VERSION ""

NS_ :

BS_:

BU_: CLU AMP H_U CGW TMU

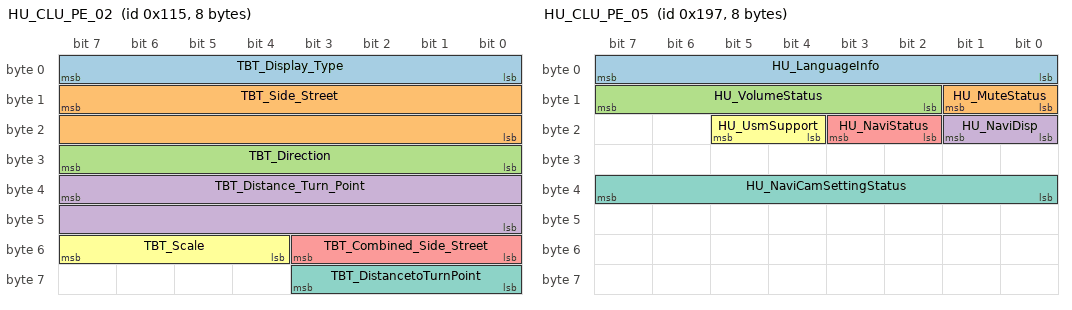
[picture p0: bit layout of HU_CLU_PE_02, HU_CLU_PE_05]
BO_ 277 HU_CLU_PE_02: 8 H_U
 SG_ TBT_Display_Type : 7|8@0+ (1,0) [0|0] ""  CLU
 SG_ TBT_Side_Street : 15|16@0+ (1,0) [0|0] ""  CLU
 SG_ TBT_Direction : 31|8@0+ (7.5,0) [0|352.5] "Degree"  CLU
 SG_ TBT_Distance_Turn_Point : 39|16@0+ (1,0) [0|0] "m"  CLU
 SG_ TBT_Combined_Side_Street : 51|4@0+ (1,0) [0|0] ""  CLU
 SG_ TBT_Scale : 55|4@0+ (1,0) [0|0] ""  CLU
 SG_ TBT_DistancetoTurnPoint : 59|4@0+ (1,0) [0|0] "times"  CLU

BO_ 406 HU_CLU_PE_04: 8 H_U
 SG_ HD_SPS_ChannelNo : 15|4@0+ (1,0) [0|0] ""  CLU
 SG_ SXM_ChannelNo : 25|10@0+ (1,0) [0|999] ""  AMP,CLU

BO_ 407 HU_CLU_PE_05: 8 H_U
 SG_ HU_LanguageInfo : 7|8@0+ (1,0) [0|0] ""  CGW,CLU
 SG_ HU_MuteStatus : 9|2@0+ (1,0) [0|0] ""  CLU
 SG_ HU_VolumeStatus : 15|6@0+ (1,0) [0|0] ""  CLU
 SG_ HU_NaviDisp : 17|2@0+ (1,0) [0|0] ""  CLU
 SG_ HU_NaviStatus : 19|2@0+ (1,0) [0|0] ""  CGW,CLU
 SG_ HU_UsmSupport : 21|2@0+ (1,0) [0|0] ""  CLU
 SG_ HU_NaviCamSettingStatus : 39|8@0+ (1,0) [0|0] ""  CGW,CLU

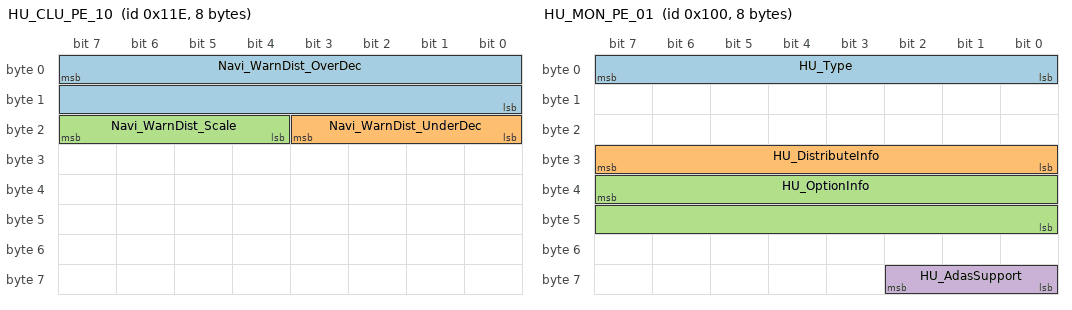
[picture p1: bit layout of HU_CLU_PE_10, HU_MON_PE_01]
BO_ 286 HU_CLU_PE_10: 8 H_U
 SG_ Navi_WarnDist_OverDec : 7|16@0+ (1,0) [0|0] ""  CLU
 SG_ Navi_WarnDist_UnderDec : 19|4@0+ (1,0) [0|0] ""  CLU
 SG_ Navi_WarnDist_Scale : 23|4@0+ (1,0) [0|0] ""  CLU

BO_ 256 HU_MON_PE_01: 8 H_U
 SG_ HU_Type : 7|8@0+ (1,0) [0|0] ""  AMP,CGW,CLU
 SG_ HU_DistributeInfo : 31|8@0+ (1,0) [0|0] ""  AMP,CGW,CLU
 SG_ HU_OptionInfo : 39|16@0+ (1,0) [0|0] ""  AMP,CGW,CLU
 SG_ HU_AdasSupport : 58|3@0+ (1,0) [0|0] ""  CGW,CLU

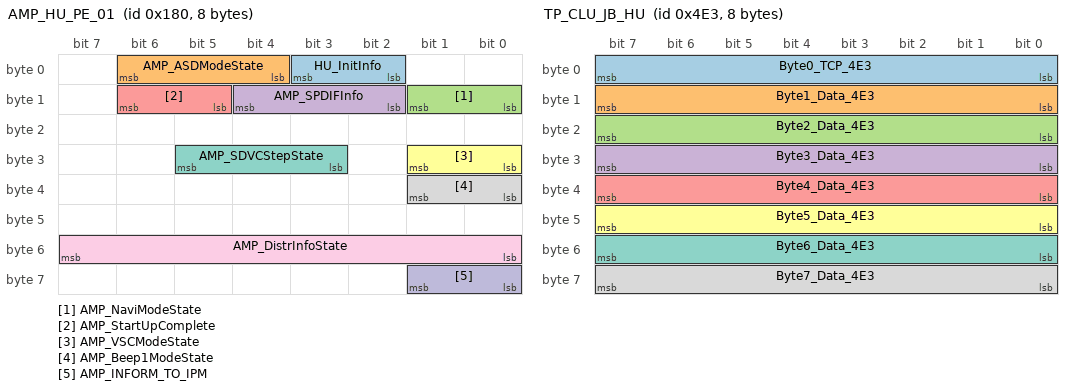
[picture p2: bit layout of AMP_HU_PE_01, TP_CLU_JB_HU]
BO_ 384 AMP_HU_PE_01: 8 AMP
 SG_ HU_InitInfo : 3|2@0+ (1,0) [0|0] ""  CLU,H_U
 SG_ AMP_ASDModeState : 6|3@0+ (1,0) [0|0] ""  CLU,H_U
 SG_ AMP_NaviModeState : 9|2@0+ (1,0) [0|0] ""  CLU,H_U
 SG_ AMP_SPDIFInfo : 12|3@0+ (1,0) [0|0] ""  CLU,H_U
 SG_ AMP_StartUpComplete : 14|2@0+ (1,0) [0|0] ""  CLU,H_U
 SG_ AMP_VSCModeState : 25|2@0+ (1,0) [0|0] ""  CLU,H_U
 SG_ AMP_SDVCStepState : 29|3@0+ (1,0) [0|0] ""  CLU,H_U
 SG_ AMP_Beep1ModeState : 33|2@0+ (1,0) [0|0] ""  CLU,H_U
 SG_ AMP_DistrInfoState : 55|8@0+ (1,0) [0|0] ""  CLU,H_U
 SG_ AMP_INFORM_TO_IPM : 57|2@0+ (1,0) [0|0] ""  CGW,CLU,H_U

BO_ 1251 TP_CLU_JB_HU: 8 CLU
 SG_ Byte0_TCP_4E3 : 7|8@0+ (1,0) [0|0] ""  H_U
 SG_ Byte1_Data_4E3 : 15|8@0+ (1,0) [0|0] ""  H_U
 SG_ Byte2_Data_4E3 : 23|8@0+ (1,0) [0|0] ""  H_U
 SG_ Byte3_Data_4E3 : 31|8@0+ (1,0) [0|0] ""  H_U
 SG_ Byte4_Data_4E3 : 39|8@0+ (1,0) [0|0] ""  H_U
 SG_ Byte5_Data_4E3 : 47|8@0+ (1,0) [0|0] ""  H_U
 SG_ Byte6_Data_4E3 : 55|8@0+ (1,0) [0|0] ""  H_U
 SG_ Byte7_Data_4E3 : 63|8@0+ (1,0) [0|0] ""  H_U

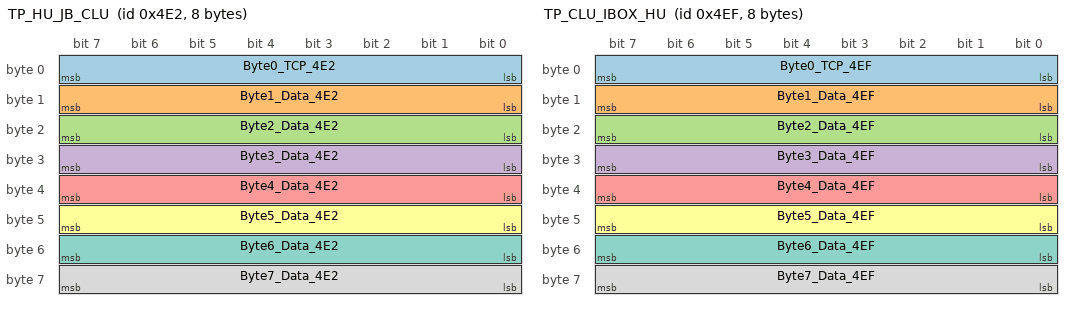
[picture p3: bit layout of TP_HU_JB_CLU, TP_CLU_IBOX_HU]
BO_ 1250 TP_HU_JB_CLU: 8 H_U
 SG_ Byte0_TCP_4E2 : 7|8@0+ (1,0) [0|0] ""  CLU
 SG_ Byte1_Data_4E2 : 15|8@0+ (1,0) [0|0] ""  CLU
 SG_ Byte2_Data_4E2 : 23|8@0+ (1,0) [0|0] ""  CLU
 SG_ Byte3_Data_4E2 : 31|8@0+ (1,0) [0|0] ""  CLU
 SG_ Byte4_Data_4E2 : 39|8@0+ (1,0) [0|0] ""  CLU
 SG_ Byte5_Data_4E2 : 47|8@0+ (1,0) [0|0] ""  CLU
 SG_ Byte6_Data_4E2 : 55|8@0+ (1,0) [0|0] ""  CLU
 SG_ Byte7_Data_4E2 : 63|8@0+ (1,0) [0|0] ""  CLU

BO_ 1263 TP_CLU_IBOX_HU: 8 CLU
 SG_ Byte0_TCP_4EF : 7|8@0+ (1,0) [0|0] ""  H_U
 SG_ Byte1_Data_4EF : 15|8@0+ (1,0) [0|0] ""  H_U
 SG_ Byte2_Data_4EF : 23|8@0+ (1,0) [0|0] ""  H_U
 SG_ Byte3_Data_4EF : 31|8@0+ (1,0) [0|0] ""  H_U
 SG_ Byte4_Data_4EF : 39|8@0+ (1,0) [0|0] ""  H_U
 SG_ Byte5_Data_4EF : 47|8@0+ (1,0) [0|0] ""  H_U
 SG_ Byte6_Data_4EF : 55|8@0+ (1,0) [0|0] ""  H_U
 SG_ Byte7_Data_4EF : 63|8@0+ (1,0) [0|0] ""  H_U

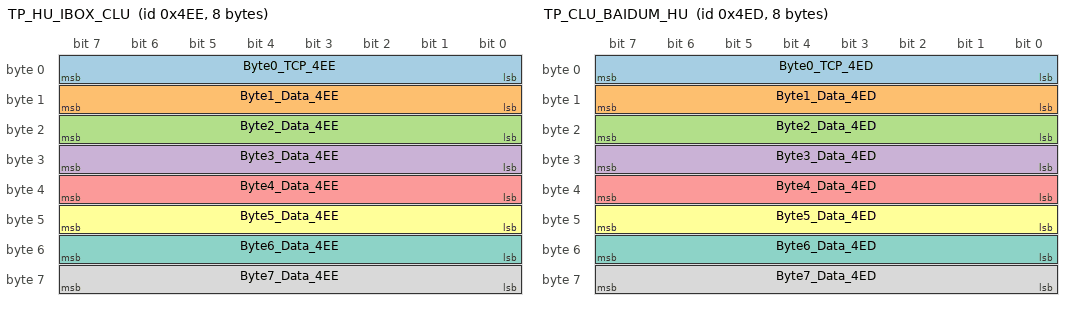
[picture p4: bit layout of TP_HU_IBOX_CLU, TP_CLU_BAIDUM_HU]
BO_ 1262 TP_HU_IBOX_CLU: 8 H_U
 SG_ Byte0_TCP_4EE : 7|8@0+ (1,0) [0|0] ""  CLU
 SG_ Byte1_Data_4EE : 15|8@0+ (1,0) [0|0] ""  CLU
 SG_ Byte2_Data_4EE : 23|8@0+ (1,0) [0|0] ""  CLU
 SG_ Byte3_Data_4EE : 31|8@0+ (1,0) [0|0] ""  CLU
 SG_ Byte4_Data_4EE : 39|8@0+ (1,0) [0|0] ""  CLU
 SG_ Byte5_Data_4EE : 47|8@0+ (1,0) [0|0] ""  CLU
 SG_ Byte6_Data_4EE : 55|8@0+ (1,0) [0|0] ""  CLU
 SG_ Byte7_Data_4EE : 63|8@0+ (1,0) [0|0] ""  CLU

BO_ 1261 TP_CLU_BAIDUM_HU: 8 CLU
 SG_ Byte0_TCP_4ED : 7|8@0+ (1,0) [0|0] ""  H_U
 SG_ Byte1_Data_4ED : 15|8@0+ (1,0) [0|0] ""  H_U
 SG_ Byte2_Data_4ED : 23|8@0+ (1,0) [0|0] ""  H_U
 SG_ Byte3_Data_4ED : 31|8@0+ (1,0) [0|0] ""  H_U
 SG_ Byte4_Data_4ED : 39|8@0+ (1,0) [0|0] ""  H_U
 SG_ Byte5_Data_4ED : 47|8@0+ (1,0) [0|0] ""  H_U
 SG_ Byte6_Data_4ED : 55|8@0+ (1,0) [0|0] ""  H_U
 SG_ Byte7_Data_4ED : 63|8@0+ (1,0) [0|0] ""  H_U

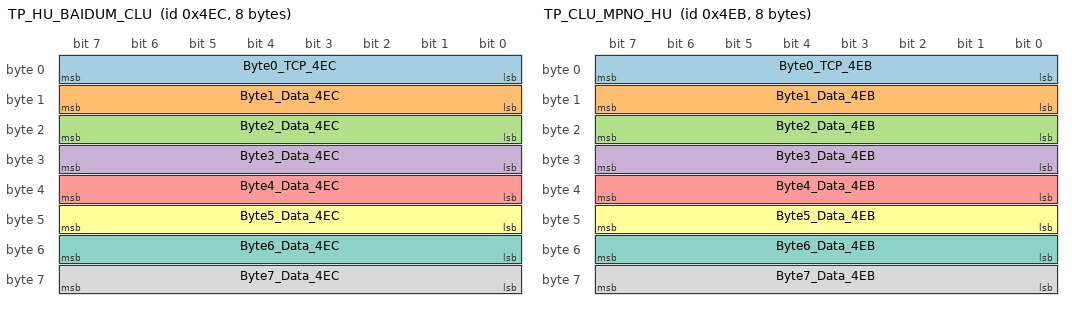
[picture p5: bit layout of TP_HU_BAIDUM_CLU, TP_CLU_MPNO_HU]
BO_ 1260 TP_HU_BAIDUM_CLU: 8 H_U
 SG_ Byte0_TCP_4EC : 7|8@0+ (1,0) [0|0] ""  CLU
 SG_ Byte1_Data_4EC : 15|8@0+ (1,0) [0|0] ""  CLU
 SG_ Byte2_Data_4EC : 23|8@0+ (1,0) [0|0] ""  CLU
 SG_ Byte3_Data_4EC : 31|8@0+ (1,0) [0|0] ""  CLU
 SG_ Byte4_Data_4EC : 39|8@0+ (1,0) [0|0] ""  CLU
 SG_ Byte5_Data_4EC : 47|8@0+ (1,0) [0|0] ""  CLU
 SG_ Byte6_Data_4EC : 55|8@0+ (1,0) [0|0] ""  CLU
 SG_ Byte7_Data_4EC : 63|8@0+ (1,0) [0|0] ""  CLU

BO_ 1259 TP_CLU_MPNO_HU: 8 CLU
 SG_ Byte0_TCP_4EB : 7|8@0+ (1,0) [0|0] ""  H_U
 SG_ Byte1_Data_4EB : 15|8@0+ (1,0) [0|0] ""  H_U
 SG_ Byte2_Data_4EB : 23|8@0+ (1,0) [0|0] ""  H_U
 SG_ Byte3_Data_4EB : 31|8@0+ (1,0) [0|0] ""  H_U
 SG_ Byte4_Data_4EB : 39|8@0+ (1,0) [0|0] ""  H_U
 SG_ Byte5_Data_4EB : 47|8@0+ (1,0) [0|0] ""  H_U
 SG_ Byte6_Data_4EB : 55|8@0+ (1,0) [0|0] ""  H_U
 SG_ Byte7_Data_4EB : 63|8@0+ (1,0) [0|0] ""  H_U

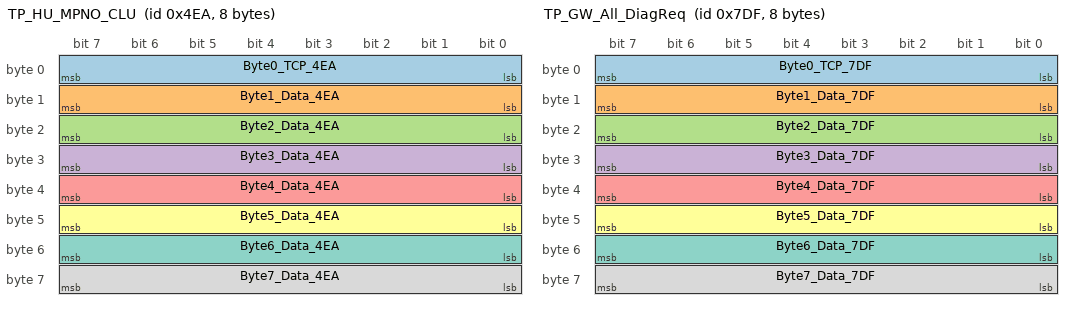
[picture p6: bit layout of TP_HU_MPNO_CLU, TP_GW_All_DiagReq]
BO_ 1258 TP_HU_MPNO_CLU: 8 H_U
 SG_ Byte0_TCP_4EA : 7|8@0+ (1,0) [0|0] ""  CLU
 SG_ Byte1_Data_4EA : 15|8@0+ (1,0) [0|0] ""  CLU
 SG_ Byte2_Data_4EA : 23|8@0+ (1,0) [0|0] ""  CLU
 SG_ Byte3_Data_4EA : 31|8@0+ (1,0) [0|0] ""  CLU
 SG_ Byte4_Data_4EA : 39|8@0+ (1,0) [0|0] ""  CLU
 SG_ Byte5_Data_4EA : 47|8@0+ (1,0) [0|0] ""  CLU
 SG_ Byte6_Data_4EA : 55|8@0+ (1,0) [0|0] ""  CLU
 SG_ Byte7_Data_4EA : 63|8@0+ (1,0) [0|0] ""  CLU

BO_ 2015 TP_GW_All_DiagReq: 8 CGW
 SG_ Byte0_TCP_7DF : 7|8@0+ (1,0) [0|0] ""  AMP,CLU,H_U,TMU
 SG_ Byte1_Data_7DF : 15|8@0+ (1,0) [0|0] ""  AMP,CLU,H_U,TMU
 SG_ Byte2_Data_7DF : 23|8@0+ (1,0) [0|0] ""  AMP,CLU,H_U,TMU
 SG_ Byte3_Data_7DF : 31|8@0+ (1,0) [0|0] ""  AMP,CLU,H_U,TMU
 SG_ Byte4_Data_7DF : 39|8@0+ (1,0) [0|0] ""  AMP,CLU,H_U,TMU
 SG_ Byte5_Data_7DF : 47|8@0+ (1,0) [0|0] ""  AMP,CLU,H_U,TMU
 SG_ Byte6_Data_7DF : 55|8@0+ (1,0) [0|0] ""  AMP,CLU,H_U,TMU
 SG_ Byte7_Data_7DF : 63|8@0+ (1,0) [0|0] ""  AMP,CLU,H_U,TMU

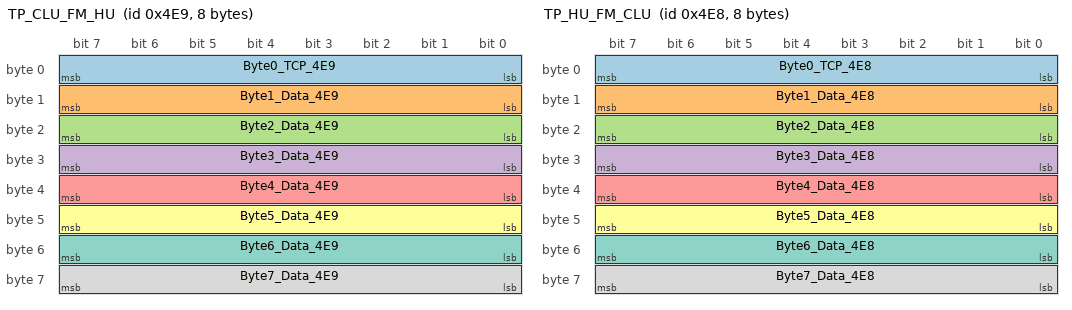
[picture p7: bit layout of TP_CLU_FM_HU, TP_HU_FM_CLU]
BO_ 1257 TP_CLU_FM_HU: 8 CLU
 SG_ Byte0_TCP_4E9 : 7|8@0+ (1,0) [0|0] ""  H_U
 SG_ Byte1_Data_4E9 : 15|8@0+ (1,0) [0|0] ""  H_U
 SG_ Byte2_Data_4E9 : 23|8@0+ (1,0) [0|0] ""  H_U
 SG_ Byte3_Data_4E9 : 31|8@0+ (1,0) [0|0] ""  H_U
 SG_ Byte4_Data_4E9 : 39|8@0+ (1,0) [0|0] ""  H_U
 SG_ Byte5_Data_4E9 : 47|8@0+ (1,0) [0|0] ""  H_U
 SG_ Byte6_Data_4E9 : 55|8@0+ (1,0) [0|0] ""  H_U
 SG_ Byte7_Data_4E9 : 63|8@0+ (1,0) [0|0] ""  H_U

BO_ 1256 TP_HU_FM_CLU: 8 H_U
 SG_ Byte0_TCP_4E8 : 7|8@0+ (1,0) [0|0] ""  CLU
 SG_ Byte1_Data_4E8 : 15|8@0+ (1,0) [0|0] ""  CLU
 SG_ Byte2_Data_4E8 : 23|8@0+ (1,0) [0|0] ""  CLU
 SG_ Byte3_Data_4E8 : 31|8@0+ (1,0) [0|0] ""  CLU
 SG_ Byte4_Data_4E8 : 39|8@0+ (1,0) [0|0] ""  CLU
 SG_ Byte5_Data_4E8 : 47|8@0+ (1,0) [0|0] ""  CLU
 SG_ Byte6_Data_4E8 : 55|8@0+ (1,0) [0|0] ""  CLU
 SG_ Byte7_Data_4E8 : 63|8@0+ (1,0) [0|0] ""  CLU

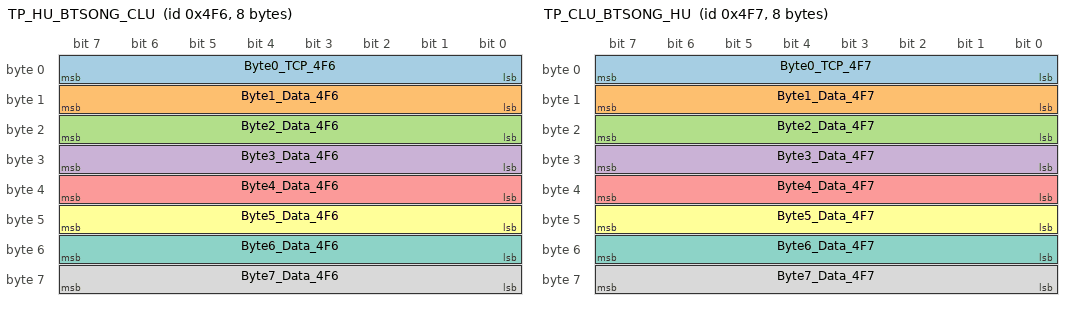
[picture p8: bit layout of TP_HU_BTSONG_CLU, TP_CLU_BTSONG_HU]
BO_ 1270 TP_HU_BTSONG_CLU: 8 H_U
 SG_ Byte0_TCP_4F6 : 7|8@0+ (1,0) [0|0] ""  CLU
 SG_ Byte1_Data_4F6 : 15|8@0+ (1,0) [0|0] ""  CLU
 SG_ Byte2_Data_4F6 : 23|8@0+ (1,0) [0|0] ""  CLU
 SG_ Byte3_Data_4F6 : 31|8@0+ (1,0) [0|0] ""  CLU
 SG_ Byte4_Data_4F6 : 39|8@0+ (1,0) [0|0] ""  CLU
 SG_ Byte5_Data_4F6 : 47|8@0+ (1,0) [0|0] ""  CLU
 SG_ Byte6_Data_4F6 : 55|8@0+ (1,0) [0|0] ""  CLU
 SG_ Byte7_Data_4F6 : 63|8@0+ (1,0) [0|0] ""  CLU

BO_ 1271 TP_CLU_BTSONG_HU: 8 CLU
 SG_ Byte0_TCP_4F7 : 7|8@0+ (1,0) [0|0] ""  H_U
 SG_ Byte1_Data_4F7 : 15|8@0+ (1,0) [0|0] ""  H_U
 SG_ Byte2_Data_4F7 : 23|8@0+ (1,0) [0|0] ""  H_U
 SG_ Byte3_Data_4F7 : 31|8@0+ (1,0) [0|0] ""  H_U
 SG_ Byte4_Data_4F7 : 39|8@0+ (1,0) [0|0] ""  H_U
 SG_ Byte5_Data_4F7 : 47|8@0+ (1,0) [0|0] ""  H_U
 SG_ Byte6_Data_4F7 : 55|8@0+ (1,0) [0|0] ""  H_U
 SG_ Byte7_Data_4F7 : 63|8@0+ (1,0) [0|0] ""  H_U

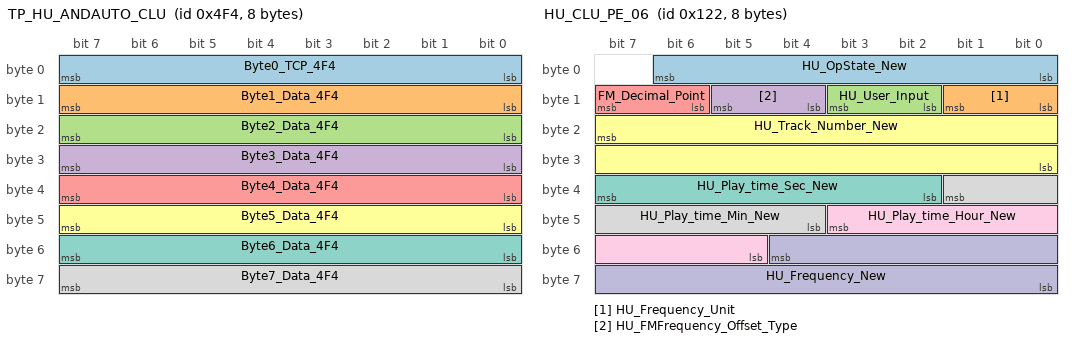
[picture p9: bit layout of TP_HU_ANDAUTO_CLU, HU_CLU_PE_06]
BO_ 1268 TP_HU_ANDAUTO_CLU: 8 H_U
 SG_ Byte0_TCP_4F4 : 7|8@0+ (1,0) [0|0] ""  CLU
 SG_ Byte1_Data_4F4 : 15|8@0+ (1,0) [0|0] ""  CLU
 SG_ Byte2_Data_4F4 : 23|8@0+ (1,0) [0|0] ""  CLU
 SG_ Byte3_Data_4F4 : 31|8@0+ (1,0) [0|0] ""  CLU
 SG_ Byte4_Data_4F4 : 39|8@0+ (1,0) [0|0] ""  CLU
 SG_ Byte5_Data_4F4 : 47|8@0+ (1,0) [0|0] ""  CLU
 SG_ Byte6_Data_4F4 : 55|8@0+ (1,0) [0|0] ""  CLU
 SG_ Byte7_Data_4F4 : 63|8@0+ (1,0) [0|0] ""  CLU

BO_ 290 HU_CLU_PE_06: 8 H_U
 SG_ HU_OpState_New : 6|7@0+ (1,0) [0|0] ""  AMP,CLU
 SG_ HU_Frequency_Unit : 9|2@0+ (1,0) [0|0] ""  CLU
 SG_ HU_User_Input : 11|2@0+ (1,0) [0|0] ""  CLU
 SG_ HU_FMFrequency_Offset_Type : 13|2@0+ (1,0) [0|0] ""  AMP,CLU
 SG_ FM_Decimal_Point : 15|2@0+ (1,0) [0|0] ""  CLU
 SG_ HU_Track_Number_New : 23|16@0+ (1,0) [0|0] ""  CLU
 SG_ HU_Play_time_Sec_New : 39|6@0+ (1,0) [0|0] ""  CLU
 SG_ HU_Play_time_Min_New : 33|6@0+ (1,0) [0|0] ""  CLU
 SG_ HU_Play_time_Hour_New : 43|7@0+ (1,0) [0|0] ""  CLU
 SG_ HU_Frequency_New : 52|13@0+ (1,0) [0|0] ""  AMP,CLU

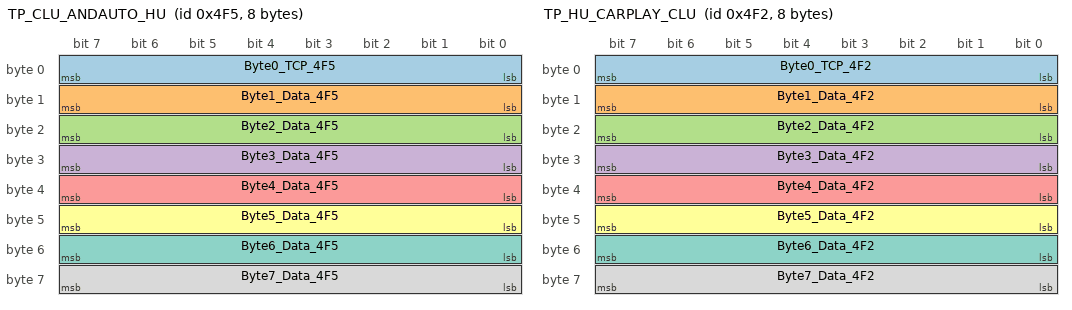
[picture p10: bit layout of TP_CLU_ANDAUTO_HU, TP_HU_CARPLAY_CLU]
BO_ 1269 TP_CLU_ANDAUTO_HU: 8 CLU
 SG_ Byte0_TCP_4F5 : 7|8@0+ (1,0) [0|0] ""  H_U
 SG_ Byte1_Data_4F5 : 15|8@0+ (1,0) [0|0] ""  H_U
 SG_ Byte2_Data_4F5 : 23|8@0+ (1,0) [0|0] ""  H_U
 SG_ Byte3_Data_4F5 : 31|8@0+ (1,0) [0|0] ""  H_U
 SG_ Byte4_Data_4F5 : 39|8@0+ (1,0) [0|0] ""  H_U
 SG_ Byte5_Data_4F5 : 47|8@0+ (1,0) [0|0] ""  H_U
 SG_ Byte6_Data_4F5 : 55|8@0+ (1,0) [0|0] ""  H_U
 SG_ Byte7_Data_4F5 : 63|8@0+ (1,0) [0|0] ""  H_U

BO_ 291 HU_CLU_PE_07: 8 H_U
 SG_ NV_Display_TG : 31|2@0+ (1,0) [0|0] ""  CLU
 SG_ TBT_BarGraph100Level : 63|8@0+ (1,0) [0|100] "%"  CLU

BO_ 1266 TP_HU_CARPLAY_CLU: 8 H_U
 SG_ Byte0_TCP_4F2 : 7|8@0+ (1,0) [0|0] ""  CLU
 SG_ Byte1_Data_4F2 : 15|8@0+ (1,0) [0|0] ""  CLU
 SG_ Byte2_Data_4F2 : 23|8@0+ (1,0) [0|0] ""  CLU
 SG_ Byte3_Data_4F2 : 31|8@0+ (1,0) [0|0] ""  CLU
 SG_ Byte4_Data_4F2 : 39|8@0+ (1,0) [0|0] ""  CLU
 SG_ Byte5_Data_4F2 : 47|8@0+ (1,0) [0|0] ""  CLU
 SG_ Byte6_Data_4F2 : 55|8@0+ (1,0) [0|0] ""  CLU
 SG_ Byte7_Data_4F2 : 63|8@0+ (1,0) [0|0] ""  CLU

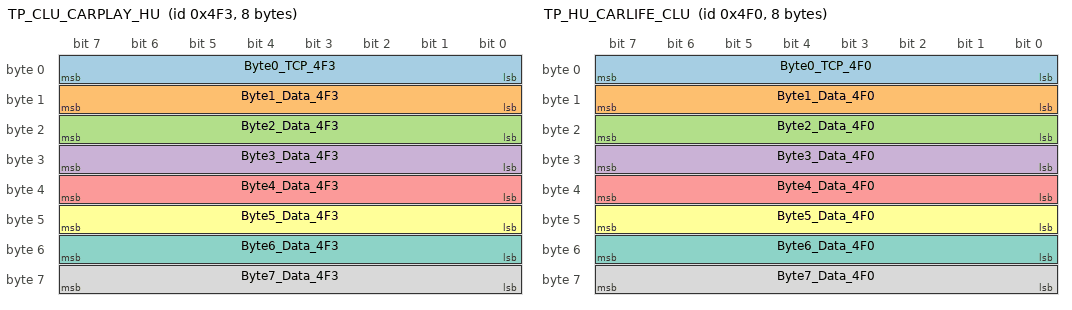
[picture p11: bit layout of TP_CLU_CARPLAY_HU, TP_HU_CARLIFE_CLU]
BO_ 1267 TP_CLU_CARPLAY_HU: 8 CLU
 SG_ Byte0_TCP_4F3 : 7|8@0+ (1,0) [0|0] ""  H_U
 SG_ Byte1_Data_4F3 : 15|8@0+ (1,0) [0|0] ""  H_U
 SG_ Byte2_Data_4F3 : 23|8@0+ (1,0) [0|0] ""  H_U
 SG_ Byte3_Data_4F3 : 31|8@0+ (1,0) [0|0] ""  H_U
 SG_ Byte4_Data_4F3 : 39|8@0+ (1,0) [0|0] ""  H_U
 SG_ Byte5_Data_4F3 : 47|8@0+ (1,0) [0|0] ""  H_U
 SG_ Byte6_Data_4F3 : 55|8@0+ (1,0) [0|0] ""  H_U
 SG_ Byte7_Data_4F3 : 63|8@0+ (1,0) [0|0] ""  H_U

BO_ 54 HU_DATC_E_03: 8 H_U
 SG_ HU_DATC_DrTempSetC : 7|8@0+ (0.5,14) [15|32] "¡É"  CGW,CLU
 SG_ HU_DATC_DrTempSetF : 15|8@0+ (1,56) [58|90] "¢µ"  CGW,CLU

BO_ 1264 TP_HU_CARLIFE_CLU: 8 H_U
 SG_ Byte0_TCP_4F0 : 7|8@0+ (1,0) [0|0] ""  CLU
 SG_ Byte1_Data_4F0 : 15|8@0+ (1,0) [0|0] ""  CLU
 SG_ Byte2_Data_4F0 : 23|8@0+ (1,0) [0|0] ""  CLU
 SG_ Byte3_Data_4F0 : 31|8@0+ (1,0) [0|0] ""  CLU
 SG_ Byte4_Data_4F0 : 39|8@0+ (1,0) [0|0] ""  CLU
 SG_ Byte5_Data_4F0 : 47|8@0+ (1,0) [0|0] ""  CLU
 SG_ Byte6_Data_4F0 : 55|8@0+ (1,0) [0|0] ""  CLU
 SG_ Byte7_Data_4F0 : 63|8@0+ (1,0) [0|0] ""  CLU

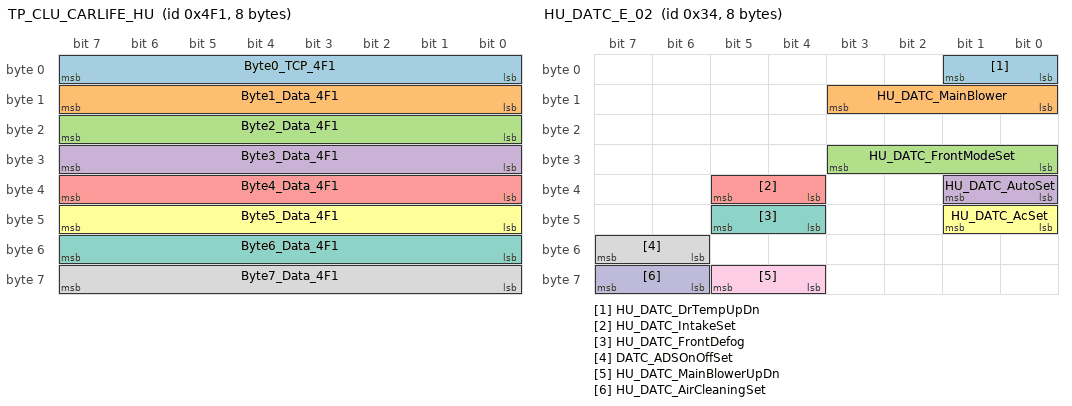
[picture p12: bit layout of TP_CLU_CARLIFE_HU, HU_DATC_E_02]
BO_ 1265 TP_CLU_CARLIFE_HU: 8 CLU
 SG_ Byte0_TCP_4F1 : 7|8@0+ (1,0) [0|0] ""  H_U
 SG_ Byte1_Data_4F1 : 15|8@0+ (1,0) [0|0] ""  H_U
 SG_ Byte2_Data_4F1 : 23|8@0+ (1,0) [0|0] ""  H_U
 SG_ Byte3_Data_4F1 : 31|8@0+ (1,0) [0|0] ""  H_U
 SG_ Byte4_Data_4F1 : 39|8@0+ (1,0) [0|0] ""  H_U
 SG_ Byte5_Data_4F1 : 47|8@0+ (1,0) [0|0] ""  H_U
 SG_ Byte6_Data_4F1 : 55|8@0+ (1,0) [0|0] ""  H_U
 SG_ Byte7_Data_4F1 : 63|8@0+ (1,0) [0|0] ""  H_U

BO_ 52 HU_DATC_E_02: 8 H_U
 SG_ HU_DATC_DrTempUpDn : 1|2@0+ (1,0) [0|0] ""  CGW,CLU
 SG_ HU_DATC_MainBlower : 11|4@0+ (1,0) [0|0] ""  CGW,CLU
 SG_ HU_DATC_FrontModeSet : 27|4@0+ (1,0) [0|0] ""  CGW,CLU
 SG_ HU_DATC_AutoSet : 33|2@0+ (1,0) [0|0] ""  CGW,CLU
 SG_ HU_DATC_IntakeSet : 37|2@0+ (1,0) [0|0] ""  CGW,CLU
 SG_ HU_DATC_AcSet : 41|2@0+ (1,0) [0|0] ""  CGW,CLU
 SG_ HU_DATC_FrontDefog : 45|2@0+ (1,0) [0|0] ""  CGW,CLU
 SG_ DATC_ADSOnOffSet : 55|2@0+ (1,0) [0|0] ""  CGW,CLU
 SG_ HU_DATC_MainBlowerUpDn : 61|2@0+ (1,0) [0|0] ""  CGW,CLU
 SG_ HU_DATC_AirCleaningSet : 63|2@0+ (1,0) [0|0] ""  CGW,CLU

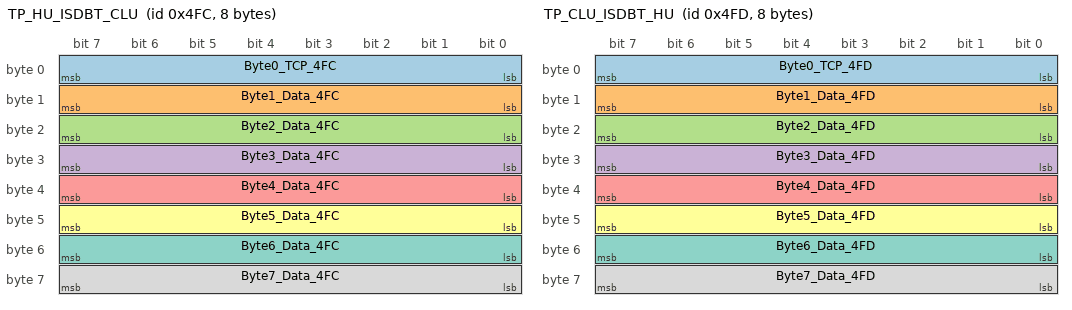
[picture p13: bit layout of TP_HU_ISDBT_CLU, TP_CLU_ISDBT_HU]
BO_ 1276 TP_HU_ISDBT_CLU: 8 H_U
 SG_ Byte0_TCP_4FC : 7|8@0+ (1,0) [0|0] ""  CLU
 SG_ Byte1_Data_4FC : 15|8@0+ (1,0) [0|0] ""  CLU
 SG_ Byte2_Data_4FC : 23|8@0+ (1,0) [0|0] ""  CLU
 SG_ Byte3_Data_4FC : 31|8@0+ (1,0) [0|0] ""  CLU
 SG_ Byte4_Data_4FC : 39|8@0+ (1,0) [0|0] ""  CLU
 SG_ Byte5_Data_4FC : 47|8@0+ (1,0) [0|0] ""  CLU
 SG_ Byte6_Data_4FC : 55|8@0+ (1,0) [0|0] ""  CLU
 SG_ Byte7_Data_4FC : 63|8@0+ (1,0) [0|0] ""  CLU

BO_ 1277 TP_CLU_ISDBT_HU: 8 CLU
 SG_ Byte0_TCP_4FD : 7|8@0+ (1,0) [0|0] ""  H_U
 SG_ Byte1_Data_4FD : 15|8@0+ (1,0) [0|0] ""  H_U
 SG_ Byte2_Data_4FD : 23|8@0+ (1,0) [0|0] ""  H_U
 SG_ Byte3_Data_4FD : 31|8@0+ (1,0) [0|0] ""  H_U
 SG_ Byte4_Data_4FD : 39|8@0+ (1,0) [0|0] ""  H_U
 SG_ Byte5_Data_4FD : 47|8@0+ (1,0) [0|0] ""  H_U
 SG_ Byte6_Data_4FD : 55|8@0+ (1,0) [0|0] ""  H_U
 SG_ Byte7_Data_4FD : 63|8@0+ (1,0) [0|0] ""  H_U

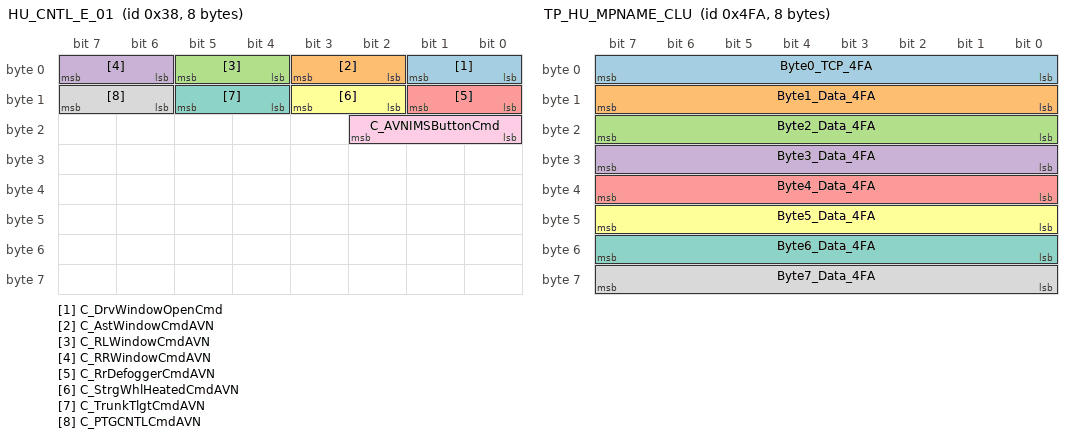
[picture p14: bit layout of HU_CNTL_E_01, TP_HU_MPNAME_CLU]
BO_ 56 HU_CNTL_E_01: 8 H_U
 SG_ C_DrvWindowOpenCmd : 1|2@0+ (1,0) [0|0] ""  CGW,CLU
 SG_ C_AstWindowCmdAVN : 3|2@0+ (1,0) [0|0] ""  CGW,CLU
 SG_ C_RLWindowCmdAVN : 5|2@0+ (1,0) [0|0] ""  CGW,CLU
 SG_ C_RRWindowCmdAVN : 7|2@0+ (1,0) [0|0] ""  CGW,CLU
 SG_ C_RrDefoggerCmdAVN : 9|2@0+ (1,0) [0|0] ""  CGW,CLU
 SG_ C_StrgWhlHeatedCmdAVN : 11|2@0+ (1,0) [0|0] ""  CGW,CLU
 SG_ C_TrunkTlgtCmdAVN : 13|2@0+ (1,0) [0|0] ""  CGW,CLU
 SG_ C_PTGCNTLCmdAVN : 15|2@0+ (1,0) [0|0] ""  CGW,CLU
 SG_ C_AVNIMSButtonCmd : 18|3@0+ (1,0) [0|0] ""  CGW,CLU

BO_ 1274 TP_HU_MPNAME_CLU: 8 H_U
 SG_ Byte0_TCP_4FA : 7|8@0+ (1,0) [0|0] ""  CLU
 SG_ Byte1_Data_4FA : 15|8@0+ (1,0) [0|0] ""  CLU
 SG_ Byte2_Data_4FA : 23|8@0+ (1,0) [0|0] ""  CLU
 SG_ Byte3_Data_4FA : 31|8@0+ (1,0) [0|0] ""  CLU
 SG_ Byte4_Data_4FA : 39|8@0+ (1,0) [0|0] ""  CLU
 SG_ Byte5_Data_4FA : 47|8@0+ (1,0) [0|0] ""  CLU
 SG_ Byte6_Data_4FA : 55|8@0+ (1,0) [0|0] ""  CLU
 SG_ Byte7_Data_4FA : 63|8@0+ (1,0) [0|0] ""  CLU

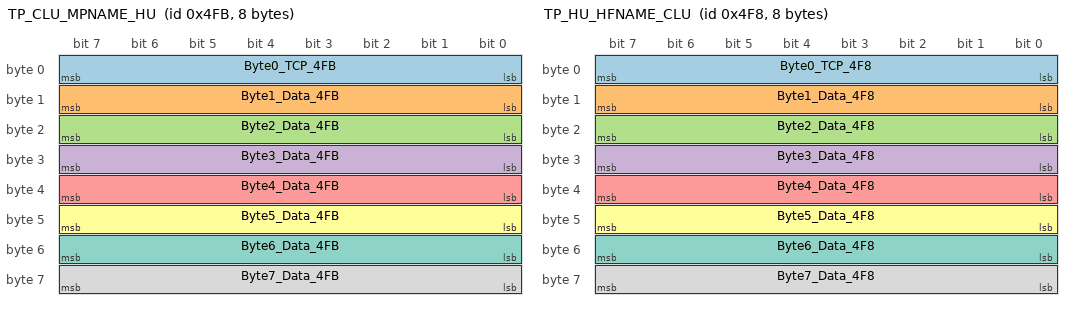
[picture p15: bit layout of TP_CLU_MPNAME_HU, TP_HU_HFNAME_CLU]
BO_ 1275 TP_CLU_MPNAME_HU: 8 CLU
 SG_ Byte0_TCP_4FB : 7|8@0+ (1,0) [0|0] ""  H_U
 SG_ Byte1_Data_4FB : 15|8@0+ (1,0) [0|0] ""  H_U
 SG_ Byte2_Data_4FB : 23|8@0+ (1,0) [0|0] ""  H_U
 SG_ Byte3_Data_4FB : 31|8@0+ (1,0) [0|0] ""  H_U
 SG_ Byte4_Data_4FB : 39|8@0+ (1,0) [0|0] ""  H_U
 SG_ Byte5_Data_4FB : 47|8@0+ (1,0) [0|0] ""  H_U
 SG_ Byte6_Data_4FB : 55|8@0+ (1,0) [0|0] ""  H_U
 SG_ Byte7_Data_4FB : 63|8@0+ (1,0) [0|0] ""  H_U

BO_ 1272 TP_HU_HFNAME_CLU: 8 H_U
 SG_ Byte0_TCP_4F8 : 7|8@0+ (1,0) [0|0] ""  CLU
 SG_ Byte1_Data_4F8 : 15|8@0+ (1,0) [0|0] ""  CLU
 SG_ Byte2_Data_4F8 : 23|8@0+ (1,0) [0|0] ""  CLU
 SG_ Byte3_Data_4F8 : 31|8@0+ (1,0) [0|0] ""  CLU
 SG_ Byte4_Data_4F8 : 39|8@0+ (1,0) [0|0] ""  CLU
 SG_ Byte5_Data_4F8 : 47|8@0+ (1,0) [0|0] ""  CLU
 SG_ Byte6_Data_4F8 : 55|8@0+ (1,0) [0|0] ""  CLU
 SG_ Byte7_Data_4F8 : 63|8@0+ (1,0) [0|0] ""  CLU

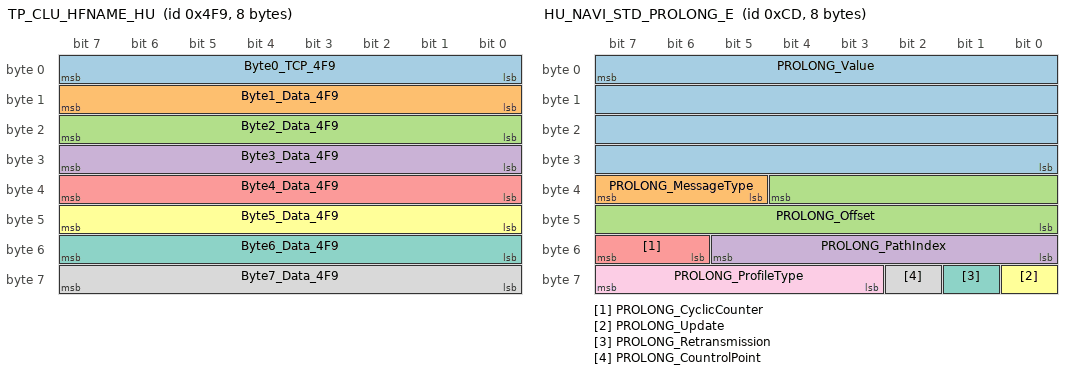
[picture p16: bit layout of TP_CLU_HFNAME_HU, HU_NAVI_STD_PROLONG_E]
BO_ 1273 TP_CLU_HFNAME_HU: 8 CLU
 SG_ Byte0_TCP_4F9 : 7|8@0+ (1,0) [0|0] ""  H_U
 SG_ Byte1_Data_4F9 : 15|8@0+ (1,0) [0|0] ""  H_U
 SG_ Byte2_Data_4F9 : 23|8@0+ (1,0) [0|0] ""  H_U
 SG_ Byte3_Data_4F9 : 31|8@0+ (1,0) [0|0] ""  H_U
 SG_ Byte4_Data_4F9 : 39|8@0+ (1,0) [0|0] ""  H_U
 SG_ Byte5_Data_4F9 : 47|8@0+ (1,0) [0|0] ""  H_U
 SG_ Byte6_Data_4F9 : 55|8@0+ (1,0) [0|0] ""  H_U
 SG_ Byte7_Data_4F9 : 63|8@0+ (1,0) [0|0] ""  H_U

BO_ 205 HU_NAVI_STD_PROLONG_E: 8 H_U
 SG_ PROLONG_Value : 7|32@0+ (1,0) [0|0] ""  CGW,CLU
 SG_ PROLONG_MessageType : 39|3@0+ (1,0) [0|0] ""  CGW,CLU
 SG_ PROLONG_Offset : 36|13@0+ (1,0) [0|0] "m"  CGW,CLU
 SG_ PROLONG_PathIndex : 53|6@0+ (1,0) [0|0] ""  CGW,CLU
 SG_ PROLONG_CyclicCounter : 55|2@0+ (1,0) [0|0] ""  CGW,CLU
 SG_ PROLONG_Update : 56|1@0+ (1,0) [0|0] ""  CGW,CLU
 SG_ PROLONG_Retransmission : 57|1@0+ (1,0) [0|0] ""  CGW,CLU
 SG_ PROLONG_CountrolPoint : 58|1@0+ (1,0) [0|0] ""  CGW,CLU
 SG_ PROLONG_ProfileType : 63|5@0+ (1,0) [0|0] ""  CGW,CLU

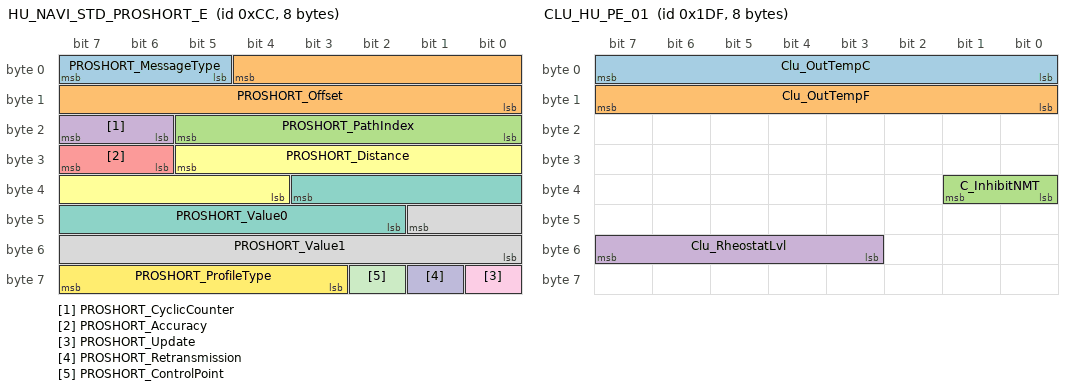
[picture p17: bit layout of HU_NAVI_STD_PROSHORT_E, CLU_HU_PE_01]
BO_ 204 HU_NAVI_STD_PROSHORT_E: 8 H_U
 SG_ PROSHORT_MessageType : 7|3@0+ (1,0) [0|0] ""  CGW,CLU
 SG_ PROSHORT_Offset : 4|13@0+ (1,0) [0|0] "m"  CGW,CLU
 SG_ PROSHORT_PathIndex : 21|6@0+ (1,0) [0|0] ""  CGW,CLU
 SG_ PROSHORT_CyclicCounter : 23|2@0+ (1,0) [0|0] ""  CGW,CLU
 SG_ PROSHORT_Accuracy : 31|2@0+ (1,0) [0|0] ""  CGW,CLU
 SG_ PROSHORT_Distance : 29|10@0+ (1,0) [0|0] "m"  CGW,CLU
 SG_ PROSHORT_Value0 : 35|10@0+ (1,0) [0|0] ""  CGW,CLU
 SG_ PROSHORT_Value1 : 41|10@0+ (1,0) [0|0] ""  CGW,CLU
 SG_ PROSHORT_Update : 56|1@0+ (1,0) [0|0] ""  CGW,CLU
 SG_ PROSHORT_Retransmission : 57|1@0+ (1,0) [0|0] ""  CGW,CLU
 SG_ PROSHORT_ControlPoint : 58|1@0+ (1,0) [0|0] ""  CGW,CLU
 SG_ PROSHORT_ProfileType : 63|5@0+ (1,0) [0|0] ""  CGW,CLU

BO_ 479 CLU_HU_PE_01: 8 CLU
 SG_ Clu_OutTempC : 7|8@0+ (1,-40) [0|0] "¡É"  CGW,H_U
 SG_ Clu_OutTempF : 15|8@0+ (1,-40) [0|0] "¢µ"  CGW,H_U
 SG_ C_InhibitNMT : 33|2@0+ (1,0) [0|0] ""  H_U
 SG_ Clu_RheostatLvl : 55|5@0+ (1,0) [0|0] ""  CGW,H_U

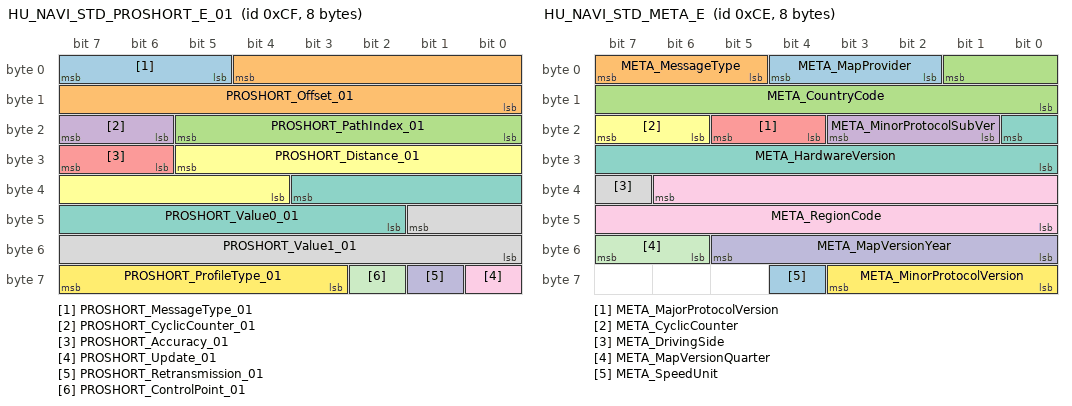
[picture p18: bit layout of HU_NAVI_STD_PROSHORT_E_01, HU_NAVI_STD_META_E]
BO_ 207 HU_NAVI_STD_PROSHORT_E_01: 8 H_U
 SG_ PROSHORT_MessageType_01 : 7|3@0+ (1,0) [0|0] ""  CGW,CLU
 SG_ PROSHORT_Offset_01 : 4|13@0+ (1,0) [0|0] "m"  CGW,CLU
 SG_ PROSHORT_PathIndex_01 : 21|6@0+ (1,0) [0|0] ""  CGW,CLU
 SG_ PROSHORT_CyclicCounter_01 : 23|2@0+ (1,0) [0|0] ""  CGW,CLU
 SG_ PROSHORT_Accuracy_01 : 31|2@0+ (1,0) [0|0] ""  CGW,CLU
 SG_ PROSHORT_Distance_01 : 29|10@0+ (1,0) [0|0] "m"  CGW,CLU
 SG_ PROSHORT_Value0_01 : 35|10@0+ (1,0) [0|0] ""  CGW,CLU
 SG_ PROSHORT_Value1_01 : 41|10@0+ (1,0) [0|0] ""  CGW,CLU
 SG_ PROSHORT_Update_01 : 56|1@0+ (1,0) [0|0] ""  CGW,CLU
 SG_ PROSHORT_Retransmission_01 : 57|1@0+ (1,0) [0|0] ""  CGW,CLU
 SG_ PROSHORT_ControlPoint_01 : 58|1@0+ (1,0) [0|0] ""  CGW,CLU
 SG_ PROSHORT_ProfileType_01 : 63|5@0+ (1,0) [0|0] ""  CGW,CLU

BO_ 206 HU_NAVI_STD_META_E: 8 H_U
 SG_ META_MapProvider : 4|3@0+ (1,0) [0|0] ""  CGW,CLU
 SG_ META_MessageType : 7|3@0+ (1,0) [0|0] ""  CGW,CLU
 SG_ META_CountryCode : 1|10@0+ (1,0) [0|0] ""  CGW,CLU
 SG_ META_MinorProtocolSubVer : 19|3@0+ (1,0) [0|0] ""  CGW,CLU
 SG_ META_MajorProtocolVersion : 21|2@0+ (1,0) [0|0] ""  CGW,CLU
 SG_ META_CyclicCounter : 23|2@0+ (1,0) [0|0] ""  CGW,CLU
 SG_ META_HardwareVersion : 16|9@0+ (1,0) [0|0] ""  CGW,CLU
 SG_ META_DrivingSide : 39|1@0+ (1,0) [0|0] ""  CGW,CLU
 SG_ META_RegionCode : 38|15@0+ (1,0) [0|0] ""  CGW,CLU
 SG_ META_MapVersionYear : 53|6@0+ (1,2000) [0|0] ""  CGW,CLU
 SG_ META_MapVersionQuarter : 55|2@0+ (1,0) [0|0] ""  CGW,CLU
 SG_ META_MinorProtocolVersion : 59|4@0+ (1,0) [0|0] ""  CGW,CLU
 SG_ META_SpeedUnit : 60|1@0+ (1,0) [0|0] ""  CGW,CLU

CM_ BO_ 384 "[PE] Periodic and On Event";
CM_ SG_ 384 HU_InitInfo "Information for External AMP Initiation status

0x1 : Request AMP Initialization

0x2 : AMP Initialization complted";
CM_ SG_ 384 AMP_ASDModeState "Information for current ASD(Active Sound Design, Virtual Engine Sound) Mode status
- Current AMP ASD mode is controlled by Driving Mode by itself";
CM_ SG_ 384 AMP_NaviModeState "Information for Current Navi Prompt Status
-Feedback from AMP_NaviMode(0x008)@H_U";
CM_ SG_ 384 AMP_SPDIFInfo "Information for SPIF output status
0x1: SPDIF PLL Unlock

0x2: PLL Lock & Null Data Received 

0x3:PLL Lock &  PCM Data Received 

0x4: PLL Lock & Compressed Data Received";
CM_ SG_ 384 AMP_StartUpComplete "the signal for informing intitial complete of external AMP

need for generating warning sound using external AMP";
CM_ SG_ 384 AMP_VSCModeState "Information for Vehicle Speed Compensation mode state";
CM_ SG_ 384 AMP_SDVCStepState "Information for current SDVC(Advanced VSC) mode state";
CM_ SG_ 384 AMP_Beep1ModeState "Information for Current Beep1 Mode Status(Touch Beep Mode)
For Harman AMP Only
-Feedback from AMP_Beep1Mode(0x008)@H_U";
CM_ SG_ 384 AMP_DistrInfoState "Information for current status of Region : Europe/North America/..
and Driver Position : RHD/LHD Positionning 
Feedback from HU_DistributeInfo@0x100";
CM_ SG_ 384 AMP_INFORM_TO_IPM "Information for Warning Sound Supportable for CLU";
CM_ BO_ 2015 "[TP] TP Message";
CM_ SG_ 2015 Byte0_TCP_7DF "TP";
CM_ SG_ 2015 Byte1_Data_7DF "TP";
CM_ SG_ 2015 Byte2_Data_7DF "TP";
CM_ SG_ 2015 Byte3_Data_7DF "TP";
CM_ SG_ 2015 Byte4_Data_7DF "TP";
CM_ SG_ 2015 Byte5_Data_7DF "TP";
CM_ SG_ 2015 Byte6_Data_7DF "TP";
CM_ SG_ 2015 Byte7_Data_7DF "TP";
CM_ BO_ 479 "[PE] Periodic and On Event";
CM_ SG_ 479 Clu_OutTempC "Outside temperature from Cluster unit (Celsius)";
CM_ SG_ 479 Clu_OutTempF "Outside temperature from Cluster unit (Fahrenheit)";
CM_ SG_ 479 C_InhibitNMT "Shift lever N Position information for Manual Transmission vehicles from CLU";
CM_ SG_ 479 Clu_RheostatLvl "For LCD brightness Only
Keyboard brightness is using Hard Wire
Step 21 is Detent

This signal is valid at 'Tail On' condition";
CM_ BO_ 1269 "[TP] TP Message";
CM_ BO_ 1261 "[TP] TP Message";
CM_ SG_ 1261 Byte0_TCP_4ED "Contents releted with Baidu Music";
CM_ SG_ 1261 Byte1_Data_4ED "Contents releted with Baidu Music";
CM_ SG_ 1261 Byte2_Data_4ED "Contents releted with Baidu Music";
CM_ SG_ 1261 Byte3_Data_4ED "Contents releted with Baidu Music";
CM_ SG_ 1261 Byte4_Data_4ED "Contents releted with Baidu Music";
CM_ SG_ 1261 Byte5_Data_4ED "Contents releted with Baidu Music";
CM_ SG_ 1261 Byte6_Data_4ED "Contents releted with Baidu Music";
CM_ SG_ 1261 Byte7_Data_4ED "Contents releted with Baidu Music";
CM_ BO_ 1271 "[TP] TP Message";
CM_ BO_ 1265 "[TP] TP Message";
CM_ BO_ 1267 "[TP] TP Message";
CM_ BO_ 1257 "[TP] TP Message";
CM_ SG_ 1257 Byte0_TCP_4E9 "TP from CLU to HU (FM Station Name)";
CM_ SG_ 1257 Byte1_Data_4E9 "TP from CLU to HU (FM Station Name)";
CM_ SG_ 1257 Byte2_Data_4E9 "TP from CLU to HU (FM Station Name)";
CM_ SG_ 1257 Byte3_Data_4E9 "TP from CLU to HU (FM Station Name)";
CM_ SG_ 1257 Byte4_Data_4E9 "TP from CLU to HU (FM Station Name)";
CM_ SG_ 1257 Byte5_Data_4E9 "TP from CLU to HU (FM Station Name)";
CM_ SG_ 1257 Byte6_Data_4E9 "TP from CLU to HU (FM Station Name)";
CM_ SG_ 1257 Byte7_Data_4E9 "TP from CLU to HU (FM Station Name)";
CM_ BO_ 1273 "[TP] TP Message";
CM_ BO_ 1263 "[TP] TP Message";
CM_ SG_ 1263 Byte0_TCP_4EF "Flow Control message for TP_HU_IBOX_CLU";
CM_ SG_ 1263 Byte1_Data_4EF "Flow Control message for TP_HU_IBOX_CLU";
CM_ SG_ 1263 Byte2_Data_4EF "Flow Control message for TP_HU_IBOX_CLU";
CM_ SG_ 1263 Byte3_Data_4EF "Flow Control message for TP_HU_IBOX_CLU";
CM_ SG_ 1263 Byte4_Data_4EF "Flow Control message for TP_HU_IBOX_CLU";
CM_ SG_ 1263 Byte5_Data_4EF "Flow Control message for TP_HU_IBOX_CLU";
CM_ SG_ 1263 Byte6_Data_4EF "Flow Control message for TP_HU_IBOX_CLU";
CM_ SG_ 1263 Byte7_Data_4EF "Flow Control message for TP_HU_IBOX_CLU";
CM_ BO_ 1277 "[TP] TP Message";
CM_ SG_ 1277 Byte0_TCP_4FD "Contents releted with ISDB-T";
CM_ SG_ 1277 Byte1_Data_4FD "Contents releted with ISDB-T";
CM_ SG_ 1277 Byte2_Data_4FD "Contents releted with ISDB-T";
CM_ SG_ 1277 Byte3_Data_4FD "Contents releted with ISDB-T";
CM_ SG_ 1277 Byte4_Data_4FD "Contents releted with ISDB-T";
CM_ SG_ 1277 Byte5_Data_4FD "Contents releted with ISDB-T";
CM_ SG_ 1277 Byte6_Data_4FD "Contents releted with ISDB-T";
CM_ SG_ 1277 Byte7_Data_4FD "Contents releted with ISDB-T";
CM_ BO_ 1251 "[TP] TP Message";
CM_ SG_ 1251 Byte0_TCP_4E3 "TP from CLU to HU (Juke box)";
CM_ SG_ 1251 Byte1_Data_4E3 "TP from CLU to HU (Juke box)";
CM_ SG_ 1251 Byte2_Data_4E3 "TP from CLU to HU (Juke box)";
CM_ SG_ 1251 Byte3_Data_4E3 "TP from CLU to HU (Juke box)";
CM_ SG_ 1251 Byte4_Data_4E3 "TP from CLU to HU (Juke box)";
CM_ SG_ 1251 Byte5_Data_4E3 "TP from CLU to HU (Juke box)";
CM_ SG_ 1251 Byte6_Data_4E3 "TP from CLU to HU (Juke box)";
CM_ SG_ 1251 Byte7_Data_4E3 "TP from CLU to HU (Juke box)";
CM_ BO_ 1275 "[TP] TP Message";
CM_ BO_ 1259 "[TP] TP Message";
CM_ BO_ 277 "[PE] Periodic and On Event";
CM_ SG_ 277 TBT_Display_Type "Information for NAVI TBT Display type";
CM_ SG_ 277 TBT_Side_Street "Information for whole directions of street
(Using according to display type definition)
15 directions (except backward) are assigned to each 15 bits";
CM_ SG_ 277 TBT_Direction "Information for direction defined at TBT_Display_Type
- 48 directions (7.5 deg. Interval)
- Vehicles following HUD/Cluster Interface Spec (ES-96560-22) use only 16 directions (22.5 deg. Interval)";
CM_ SG_ 277 TBT_Distance_Turn_Point "Remaining distance to turn point (over Decimal Point)";
CM_ SG_ 277 TBT_Combined_Side_Street "Information for direction of combined side street (in front of turn point)
(Using according to display type definition)";
CM_ SG_ 277 TBT_Scale "Information for Scale unit (m, km, mile, feet)";
CM_ SG_ 277 TBT_DistancetoTurnPoint "Information for remaining distance from turn point (under Decimal Point)";
CM_ BO_ 406 "[PE] Periodic and On Event";
CM_ SG_ 406 HD_SPS_ChannelNo "Information for SPS(Supplementary Program Service) Channel Number of HD Radio";
CM_ SG_ 406 SXM_ChannelNo "Information for SXM Channel Number

Range : 0~999";
CM_ BO_ 407 "[PE] Periodic and On Event";
CM_ SG_ 407 HU_LanguageInfo "Information for System Language (for Display Font)";
CM_ SG_ 407 HU_MuteStatus "Information for System Mute Display";
CM_ SG_ 407 HU_VolumeStatus "Information for AVN Volume";
CM_ SG_ 407 HU_NaviDisp "Information for Navi Display status on Front Monitor";
CM_ SG_ 407 HU_NaviStatus "Information for Navigation Status (Booting, Normal Operation, No SD card)
-AVN NAVI Transmission Signal";
CM_ SG_ 407 HU_UsmSupport "Information whether HU can support USM or not";
CM_ SG_ 407 HU_NaviCamSettingStatus "Information for Navi Camera alert setting status

+ Bit-coded field (On 1, Off 0)
   - bit 0 : Fixed Camera
   - bit 1 : Signal/Speed Violation Camera
   - bit 2 : Movable Camera
   - bit 3 : User Registration Fixed Camera
   - bit 4 : User Registration Signal/Speed Violation Camera
   - bit 5~6 : Reserved
-AVN NAVI Transmission Signal";
CM_ BO_ 290 "[PE] Periodic and On Event";
CM_ SG_ 290 HU_OpState_New "Information for AV Operation mode";
CM_ SG_ 290 HU_Frequency_Unit "Information for Frequency unit display";
CM_ SG_ 290 HU_User_Input "User Input (Seek Up/Dn, Mode Change)
# Singnal Trigger Condition
1. DiscCD/MP3CD/VCD
 - Track Up/Dn (by SoftKey)
 - Track Up/Dn (by HardKey)
 - Song Change (by List)
 - Song Cjamge (by Tune Enter)
2. DVD (No TP)
 - Track Up/Dn (by SoftKey)
 - Track Up/Dn (by HardKey)
 - Song Change (by List)
 - Song Cjamge (by Tune Enter)
3. DMB/DAB
 - Track Up/Dn (by HardKey)
 - Song Change (by List)
 - Song Cjamge (by Tune Enter)
4. FM/AM/SXM
 - Track Up/Dn (by HardKey)
 - Song Change (by List)
5. ITM(FM/DAB)
 - Track Up/Dn (by HardKey)
 - Song Change (by List)
 - Song Cjamge (by Tune Enter)
6. USB Music/Video/My Music/JukeBox/iPod/Pandora
 - Track Up/Dn (by SoftKey)
 - Track Up/Dn (by HardKey)
 - Song Change (by List)
 - Song Cjamge (by Tune Enter)
7. Bluetooth Audio
 - Track Up/Dn (by SoftKey)
 - Track Up/Dn (by HardKey)
8. CarPlay/Android Auto
 - Track Up/Dn (by HardKey)";
CM_ SG_ 290 HU_FMFrequency_Offset_Type "Information for FM frequency offset type";
CM_ SG_ 290 FM_Decimal_Point "Information for Frequency decimal point";
CM_ SG_ 290 HU_Track_Number_New "Information for Number of Track / Chapter / Playlist";
CM_ SG_ 290 HU_Play_time_Sec_New "Information for Play time in Second unit";
CM_ SG_ 290 HU_Play_time_Min_New "Information for Play time in Minute unit";
CM_ SG_ 290 HU_Play_time_Hour_New "Information for Play time in Hour unit";
CM_ SG_ 290 HU_Frequency_New "Information for Radio Frequency";
CM_ BO_ 291 "[PE] Periodic and On Event";
CM_ SG_ 291 NV_Display_TG "Information for Toll Gate Display";
CM_ SG_ 291 TBT_BarGraph100Level "Information for Bar Graph Level (0 ~ 100%, 10% interval), 

if your system develop after 2012-09-10, you must not use TBT_Bar_Level(@0x115)";
CM_ BO_ 286 "[PE] Periodic and On Event";
CM_ SG_ 286 Navi_WarnDist_OverDec "Remaining distance to warning information (over decimal point)";
CM_ SG_ 286 Navi_WarnDist_UnderDec "Remaining distance to warning information (under decimal point)";
CM_ SG_ 286 Navi_WarnDist_Scale "Scale unit of warning distance";
CM_ BO_ 56 "[EC] On Event and On Change";
CM_ SG_ 56 C_DrvWindowOpenCmd "This signal indicates DRV Window Open/Close Command";
CM_ SG_ 56 C_AstWindowCmdAVN "This signal indicates AST Window Open/Close Command";
CM_ SG_ 56 C_RLWindowCmdAVN "This signal indicates RL Window Open/Close Command";
CM_ SG_ 56 C_RRWindowCmdAVN "This signal indicates RR Window Open/Close Command";
CM_ SG_ 56 C_RrDefoggerCmdAVN "This signal indicates Rear Defogger Button Command";
CM_ SG_ 56 C_StrgWhlHeatedCmdAVN "This signal indicates Steering Wheel Heated Button Command";
CM_ SG_ 56 C_TrunkTlgtCmdAVN "This signal indicates Trunk Open Button Command";
CM_ SG_ 56 C_PTGCNTLCmdAVN "This signal indicates PowerTailgate Open/Close  Command";
CM_ SG_ 56 C_AVNIMSButtonCmd "This signal indicates IMS button Command";
CM_ BO_ 52 "[EC] On Event and On Change";
CM_ SG_ 52 HU_DATC_DrTempUpDn "Temperature control of Driver side";
CM_ SG_ 52 HU_DATC_MainBlower "Main Blower control";
CM_ SG_ 52 HU_DATC_FrontModeSet "DATC Mode control";
CM_ SG_ 52 HU_DATC_AutoSet "DATC Auto control";
CM_ SG_ 52 HU_DATC_IntakeSet "DATC Intake control";
CM_ SG_ 52 HU_DATC_AcSet "DATC A/C control";
CM_ SG_ 52 HU_DATC_FrontDefog "Front window Defog";
CM_ SG_ 52 DATC_ADSOnOffSet "ADS(Auto Defog System) On/Off Set Command";
CM_ SG_ 52 HU_DATC_MainBlowerUpDn "Main Blower Up/Down control";
CM_ SG_ 52 HU_DATC_AirCleaningSet "Air Cleaning System set";
CM_ BO_ 54 "[EC] On Event and On Change";
CM_ SG_ 54 HU_DATC_DrTempSetC "In single type DATC, set temperature of front side directly(Centigrade).
In dual type DATC, set temperature of front left side directly(Centigrade).";
CM_ SG_ 54 HU_DATC_DrTempSetF "In single type DATC, set temperature of front side directly (Fahrenheit).
In dual type DATC, set temperature of front left side directly (Fahrenheit).";
CM_ BO_ 256 "[PE] Periodic and On Event";
CM_ SG_ 256 HU_Type "Information for H/U Platform type
- Integrated AVN 1.0 use different value depends on development company (Mobis:0x68/LG:0x70)
- Integrated AVN 1.0 Mobis is developed based on Display Audio
- Integrated AVN 1.0 LG is developed based on Compact AVN

Information for China OPIO Platform
- 0xFC: China OPIO w/o CLU interface (most of phase1)
- 0xFD: China OPIO w/CLU interface (parts of phase1, phase2)

Information for Audio Platform Type
- 0x43 : Audio 4.0 Value";
CM_ SG_ 256 HU_DistributeInfo "Region :Europe/North America/
Vehicle Type : RHD/LHD
Positionning information";
CM_ SG_ 256 HU_OptionInfo "Information of H/U functions";
CM_ SG_ 256 HU_AdasSupport "Information about ADAS support
-Classify between General Map and Precise Map Transmission Function
-AVN System Transmission Signal";
CM_ BO_ 206 "[EC] On Event and On Change";
CM_ SG_ 206 META_MapProvider "Information for Map Provider of current area";
CM_ SG_ 206 META_MessageType "Information for Meta Data Message Type";
CM_ SG_ 206 META_CountryCode "Information for Countrol Code : ISO 3166-1 numeric values";
CM_ SG_ 206 META_MinorProtocolSubVer "Information for Minor protocol sub-version";
CM_ SG_ 206 META_MajorProtocolVersion "Information for Major protocol version";
CM_ SG_ 206 META_CyclicCounter "Information for Cyclic counter of this message type: Reconstructor can use this value to detect missing messages.";
CM_ SG_ 206 META_HardwareVersion "Information for Hardware version";
CM_ SG_ 206 META_DrivingSide "Information for Driving Side Type";
CM_ SG_ 206 META_RegionCode "Information for Region Code: ISO 3166-2 values";
CM_ SG_ 206 META_MapVersionYear "Information for Year of release of map; Year-2000, mode 63
Content of this field is Year of release of map of current area. For 2007, this field will contain value 7.";
CM_ SG_ 206 META_MapVersionQuarter "Information for Quarter of release of map: Quarter-1
For example, Q4/2007 map will be described as MAP VERSION (Y) = 7, MAP VERSION (Q) = 3";
CM_ SG_ 206 META_MinorProtocolVersion "Information for Minor protocol version";
CM_ SG_ 206 META_SpeedUnit "Information for Speed Unit Type: km/h, mph";
CM_ BO_ 205 "[EC] On Event and On Change";
CM_ SG_ 205 PROLONG_Value "Information for Profile Long value at Offset";
CM_ SG_ 205 PROLONG_MessageType "Information for Profile Long Message Type";
CM_ SG_ 205 PROLONG_Offset "Information for Offset of position of the first profile spot from currnet position";
CM_ SG_ 205 PROLONG_PathIndex "Information for Index of the path where this profile is located";
CM_ SG_ 205 PROLONG_CyclicCounter "Information for Cyclic counter of this message type and profile type: Reconstructor can use this value to detect missing messages
-Applying particularly according to PROLONG_ProfileType
 Ex) ProfileType(CyclicCounter): 0x1(0)  0x1(1)  0x10(0)  0x1(2)  0x10(1) ¡¦";
CM_ SG_ 205 PROLONG_Update "Updated information of already transmitted Profile Long
-If Overspeed Check Camera Information is updated by Wireless Network of TPEG, set 'True' about Updated Field of Profile Long Message and transmitt it. Refer to '5.7.8' in specification for detail";
CM_ SG_ 205 PROLONG_Retransmission "Information for Profile Long Retransmission Flag: If true, this message was sent already at least once before";
CM_ SG_ 205 PROLONG_CountrolPoint "Information for Interpolation Flag: If true, values in this message specifies additional control points required for the interpolation of this profile; 
If false, actual profile values are specified";
CM_ SG_ 205 PROLONG_ProfileType "Information for Profile Long Type(0~31)
-Refer to 'Table 19' in specification for detail";
CM_ BO_ 204 "[EC] On Event and On Change";
CM_ SG_ 204 PROSHORT_MessageType "Information for Profile Short Message Type";
CM_ SG_ 204 PROSHORT_Offset "Information for Offset of position of the first profile spot from currnet position
-This Offset should be calculated using below Factors(according to Profile Type)
-Profile Type 1(Curvature): 1m
-Profile Type 4(Slope): 1m(PROSHORT_Accuracy=0x0), 3m(PROSHORT_Accuracy=0x2)
-Profile Type 16(Safety Driving Section): 1m(Section0,1,2,3,5)
-Refer to Specification(ES96523-31) for details";
CM_ SG_ 204 PROSHORT_PathIndex "Information for Index of the path where this profile is located";
CM_ SG_ 204 PROSHORT_CyclicCounter "Information for Cyclic counter of this message type and profile type: Reconstructor can use this value to detect missing messages.
-According to Profile Type, transmitt different Cyclic Counter Values
-In case of Slope, transmitt Cyclic Counter Values according to the Slope Transmitting Specification
 (Refer to 5.4 Slope Information Transmitting Scenario in Specification: It is about Information for Average Slope(Maximum 3) Transmitting by Event in forward unit distance(2km/20km) containing Current Location)
-In case of 'PROSHORT_CyclicCounter', transmitt particularly according to the 'PROSHORT_ProfileType'
 Ex) ProfileType(CyclicCounter): 0x1(0)  0x1(1)  0x10(0)  0x1(2)  0x10(1) ...";
CM_ SG_ 204 PROSHORT_Accuracy "Information for Accuracy of profile value is implementation specific.";
CM_ SG_ 204 PROSHORT_Distance "Information for Distance from first profile spot to the second one
-This distance should be calculated using below Factors(according to Profile Type)
-Profile Type 1(Curvature): 2
-Profile Type 4(Slope): 2(PROSHORT_Accuracy=0x0), 20(PROSHORT_Accuracy=0x2)
-Profile Type 16(Safety Driving Section): 20(Section0,1), 2(Section2,3), 5(Section5)";
CM_ SG_ 204 PROSHORT_Value0 "Information for Profile Short value at Offset";
CM_ SG_ 204 PROSHORT_Value1 "Information for Profile Short value at Offset+Distance1";
CM_ SG_ 204 PROSHORT_Update "Updated information of already transmitted Profile Short";
CM_ SG_ 204 PROSHORT_Retransmission "Information for Retransmission Flag: If true, this message was sent already at least once before";
CM_ SG_ 204 PROSHORT_ControlPoint "Information for Profile Short Interpolation Flag: If true, values in this message specifies additional control points required for the interpolation of this profile; 
If false, actual profile values are specified";
CM_ SG_ 204 PROSHORT_ProfileType "Information for Profile Short Type: Slope(Linear) is used for Slope
-In case of Section Speed, transmitt Average Value of Speed Limit of Links in Section.
-Link without Speed Limit is excluded for Average Speed Calculation
-Unlimited Lane in Europe reflects 140kph for Average Speed Calculation";
CM_ BO_ 207 "[EC] On Event and On Change";
CM_ SG_ 207 PROSHORT_MessageType_01 "Information for Profile Short Message Type";
CM_ SG_ 207 PROSHORT_Offset_01 "Information for Offset of position of the first profile spot from currnet position
-This Offset should be calculated using below Factors(according to Profile Type)
-Profile Type 4(Slope): 1m(PROSHORT_Accuracy=0x0), 3m(PROSHORT_Accuracy=0x2)
-Refer to Specification(ES96523-31) for details";
CM_ SG_ 207 PROSHORT_PathIndex_01 "Information for Index of the path where this profile is located";
CM_ SG_ 207 PROSHORT_CyclicCounter_01 "Information for Cyclic counter of this message type and profile type: Reconstructor can use this value to detect missing messages.
-According to Profile Type, transmitt different Cyclic Counter Values
-In case of Slope, transmitt Cyclic Counter Values according to the Slope Transmitting Specification
 (Refer to 5.4 Slope Information Transmitting Scenario in Specification: It is about Information for Average Slope(Maximum 3) Transmitting by Event in forward unit distance(2km/20km) containing Current Location)
-In case of 'PROSHORT_CyclicCounter', transmitt particularly according to the 'PROSHORT_ProfileType'
 Ex) ProfileType(CyclicCounter): 0x1(0)  0x1(1)  0x10(0)  0x1(2)  0x10(1) ...";
CM_ SG_ 207 PROSHORT_Accuracy_01 "Information for Accuracy of profile value is implementation specific.";
CM_ SG_ 207 PROSHORT_Distance_01 "Information for Distance from first profile spot to the second one
-This distance should be calculated using below Factors(according to Profile Type)
-Profile Type 4(Slope): 2(PROSHORT_Accuracy=0x0), 20(PROSHORT_Accuracy=0x2)";
CM_ SG_ 207 PROSHORT_Value0_01 "Information for Profile Short value at Offset";
CM_ SG_ 207 PROSHORT_Value1_01 "Information for Profile Short value at Offset+Distance1";
CM_ SG_ 207 PROSHORT_Update_01 "Updated information of already transmitted Profile Short";
CM_ SG_ 207 PROSHORT_Retransmission_01 "Information for Retransmission Flag: If true, this message was sent already at least once before";
CM_ SG_ 207 PROSHORT_ControlPoint_01 "Information for Profile Short Interpolation Flag: If true, values in this message specifies additional control points required for the interpolation of this profile; 
If false, actual profile values are specified";
CM_ SG_ 207 PROSHORT_ProfileType_01 "Information for Profile Short Type: Slope(Linear) is used for Slope";
CM_ BO_ 1268 "[TP] TP Message";
CM_ BO_ 1260 "[TP] TP Message";
CM_ SG_ 1260 Byte0_TCP_4EC "Contents releted with Baidu Music";
CM_ SG_ 1260 Byte1_Data_4EC "Contents releted with Baidu Music";
CM_ SG_ 1260 Byte2_Data_4EC "Contents releted with Baidu Music";
CM_ SG_ 1260 Byte3_Data_4EC "Contents releted with Baidu Music";
CM_ SG_ 1260 Byte4_Data_4EC "Contents releted with Baidu Music";
CM_ SG_ 1260 Byte5_Data_4EC "Contents releted with Baidu Music";
CM_ SG_ 1260 Byte6_Data_4EC "Contents releted with Baidu Music";
CM_ SG_ 1260 Byte7_Data_4EC "Contents releted with Baidu Music";
CM_ BO_ 1270 "[TP] TP Message";
CM_ BO_ 1264 "[TP] TP Message";
CM_ BO_ 1266 "[TP] TP Message";
CM_ BO_ 1256 "[TP] TP Message";
CM_ SG_ 1256 Byte0_TCP_4E8 "TP from HU to CLU (FM Station Name)";
CM_ SG_ 1256 Byte1_Data_4E8 "TP from HU to CLU (FM Station Name)";
CM_ SG_ 1256 Byte2_Data_4E8 "TP from HU to CLU (FM Station Name)";
CM_ SG_ 1256 Byte3_Data_4E8 "TP from HU to CLU (FM Station Name)";
CM_ SG_ 1256 Byte4_Data_4E8 "TP from HU to CLU (FM Station Name)";
CM_ SG_ 1256 Byte5_Data_4E8 "TP from HU to CLU (FM Station Name)";
CM_ SG_ 1256 Byte6_Data_4E8 "TP from HU to CLU (FM Station Name)";
CM_ SG_ 1256 Byte7_Data_4E8 "TP from HU to CLU (FM Station Name)";
CM_ BO_ 1272 "[TP] TP Message";
CM_ BO_ 1262 "[TP] TP Message";
CM_ SG_ 1262 Byte0_TCP_4EE "Song Name, Artist, File Name, Play Time of iBox player";
CM_ SG_ 1262 Byte1_Data_4EE "Song Name, Artist, File Name, Play Time of iBox player";
CM_ SG_ 1262 Byte2_Data_4EE "Song Name, Artist, File Name, Play Time of iBox player";
CM_ SG_ 1262 Byte3_Data_4EE "Song Name, Artist, File Name, Play Time of iBox player";
CM_ SG_ 1262 Byte4_Data_4EE "Song Name, Artist, File Name, Play Time of iBox player";
CM_ SG_ 1262 Byte5_Data_4EE "Song Name, Artist, File Name, Play Time of iBox player";
CM_ SG_ 1262 Byte6_Data_4EE "Song Name, Artist, File Name, Play Time of iBox player";
CM_ SG_ 1262 Byte7_Data_4EE "Song Name, Artist, File Name, Play Time of iBox player";
CM_ BO_ 1276 "[TP] TP Message";
CM_ SG_ 1276 Byte0_TCP_4FC "Contents releted with ISDB-T";
CM_ SG_ 1276 Byte1_Data_4FC "Contents releted with ISDB-T";
CM_ SG_ 1276 Byte2_Data_4FC "Contents releted with ISDB-T";
CM_ SG_ 1276 Byte3_Data_4FC "Contents releted with ISDB-T";
CM_ SG_ 1276 Byte4_Data_4FC "Contents releted with ISDB-T";
CM_ SG_ 1276 Byte5_Data_4FC "Contents releted with ISDB-T";
CM_ SG_ 1276 Byte6_Data_4FC "Contents releted with ISDB-T";
CM_ SG_ 1276 Byte7_Data_4FC "Contents releted with ISDB-T";
CM_ BO_ 1250 "[TP] TP Message";
CM_ SG_ 1250 Byte0_TCP_4E2 "TP from HU to CLU (Juke box)";
CM_ SG_ 1250 Byte1_Data_4E2 "TP from HU to CLU (Juke box)";
CM_ SG_ 1250 Byte2_Data_4E2 "TP from HU to CLU (Juke box)";
CM_ SG_ 1250 Byte3_Data_4E2 "TP from HU to CLU (Juke box)";
CM_ SG_ 1250 Byte4_Data_4E2 "TP from HU to CLU (Juke box)";
CM_ SG_ 1250 Byte5_Data_4E2 "TP from HU to CLU (Juke box)";
CM_ SG_ 1250 Byte6_Data_4E2 "TP from HU to CLU (Juke box)";
CM_ SG_ 1250 Byte7_Data_4E2 "TP from HU to CLU (Juke box)";
CM_ BO_ 1274 "[TP] TP Message";
CM_ BO_ 1258 "[TP] TP Message";
BA_DEF_ SG_ "Gatewaysignal" ENUM "No","M-B","B-M","M-C","C-M","M-C-B" ;
BA_DEF_ SG_ "GenSigEnvVarType" ENUM "Int","Float","undef" ;
BA_DEF_ SG_ "GenSigSendType" ENUM "Cyclic","OnWrite","OnWriteWithRepetition","OnChange","OnChangeWithRepetition","IfActive","IfActiveWithRepetition","NoSigSendType" ;
BA_DEF_ SG_ "GenSigStartValue" INT 0 0 ;
BA_DEF_ SG_ "GwSigLatencyTime" INT 0 65535 ;
BA_DEF_ SG_ "GwSigMissingSourceType" ENUM "Undef","OldValue","DefaultValue","InitialValue" ;
BA_DEF_ SG_ "NmNetworkRequest" ENUM "No","Yes" ;
BA_DEF_ SG_ "NmNetworkRequestHoldingTime" INT 0 65535 ;
BA_DEF_ SG_ "Purpose" ENUM "<t.b.d.>","Function","Diagnostic","Development","NM" ;
BA_DEF_ SG_ "SignalCategory" HEX 10 15 ;
BA_DEF_ SG_ "TimeoutValue" STRING ;
BA_DEF_ SG_ "UpdateRateMax" INT 0 0 ;
BA_DEF_ SG_ "UpdateRateMin" INT 0 0 ;
BA_DEF_ SG_ "Validity" ENUM "B+","ACC","IGN1","IGN2" ;
BA_DEF_ BO_ "DiagState" ENUM "No","Yes" ;
BA_DEF_ BO_ "GenMsgCycleTime" INT 0 100000 ;
BA_DEF_ BO_ "GenMsgCycleTimeFast" INT 0 500 ;
BA_DEF_ BO_ "GenMsgDelayTime" INT 0 20 ;
BA_DEF_ BO_ "GenMsgEVName" STRING ;
BA_DEF_ BO_ "GenMsgILSupport" ENUM "No","Yes" ;
BA_DEF_ BO_ "GenMsgNrOfRepetition" INT 0 3 ;
BA_DEF_ BO_ "GenMsgSendType" ENUM "Cyclic","not_used","not_used","not_used","not_used","not_used","not_used","not_used","NoMsgSendType" ;
BA_DEF_ BO_ "GenMsgStartDelayTime" INT 0 2000 ;
BA_DEF_ BO_ "NmMessage" ENUM "No","Yes" ;
BA_DEF_ BO_ "RoutingType" ENUM "<n.a.>","Direct","Indirect" ;
BA_DEF_ BO_ "TpMessage" ENUM "No","Yes" ;
BA_DEF_ BO_ "TpTxIndex" INT 0 255 ;
BA_DEF_ BU_ "GenNodSleepTime" INT 1375 1650 ;
BA_DEF_ BU_ "ILUsed" ENUM "No","Yes" ;
BA_DEF_ BU_ "NmCAN" INT 1 2 ;
BA_DEF_ BU_ "NmNode" ENUM "No","Yes" ;
BA_DEF_ BU_ "NmStationAddress" HEX 0 255 ;
BA_DEF_ BU_ "NodeLayerModules" STRING ;
BA_DEF_ "Baudrate" INT 50000 500000 ;
BA_DEF_ "BusType" STRING ;
BA_DEF_ "GenEnvVarEndingDsp" STRING ;
BA_DEF_ "GenEnvVarEndingSnd" STRING ;
BA_DEF_ "GenEnvVarPrefix" STRING ;
BA_DEF_ "GenNWMApBusSleep" STRING ;
BA_DEF_ "GenNWMApCanNormal" STRING ;
BA_DEF_ "GenNWMApCanOff" STRING ;
BA_DEF_ "GenNWMApCanOn" STRING ;
BA_DEF_ "GenNWMApCanSleep" STRING ;
BA_DEF_ "GenNWMApCanWakeUp" STRING ;
BA_DEF_ "GenNWMGotoMode_Awake" STRING ;
BA_DEF_ "GenNWMGotoMode_BusSleep" STRING ;
BA_DEF_ "GenNWMSleepTime" INT 1375 1650 ;
BA_DEF_ "GenNWMTalkNM" STRING ;
BA_DEF_ "Manufacturer" STRING ;
BA_DEF_ "NmBaseAddress" HEX 0 2047 ;
BA_DEF_ "NmMessageCount" INT 0 128 ;
BA_DEF_ "NmType" STRING ;
BA_DEF_ "SamplePointMax" INT 50 85 ;
BA_DEF_ "SamplePointMin" INT 55 85 ;
BA_DEF_ "SyncJumpWidthMax" INT 1 8 ;
BA_DEF_ "SyncJumpWidthMin" INT 1 4 ;
BA_DEF_ "VersionDay" INT 1 31 ;
BA_DEF_ "VersionMonth" INT 1 12 ;
BA_DEF_ "VersionNumber" INT 0 999999 ;
BA_DEF_ "VersionWeek" INT 1 53 ;
BA_DEF_ "VersionYear" INT 0 9999 ;
BA_DEF_ SG_ "SigDescription" STRING ;
BA_DEF_ SG_ "Platform" STRING ;
BA_DEF_ SG_ "SigOldType" ENUM "No","Yes" ;
BA_DEF_REL_ BU_SG_REL_ "GenSigTimeoutTime" INT 0 7000 ;
BA_DEF_DEF_ "Gatewaysignal" "No" ;
BA_DEF_DEF_ "GenSigEnvVarType" "undef" ;
BA_DEF_DEF_ "GenSigSendType" "NoSigSendType" ;
BA_DEF_DEF_ "GenSigStartValue" 0 ;
BA_DEF_DEF_ "GwSigLatencyTime" 40 ;
BA_DEF_DEF_ "GwSigMissingSourceType" "Undef" ;
BA_DEF_DEF_ "NmNetworkRequest" "No" ;
BA_DEF_DEF_ "NmNetworkRequestHoldingTime" 0 ;
BA_DEF_DEF_ "Purpose" "<t.b.d.>" ;
BA_DEF_DEF_ "SignalCategory" 12 ;
BA_DEF_DEF_ "TimeoutValue" "" ;
BA_DEF_DEF_ "UpdateRateMax" 0 ;
BA_DEF_DEF_ "UpdateRateMin" 0 ;
BA_DEF_DEF_ "Validity" "ACC" ;
BA_DEF_DEF_ "DiagState" "No" ;
BA_DEF_DEF_ "GenMsgCycleTime" 0 ;
BA_DEF_DEF_ "GenMsgCycleTimeFast" 0 ;
BA_DEF_DEF_ "GenMsgDelayTime" 20 ;
BA_DEF_DEF_ "GenMsgEVName" "@Signame" ;
BA_DEF_DEF_ "GenMsgILSupport" "Yes" ;
BA_DEF_DEF_ "GenMsgNrOfRepetition" 0 ;
BA_DEF_DEF_ "GenMsgSendType" "NoMsgSendType" ;
BA_DEF_DEF_ "GenMsgStartDelayTime" 0 ;
BA_DEF_DEF_ "NmMessage" "No" ;
BA_DEF_DEF_ "RoutingType" "<n.a.>" ;
BA_DEF_DEF_ "TpMessage" "No" ;
BA_DEF_DEF_ "TpTxIndex" 0 ;
BA_DEF_DEF_ "GenNodSleepTime" 1500 ;
BA_DEF_DEF_ "ILUsed" "Yes" ;
BA_DEF_DEF_ "NmCAN" 1 ;
BA_DEF_DEF_ "NmNode" "Yes" ;
BA_DEF_DEF_ "NmStationAddress" 0 ;
BA_DEF_DEF_ "NodeLayerModules" "oseknm01.dll" ;
BA_DEF_DEF_ "Baudrate" 100000 ;
BA_DEF_DEF_ "BusType" "CAN" ;
BA_DEF_DEF_ "GenEnvVarEndingDsp" "Dsp_" ;
BA_DEF_DEF_ "GenEnvVarEndingSnd" "_" ;
BA_DEF_DEF_ "GenEnvVarPrefix" "Env" ;
BA_DEF_DEF_ "GenNWMApBusSleep" "ApplNmCanBusSleep()" ;
BA_DEF_DEF_ "GenNWMApCanNormal" "ApplNmCanNormal()" ;
BA_DEF_DEF_ "GenNWMApCanOff" "ApplCanOffline()" ;
BA_DEF_DEF_ "GenNWMApCanOn" "ApplCanOnline()" ;
BA_DEF_DEF_ "GenNWMApCanSleep" "ApplNmCanSleep()" ;
BA_DEF_DEF_ "GenNWMApCanWakeUp" "ApplCanWakeUp()" ;
BA_DEF_DEF_ "GenNWMGotoMode_Awake" "GotoMode_Awake()" ;
BA_DEF_DEF_ "GenNWMGotoMode_BusSleep" "GotoMode_BusSleep()" ;
BA_DEF_DEF_ "GenNWMSleepTime" 1500 ;
BA_DEF_DEF_ "GenNWMTalkNM" "TalkNM()" ;
BA_DEF_DEF_ "Manufacturer" "HMC" ;
BA_DEF_DEF_ "NmBaseAddress" 1024 ;
BA_DEF_DEF_ "NmMessageCount" 128 ;
BA_DEF_DEF_ "NmType" "Vector" ;
BA_DEF_DEF_ "SamplePointMax" 82 ;
BA_DEF_DEF_ "SamplePointMin" 75 ;
BA_DEF_DEF_ "SyncJumpWidthMax" 3 ;
BA_DEF_DEF_ "SyncJumpWidthMin" 2 ;
BA_DEF_DEF_ "VersionDay" 1 ;
BA_DEF_DEF_ "VersionMonth" 1 ;
BA_DEF_DEF_ "VersionNumber" 0 ;
BA_DEF_DEF_ "VersionWeek" 1 ;
BA_DEF_DEF_ "VersionYear" 2010 ;
BA_DEF_DEF_ "SigDescription" "" ;
BA_DEF_DEF_ "Platform" "Standard AVN 4.0,Standard Audio 3.0,Premium AVN 3.0" ;
BA_DEF_DEF_ "SigOldType" "No" ;
BA_DEF_DEF_REL_ "GenSigTimeoutTime" 700 ;
BA_ "VersionNumber" 180601;
BA_ "NmStationAddress" BU_ AMP 72;
BA_ "GenMsgSendType" BO_ 384 0;
BA_ "GenMsgCycleTime" BO_ 384 1000;
BA_ "GenMsgStartDelayTime" BO_ 384 10;
BA_ "NmStationAddress" BU_ CLU 77;
BA_ "NmStationAddress" BU_ H_U 64;
BA_REL_ "GenSigTimeoutTime" BU_SG_REL_ CLU SG_ 384 HU_InitInfo 3500;
BA_REL_ "GenSigTimeoutTime" BU_SG_REL_ H_U SG_ 384 HU_InitInfo 3500;
BA_ "Platform" SG_ 384 HU_InitInfo "";
BA_ "GenSigSendType" SG_ 384 HU_InitInfo 3;
BA_ "GenSigStartValue" SG_ 384 HU_InitInfo 3;
BA_ "GenMsgNrOfRepetition" BO_ 384 3;
BA_ "GenMsgCycleTimeFast" BO_ 384 40;
BA_REL_ "GenSigTimeoutTime" BU_SG_REL_ CLU SG_ 384 AMP_ASDModeState 3500;
BA_REL_ "GenSigTimeoutTime" BU_SG_REL_ H_U SG_ 384 AMP_ASDModeState 3500;
BA_ "SigDescription" SG_ 384 AMP_ASDModeState "HI : default value 0x1
DH PE : default value 0x3";
BA_ "Platform" SG_ 384 AMP_ASDModeState "";
BA_ "GenSigSendType" SG_ 384 AMP_ASDModeState 4;
BA_ "GenSigStartValue" SG_ 384 AMP_ASDModeState 7;
BA_ "NmNetworkRequest" SG_ 384 AMP_ASDModeState 1;
BA_ "TimeoutValue" SG_ 384 AMP_ASDModeState "0x7";
BA_REL_ "GenSigTimeoutTime" BU_SG_REL_ CLU SG_ 384 AMP_NaviModeState 3500;
BA_REL_ "GenSigTimeoutTime" BU_SG_REL_ H_U SG_ 384 AMP_NaviModeState 3500;
BA_ "Platform" SG_ 384 AMP_NaviModeState "";
BA_ "GenSigSendType" SG_ 384 AMP_NaviModeState 4;
BA_ "GenSigStartValue" SG_ 384 AMP_NaviModeState 3;
BA_ "NmNetworkRequest" SG_ 384 AMP_NaviModeState 1;
BA_ "TimeoutValue" SG_ 384 AMP_NaviModeState "0x3";
BA_REL_ "GenSigTimeoutTime" BU_SG_REL_ CLU SG_ 384 AMP_SPDIFInfo 3500;
BA_REL_ "GenSigTimeoutTime" BU_SG_REL_ H_U SG_ 384 AMP_SPDIFInfo 3500;
BA_ "Platform" SG_ 384 AMP_SPDIFInfo "";
BA_ "GenSigSendType" SG_ 384 AMP_SPDIFInfo 3;
BA_ "GenSigStartValue" SG_ 384 AMP_SPDIFInfo 7;
BA_REL_ "GenSigTimeoutTime" BU_SG_REL_ CLU SG_ 384 AMP_StartUpComplete 3500;
BA_REL_ "GenSigTimeoutTime" BU_SG_REL_ H_U SG_ 384 AMP_StartUpComplete 3500;
BA_ "Platform" SG_ 384 AMP_StartUpComplete "";
BA_ "GenSigSendType" SG_ 384 AMP_StartUpComplete 4;
BA_ "GenSigStartValue" SG_ 384 AMP_StartUpComplete 3;
BA_ "NmNetworkRequest" SG_ 384 AMP_StartUpComplete 1;
BA_REL_ "GenSigTimeoutTime" BU_SG_REL_ CLU SG_ 384 AMP_VSCModeState 3500;
BA_REL_ "GenSigTimeoutTime" BU_SG_REL_ H_U SG_ 384 AMP_VSCModeState 3500;
BA_ "Platform" SG_ 384 AMP_VSCModeState "";
BA_ "GenSigSendType" SG_ 384 AMP_VSCModeState 4;
BA_ "GenSigStartValue" SG_ 384 AMP_VSCModeState 3;
BA_ "NmNetworkRequest" SG_ 384 AMP_VSCModeState 1;
BA_ "TimeoutValue" SG_ 384 AMP_VSCModeState "0x3";
BA_REL_ "GenSigTimeoutTime" BU_SG_REL_ CLU SG_ 384 AMP_SDVCStepState 3500;
BA_REL_ "GenSigTimeoutTime" BU_SG_REL_ H_U SG_ 384 AMP_SDVCStepState 3500;
BA_ "Platform" SG_ 384 AMP_SDVCStepState "";
BA_ "GenSigSendType" SG_ 384 AMP_SDVCStepState 4;
BA_ "GenSigStartValue" SG_ 384 AMP_SDVCStepState 7;
BA_ "NmNetworkRequest" SG_ 384 AMP_SDVCStepState 1;
BA_ "TimeoutValue" SG_ 384 AMP_SDVCStepState "0x7";
BA_REL_ "GenSigTimeoutTime" BU_SG_REL_ CLU SG_ 384 AMP_Beep1ModeState 3500;
BA_REL_ "GenSigTimeoutTime" BU_SG_REL_ H_U SG_ 384 AMP_Beep1ModeState 3500;
BA_ "Platform" SG_ 384 AMP_Beep1ModeState "";
BA_ "GenSigSendType" SG_ 384 AMP_Beep1ModeState 4;
BA_ "GenSigStartValue" SG_ 384 AMP_Beep1ModeState 3;
BA_ "NmNetworkRequest" SG_ 384 AMP_Beep1ModeState 1;
BA_ "TimeoutValue" SG_ 384 AMP_Beep1ModeState "0x3";
BA_REL_ "GenSigTimeoutTime" BU_SG_REL_ CLU SG_ 384 AMP_DistrInfoState 3500;
BA_REL_ "GenSigTimeoutTime" BU_SG_REL_ H_U SG_ 384 AMP_DistrInfoState 3500;
BA_ "Platform" SG_ 384 AMP_DistrInfoState "";
BA_ "GenSigSendType" SG_ 384 AMP_DistrInfoState 4;
BA_ "GenSigStartValue" SG_ 384 AMP_DistrInfoState 3;
BA_ "NmNetworkRequest" SG_ 384 AMP_DistrInfoState 1;
BA_ "TimeoutValue" SG_ 384 AMP_DistrInfoState "0x3";
BA_ "NmStationAddress" BU_ CGW 85;
BA_REL_ "GenSigTimeoutTime" BU_SG_REL_ CGW SG_ 384 AMP_INFORM_TO_IPM 3500;
BA_REL_ "GenSigTimeoutTime" BU_SG_REL_ CLU SG_ 384 AMP_INFORM_TO_IPM 3500;
BA_REL_ "GenSigTimeoutTime" BU_SG_REL_ H_U SG_ 384 AMP_INFORM_TO_IPM 3500;
BA_ "Platform" SG_ 384 AMP_INFORM_TO_IPM "";
BA_ "GenSigSendType" SG_ 384 AMP_INFORM_TO_IPM 4;
BA_ "GenSigStartValue" SG_ 384 AMP_INFORM_TO_IPM 3;
BA_ "NmNetworkRequest" SG_ 384 AMP_INFORM_TO_IPM 1;
BA_ "TimeoutValue" SG_ 384 AMP_INFORM_TO_IPM "0x3";
BA_ "NmStationAddress" BU_ TMU 75;
BA_ "DiagState" BO_ 2015 1;
BA_ "GenMsgILSupport" BO_ 2015 0;
BA_ "TpMessage" BO_ 2015 1;
BA_REL_ "GenSigTimeoutTime" BU_SG_REL_ AMP SG_ 2015 Byte0_TCP_7DF 0;
BA_REL_ "GenSigTimeoutTime" BU_SG_REL_ CLU SG_ 2015 Byte0_TCP_7DF 0;
BA_REL_ "GenSigTimeoutTime" BU_SG_REL_ H_U SG_ 2015 Byte0_TCP_7DF 0;
BA_REL_ "GenSigTimeoutTime" BU_SG_REL_ TMU SG_ 2015 Byte0_TCP_7DF 0;
BA_ "Platform" SG_ 2015 Byte0_TCP_7DF "";
BA_ "DiagState" BO_ 2015 1;
BA_ "GenMsgILSupport" BO_ 2015 0;
BA_ "TpMessage" BO_ 2015 1;
BA_REL_ "GenSigTimeoutTime" BU_SG_REL_ AMP SG_ 2015 Byte1_Data_7DF 0;
BA_REL_ "GenSigTimeoutTime" BU_SG_REL_ CLU SG_ 2015 Byte1_Data_7DF 0;
BA_REL_ "GenSigTimeoutTime" BU_SG_REL_ H_U SG_ 2015 Byte1_Data_7DF 0;
BA_REL_ "GenSigTimeoutTime" BU_SG_REL_ TMU SG_ 2015 Byte1_Data_7DF 0;
BA_ "Platform" SG_ 2015 Byte1_Data_7DF "";
BA_ "DiagState" BO_ 2015 1;
BA_ "GenMsgILSupport" BO_ 2015 0;
BA_ "TpMessage" BO_ 2015 1;
BA_REL_ "GenSigTimeoutTime" BU_SG_REL_ AMP SG_ 2015 Byte2_Data_7DF 0;
BA_REL_ "GenSigTimeoutTime" BU_SG_REL_ CLU SG_ 2015 Byte2_Data_7DF 0;
BA_REL_ "GenSigTimeoutTime" BU_SG_REL_ H_U SG_ 2015 Byte2_Data_7DF 0;
BA_REL_ "GenSigTimeoutTime" BU_SG_REL_ TMU SG_ 2015 Byte2_Data_7DF 0;
BA_ "Platform" SG_ 2015 Byte2_Data_7DF "";
BA_ "DiagState" BO_ 2015 1;
BA_ "GenMsgILSupport" BO_ 2015 0;
BA_ "TpMessage" BO_ 2015 1;
BA_REL_ "GenSigTimeoutTime" BU_SG_REL_ AMP SG_ 2015 Byte3_Data_7DF 0;
BA_REL_ "GenSigTimeoutTime" BU_SG_REL_ CLU SG_ 2015 Byte3_Data_7DF 0;
BA_REL_ "GenSigTimeoutTime" BU_SG_REL_ H_U SG_ 2015 Byte3_Data_7DF 0;
BA_REL_ "GenSigTimeoutTime" BU_SG_REL_ TMU SG_ 2015 Byte3_Data_7DF 0;
BA_ "Platform" SG_ 2015 Byte3_Data_7DF "";
BA_ "DiagState" BO_ 2015 1;
BA_ "GenMsgILSupport" BO_ 2015 0;
BA_ "TpMessage" BO_ 2015 1;
BA_REL_ "GenSigTimeoutTime" BU_SG_REL_ AMP SG_ 2015 Byte4_Data_7DF 0;
BA_REL_ "GenSigTimeoutTime" BU_SG_REL_ CLU SG_ 2015 Byte4_Data_7DF 0;
BA_REL_ "GenSigTimeoutTime" BU_SG_REL_ H_U SG_ 2015 Byte4_Data_7DF 0;
BA_REL_ "GenSigTimeoutTime" BU_SG_REL_ TMU SG_ 2015 Byte4_Data_7DF 0;
BA_ "Platform" SG_ 2015 Byte4_Data_7DF "";
BA_ "DiagState" BO_ 2015 1;
BA_ "GenMsgILSupport" BO_ 2015 0;
BA_ "TpMessage" BO_ 2015 1;
BA_REL_ "GenSigTimeoutTime" BU_SG_REL_ AMP SG_ 2015 Byte5_Data_7DF 0;
BA_REL_ "GenSigTimeoutTime" BU_SG_REL_ CLU SG_ 2015 Byte5_Data_7DF 0;
BA_REL_ "GenSigTimeoutTime" BU_SG_REL_ H_U SG_ 2015 Byte5_Data_7DF 0;
BA_REL_ "GenSigTimeoutTime" BU_SG_REL_ TMU SG_ 2015 Byte5_Data_7DF 0;
BA_ "Platform" SG_ 2015 Byte5_Data_7DF "";
BA_ "DiagState" BO_ 2015 1;
BA_ "GenMsgILSupport" BO_ 2015 0;
BA_ "TpMessage" BO_ 2015 1;
BA_REL_ "GenSigTimeoutTime" BU_SG_REL_ AMP SG_ 2015 Byte6_Data_7DF 0;
BA_REL_ "GenSigTimeoutTime" BU_SG_REL_ CLU SG_ 2015 Byte6_Data_7DF 0;
BA_REL_ "GenSigTimeoutTime" BU_SG_REL_ H_U SG_ 2015 Byte6_Data_7DF 0;
BA_REL_ "GenSigTimeoutTime" BU_SG_REL_ TMU SG_ 2015 Byte6_Data_7DF 0;
BA_ "Platform" SG_ 2015 Byte6_Data_7DF "";
BA_ "DiagState" BO_ 2015 1;
BA_ "GenMsgILSupport" BO_ 2015 0;
BA_ "TpMessage" BO_ 2015 1;
BA_REL_ "GenSigTimeoutTime" BU_SG_REL_ AMP SG_ 2015 Byte7_Data_7DF 0;
BA_REL_ "GenSigTimeoutTime" BU_SG_REL_ CLU SG_ 2015 Byte7_Data_7DF 0;
BA_REL_ "GenSigTimeoutTime" BU_SG_REL_ H_U SG_ 2015 Byte7_Data_7DF 0;
BA_REL_ "GenSigTimeoutTime" BU_SG_REL_ TMU SG_ 2015 Byte7_Data_7DF 0;
BA_ "Platform" SG_ 2015 Byte7_Data_7DF "";
BA_ "GenMsgSendType" BO_ 479 0;
BA_ "GenMsgCycleTime" BO_ 479 200;
BA_ "GenMsgStartDelayTime" BO_ 479 140;
BA_ "Platform" SG_ 479 Clu_OutTempC "D-Audio,Integrated AVN1.0 High,Integrated AVN1.0 Mid,Premium AVN 2.0";
BA_ "GenSigSendType" SG_ 479 Clu_OutTempC 3;
BA_ "GenSigStartValue" SG_ 479 Clu_OutTempC 255;
BA_ "TimeoutValue" SG_ 479 Clu_OutTempC "Invalid";
BA_ "Validity" SG_ 479 Clu_OutTempC 2;
BA_ "Platform" SG_ 479 Clu_OutTempF "D-Audio,Integrated AVN1.0 High,Integrated AVN1.0 Mid,Premium AVN 2.0";
BA_ "GenSigSendType" SG_ 479 Clu_OutTempF 3;
BA_ "GenSigStartValue" SG_ 479 Clu_OutTempF 255;
BA_ "TimeoutValue" SG_ 479 Clu_OutTempF "Invalid";
BA_ "Validity" SG_ 479 Clu_OutTempF 2;
BA_ "SigDescription" SG_ 479 C_InhibitNMT "* DO NOT use this signal value for any purpose unless the vehicle is M/T AND US vehicle model.
* This signal value is valid for M/T AND US vehicle only. for A/T or Non-US vehicles, the output of this value can be vary.

0x0 (Off) : Current Gear is not N
0x1 (On) : Current Gear is N
0x3 (Invalid) : For initial and timeout condition";
BA_ "Platform" SG_ 479 C_InhibitNMT "D-Audio,Integrated AVN1.0 High,Integrated AVN1.0 Mid,Standard AVN 4.0,Standard Audio 3.0,UVO3 (D-Audio Kia)";
BA_ "GenSigSendType" SG_ 479 C_InhibitNMT 3;
BA_ "GenSigStartValue" SG_ 479 C_InhibitNMT 3;
BA_ "TimeoutValue" SG_ 479 C_InhibitNMT "0x3";
BA_ "Validity" SG_ 479 C_InhibitNMT 2;
BA_ "SigDescription" SG_ 479 Clu_RheostatLvl "[Default Value]
Invalid (= Old value)";
BA_ "Platform" SG_ 479 Clu_RheostatLvl "";
BA_ "GenSigSendType" SG_ 479 Clu_RheostatLvl 3;
BA_ "GenSigStartValue" SG_ 479 Clu_RheostatLvl 31;
BA_ "TimeoutValue" SG_ 479 Clu_RheostatLvl "Old Value";
BA_ "GenMsgILSupport" BO_ 1269 0;
BA_ "TpMessage" BO_ 1269 1;
BA_ "TpTxIndex" BO_ 1269 45;
BA_REL_ "GenSigTimeoutTime" BU_SG_REL_ H_U SG_ 1269 Byte0_TCP_4F5 0;
BA_ "Platform" SG_ 1269 Byte0_TCP_4F5 "";
BA_ "GenMsgILSupport" BO_ 1269 0;
BA_ "TpMessage" BO_ 1269 1;
BA_ "TpTxIndex" BO_ 1269 45;
BA_REL_ "GenSigTimeoutTime" BU_SG_REL_ H_U SG_ 1269 Byte1_Data_4F5 0;
BA_ "Platform" SG_ 1269 Byte1_Data_4F5 "";
BA_ "GenMsgILSupport" BO_ 1269 0;
BA_ "TpMessage" BO_ 1269 1;
BA_ "TpTxIndex" BO_ 1269 45;
BA_REL_ "GenSigTimeoutTime" BU_SG_REL_ H_U SG_ 1269 Byte2_Data_4F5 0;
BA_ "Platform" SG_ 1269 Byte2_Data_4F5 "";
BA_ "GenMsgILSupport" BO_ 1269 0;
BA_ "TpMessage" BO_ 1269 1;
BA_ "TpTxIndex" BO_ 1269 45;
BA_REL_ "GenSigTimeoutTime" BU_SG_REL_ H_U SG_ 1269 Byte3_Data_4F5 0;
BA_ "Platform" SG_ 1269 Byte3_Data_4F5 "";
BA_ "GenMsgILSupport" BO_ 1269 0;
BA_ "TpMessage" BO_ 1269 1;
BA_ "TpTxIndex" BO_ 1269 45;
BA_REL_ "GenSigTimeoutTime" BU_SG_REL_ H_U SG_ 1269 Byte4_Data_4F5 0;
BA_ "Platform" SG_ 1269 Byte4_Data_4F5 "";
BA_ "GenMsgILSupport" BO_ 1269 0;
BA_ "TpMessage" BO_ 1269 1;
BA_ "TpTxIndex" BO_ 1269 45;
BA_REL_ "GenSigTimeoutTime" BU_SG_REL_ H_U SG_ 1269 Byte5_Data_4F5 0;
BA_ "Platform" SG_ 1269 Byte5_Data_4F5 "";
BA_ "GenMsgILSupport" BO_ 1269 0;
BA_ "TpMessage" BO_ 1269 1;
BA_ "TpTxIndex" BO_ 1269 45;
BA_REL_ "GenSigTimeoutTime" BU_SG_REL_ H_U SG_ 1269 Byte6_Data_4F5 0;
BA_ "Platform" SG_ 1269 Byte6_Data_4F5 "";
BA_ "GenMsgILSupport" BO_ 1269 0;
BA_ "TpMessage" BO_ 1269 1;
BA_ "TpTxIndex" BO_ 1269 45;
BA_REL_ "GenSigTimeoutTime" BU_SG_REL_ H_U SG_ 1269 Byte7_Data_4F5 0;
BA_ "Platform" SG_ 1269 Byte7_Data_4F5 "";
BA_ "GenMsgILSupport" BO_ 1261 0;
BA_ "TpMessage" BO_ 1261 1;
BA_ "TpTxIndex" BO_ 1261 6;
BA_REL_ "GenSigTimeoutTime" BU_SG_REL_ H_U SG_ 1261 Byte0_TCP_4ED 0;
BA_ "Platform" SG_ 1261 Byte0_TCP_4ED "";
BA_ "GenMsgILSupport" BO_ 1261 0;
BA_ "TpMessage" BO_ 1261 1;
BA_ "TpTxIndex" BO_ 1261 6;
BA_REL_ "GenSigTimeoutTime" BU_SG_REL_ H_U SG_ 1261 Byte1_Data_4ED 0;
BA_ "Platform" SG_ 1261 Byte1_Data_4ED "";
BA_ "GenMsgILSupport" BO_ 1261 0;
BA_ "TpMessage" BO_ 1261 1;
BA_ "TpTxIndex" BO_ 1261 6;
BA_REL_ "GenSigTimeoutTime" BU_SG_REL_ H_U SG_ 1261 Byte2_Data_4ED 0;
BA_ "Platform" SG_ 1261 Byte2_Data_4ED "";
BA_ "GenMsgILSupport" BO_ 1261 0;
BA_ "TpMessage" BO_ 1261 1;
BA_ "TpTxIndex" BO_ 1261 6;
BA_REL_ "GenSigTimeoutTime" BU_SG_REL_ H_U SG_ 1261 Byte3_Data_4ED 0;
BA_ "Platform" SG_ 1261 Byte3_Data_4ED "";
BA_ "GenMsgILSupport" BO_ 1261 0;
BA_ "TpMessage" BO_ 1261 1;
BA_ "TpTxIndex" BO_ 1261 6;
BA_REL_ "GenSigTimeoutTime" BU_SG_REL_ H_U SG_ 1261 Byte4_Data_4ED 0;
BA_ "Platform" SG_ 1261 Byte4_Data_4ED "";
BA_ "GenMsgILSupport" BO_ 1261 0;
BA_ "TpMessage" BO_ 1261 1;
BA_ "TpTxIndex" BO_ 1261 6;
BA_REL_ "GenSigTimeoutTime" BU_SG_REL_ H_U SG_ 1261 Byte5_Data_4ED 0;
BA_ "Platform" SG_ 1261 Byte5_Data_4ED "";
BA_ "GenMsgILSupport" BO_ 1261 0;
BA_ "TpMessage" BO_ 1261 1;
BA_ "TpTxIndex" BO_ 1261 6;
BA_REL_ "GenSigTimeoutTime" BU_SG_REL_ H_U SG_ 1261 Byte6_Data_4ED 0;
BA_ "Platform" SG_ 1261 Byte6_Data_4ED "";
BA_ "GenMsgILSupport" BO_ 1261 0;
BA_ "TpMessage" BO_ 1261 1;
BA_ "TpTxIndex" BO_ 1261 6;
BA_REL_ "GenSigTimeoutTime" BU_SG_REL_ H_U SG_ 1261 Byte7_Data_4ED 0;
BA_ "Platform" SG_ 1261 Byte7_Data_4ED "";
BA_ "GenMsgILSupport" BO_ 1271 0;
BA_ "TpMessage" BO_ 1271 1;
BA_ "TpTxIndex" BO_ 1271 46;
BA_REL_ "GenSigTimeoutTime" BU_SG_REL_ H_U SG_ 1271 Byte0_TCP_4F7 0;
BA_ "Platform" SG_ 1271 Byte0_TCP_4F7 "";
BA_ "GenMsgILSupport" BO_ 1271 0;
BA_ "TpMessage" BO_ 1271 1;
BA_ "TpTxIndex" BO_ 1271 46;
BA_REL_ "GenSigTimeoutTime" BU_SG_REL_ H_U SG_ 1271 Byte1_Data_4F7 0;
BA_ "Platform" SG_ 1271 Byte1_Data_4F7 "";
BA_ "GenMsgILSupport" BO_ 1271 0;
BA_ "TpMessage" BO_ 1271 1;
BA_ "TpTxIndex" BO_ 1271 46;
BA_REL_ "GenSigTimeoutTime" BU_SG_REL_ H_U SG_ 1271 Byte2_Data_4F7 0;
BA_ "Platform" SG_ 1271 Byte2_Data_4F7 "";
BA_ "GenMsgILSupport" BO_ 1271 0;
BA_ "TpMessage" BO_ 1271 1;
BA_ "TpTxIndex" BO_ 1271 46;
BA_REL_ "GenSigTimeoutTime" BU_SG_REL_ H_U SG_ 1271 Byte3_Data_4F7 0;
BA_ "Platform" SG_ 1271 Byte3_Data_4F7 "";
BA_ "GenMsgILSupport" BO_ 1271 0;
BA_ "TpMessage" BO_ 1271 1;
BA_ "TpTxIndex" BO_ 1271 46;
BA_REL_ "GenSigTimeoutTime" BU_SG_REL_ H_U SG_ 1271 Byte4_Data_4F7 0;
BA_ "Platform" SG_ 1271 Byte4_Data_4F7 "";
BA_ "GenMsgILSupport" BO_ 1271 0;
BA_ "TpMessage" BO_ 1271 1;
BA_ "TpTxIndex" BO_ 1271 46;
BA_REL_ "GenSigTimeoutTime" BU_SG_REL_ H_U SG_ 1271 Byte5_Data_4F7 0;
BA_ "Platform" SG_ 1271 Byte5_Data_4F7 "";
BA_ "GenMsgILSupport" BO_ 1271 0;
BA_ "TpMessage" BO_ 1271 1;
BA_ "TpTxIndex" BO_ 1271 46;
BA_REL_ "GenSigTimeoutTime" BU_SG_REL_ H_U SG_ 1271 Byte6_Data_4F7 0;
BA_ "Platform" SG_ 1271 Byte6_Data_4F7 "";
BA_ "GenMsgILSupport" BO_ 1271 0;
BA_ "TpMessage" BO_ 1271 1;
BA_ "TpTxIndex" BO_ 1271 46;
BA_REL_ "GenSigTimeoutTime" BU_SG_REL_ H_U SG_ 1271 Byte7_Data_4F7 0;
BA_ "Platform" SG_ 1271 Byte7_Data_4F7 "";
BA_ "GenMsgILSupport" BO_ 1265 0;
BA_ "TpMessage" BO_ 1265 1;
BA_ "TpTxIndex" BO_ 1265 38;
BA_REL_ "GenSigTimeoutTime" BU_SG_REL_ H_U SG_ 1265 Byte0_TCP_4F1 0;
BA_ "Platform" SG_ 1265 Byte0_TCP_4F1 "";
BA_ "GenMsgILSupport" BO_ 1265 0;
BA_ "TpMessage" BO_ 1265 1;
BA_ "TpTxIndex" BO_ 1265 38;
BA_REL_ "GenSigTimeoutTime" BU_SG_REL_ H_U SG_ 1265 Byte1_Data_4F1 0;
BA_ "Platform" SG_ 1265 Byte1_Data_4F1 "";
BA_ "GenMsgILSupport" BO_ 1265 0;
BA_ "TpMessage" BO_ 1265 1;
BA_ "TpTxIndex" BO_ 1265 38;
BA_REL_ "GenSigTimeoutTime" BU_SG_REL_ H_U SG_ 1265 Byte2_Data_4F1 0;
BA_ "Platform" SG_ 1265 Byte2_Data_4F1 "";
BA_ "GenMsgILSupport" BO_ 1265 0;
BA_ "TpMessage" BO_ 1265 1;
BA_ "TpTxIndex" BO_ 1265 38;
BA_REL_ "GenSigTimeoutTime" BU_SG_REL_ H_U SG_ 1265 Byte3_Data_4F1 0;
BA_ "Platform" SG_ 1265 Byte3_Data_4F1 "";
BA_ "GenMsgILSupport" BO_ 1265 0;
BA_ "TpMessage" BO_ 1265 1;
BA_ "TpTxIndex" BO_ 1265 38;
BA_REL_ "GenSigTimeoutTime" BU_SG_REL_ H_U SG_ 1265 Byte4_Data_4F1 0;
BA_ "Platform" SG_ 1265 Byte4_Data_4F1 "";
BA_ "GenMsgILSupport" BO_ 1265 0;
BA_ "TpMessage" BO_ 1265 1;
BA_ "TpTxIndex" BO_ 1265 38;
BA_REL_ "GenSigTimeoutTime" BU_SG_REL_ H_U SG_ 1265 Byte5_Data_4F1 0;
BA_ "Platform" SG_ 1265 Byte5_Data_4F1 "";
BA_ "GenMsgILSupport" BO_ 1265 0;
BA_ "TpMessage" BO_ 1265 1;
BA_ "TpTxIndex" BO_ 1265 38;
BA_REL_ "GenSigTimeoutTime" BU_SG_REL_ H_U SG_ 1265 Byte6_Data_4F1 0;
BA_ "Platform" SG_ 1265 Byte6_Data_4F1 "";
BA_ "GenMsgILSupport" BO_ 1265 0;
BA_ "TpMessage" BO_ 1265 1;
BA_ "TpTxIndex" BO_ 1265 38;
BA_REL_ "GenSigTimeoutTime" BU_SG_REL_ H_U SG_ 1265 Byte7_Data_4F1 0;
BA_ "Platform" SG_ 1265 Byte7_Data_4F1 "";
BA_ "GenMsgILSupport" BO_ 1267 0;
BA_ "TpMessage" BO_ 1267 1;
BA_ "TpTxIndex" BO_ 1267 44;
BA_REL_ "GenSigTimeoutTime" BU_SG_REL_ H_U SG_ 1267 Byte0_TCP_4F3 0;
BA_ "Platform" SG_ 1267 Byte0_TCP_4F3 "";
BA_ "GenMsgILSupport" BO_ 1267 0;
BA_ "TpMessage" BO_ 1267 1;
BA_ "TpTxIndex" BO_ 1267 44;
BA_REL_ "GenSigTimeoutTime" BU_SG_REL_ H_U SG_ 1267 Byte1_Data_4F3 0;
BA_ "Platform" SG_ 1267 Byte1_Data_4F3 "";
BA_ "GenMsgILSupport" BO_ 1267 0;
BA_ "TpMessage" BO_ 1267 1;
BA_ "TpTxIndex" BO_ 1267 44;
BA_REL_ "GenSigTimeoutTime" BU_SG_REL_ H_U SG_ 1267 Byte2_Data_4F3 0;
BA_ "Platform" SG_ 1267 Byte2_Data_4F3 "";
BA_ "GenMsgILSupport" BO_ 1267 0;
BA_ "TpMessage" BO_ 1267 1;
BA_ "TpTxIndex" BO_ 1267 44;
BA_REL_ "GenSigTimeoutTime" BU_SG_REL_ H_U SG_ 1267 Byte3_Data_4F3 0;
BA_ "Platform" SG_ 1267 Byte3_Data_4F3 "";
BA_ "GenMsgILSupport" BO_ 1267 0;
BA_ "TpMessage" BO_ 1267 1;
BA_ "TpTxIndex" BO_ 1267 44;
BA_REL_ "GenSigTimeoutTime" BU_SG_REL_ H_U SG_ 1267 Byte4_Data_4F3 0;
BA_ "Platform" SG_ 1267 Byte4_Data_4F3 "";
BA_ "GenMsgILSupport" BO_ 1267 0;
BA_ "TpMessage" BO_ 1267 1;
BA_ "TpTxIndex" BO_ 1267 44;
BA_REL_ "GenSigTimeoutTime" BU_SG_REL_ H_U SG_ 1267 Byte5_Data_4F3 0;
BA_ "Platform" SG_ 1267 Byte5_Data_4F3 "";
BA_ "GenMsgILSupport" BO_ 1267 0;
BA_ "TpMessage" BO_ 1267 1;
BA_ "TpTxIndex" BO_ 1267 44;
BA_REL_ "GenSigTimeoutTime" BU_SG_REL_ H_U SG_ 1267 Byte6_Data_4F3 0;
BA_ "Platform" SG_ 1267 Byte6_Data_4F3 "";
BA_ "GenMsgILSupport" BO_ 1267 0;
BA_ "TpMessage" BO_ 1267 1;
BA_ "TpTxIndex" BO_ 1267 44;
BA_REL_ "GenSigTimeoutTime" BU_SG_REL_ H_U SG_ 1267 Byte7_Data_4F3 0;
BA_ "Platform" SG_ 1267 Byte7_Data_4F3 "";
BA_ "GenMsgILSupport" BO_ 1257 0;
BA_ "TpMessage" BO_ 1257 1;
BA_ "TpTxIndex" BO_ 1257 36;
BA_REL_ "GenSigTimeoutTime" BU_SG_REL_ H_U SG_ 1257 Byte0_TCP_4E9 0;
BA_ "Platform" SG_ 1257 Byte0_TCP_4E9 "";
BA_ "GenMsgILSupport" BO_ 1257 0;
BA_ "TpMessage" BO_ 1257 1;
BA_ "TpTxIndex" BO_ 1257 36;
BA_REL_ "GenSigTimeoutTime" BU_SG_REL_ H_U SG_ 1257 Byte1_Data_4E9 0;
BA_ "Platform" SG_ 1257 Byte1_Data_4E9 "";
BA_ "GenMsgILSupport" BO_ 1257 0;
BA_ "TpMessage" BO_ 1257 1;
BA_ "TpTxIndex" BO_ 1257 36;
BA_REL_ "GenSigTimeoutTime" BU_SG_REL_ H_U SG_ 1257 Byte2_Data_4E9 0;
BA_ "Platform" SG_ 1257 Byte2_Data_4E9 "";
BA_ "GenMsgILSupport" BO_ 1257 0;
BA_ "TpMessage" BO_ 1257 1;
BA_ "TpTxIndex" BO_ 1257 36;
BA_REL_ "GenSigTimeoutTime" BU_SG_REL_ H_U SG_ 1257 Byte3_Data_4E9 0;
BA_ "Platform" SG_ 1257 Byte3_Data_4E9 "";
BA_ "GenMsgILSupport" BO_ 1257 0;
BA_ "TpMessage" BO_ 1257 1;
BA_ "TpTxIndex" BO_ 1257 36;
BA_REL_ "GenSigTimeoutTime" BU_SG_REL_ H_U SG_ 1257 Byte4_Data_4E9 0;
BA_ "Platform" SG_ 1257 Byte4_Data_4E9 "";
BA_ "GenMsgILSupport" BO_ 1257 0;
BA_ "TpMessage" BO_ 1257 1;
BA_ "TpTxIndex" BO_ 1257 36;
BA_REL_ "GenSigTimeoutTime" BU_SG_REL_ H_U SG_ 1257 Byte5_Data_4E9 0;
BA_ "Platform" SG_ 1257 Byte5_Data_4E9 "";
BA_ "GenMsgILSupport" BO_ 1257 0;
BA_ "TpMessage" BO_ 1257 1;
BA_ "TpTxIndex" BO_ 1257 36;
BA_REL_ "GenSigTimeoutTime" BU_SG_REL_ H_U SG_ 1257 Byte6_Data_4E9 0;
BA_ "Platform" SG_ 1257 Byte6_Data_4E9 "";
BA_ "GenMsgILSupport" BO_ 1257 0;
BA_ "TpMessage" BO_ 1257 1;
BA_ "TpTxIndex" BO_ 1257 36;
BA_REL_ "GenSigTimeoutTime" BU_SG_REL_ H_U SG_ 1257 Byte7_Data_4E9 0;
BA_ "Platform" SG_ 1257 Byte7_Data_4E9 "";
BA_ "GenMsgILSupport" BO_ 1273 0;
BA_ "TpMessage" BO_ 1273 1;
BA_ "TpTxIndex" BO_ 1273 47;
BA_REL_ "GenSigTimeoutTime" BU_SG_REL_ H_U SG_ 1273 Byte0_TCP_4F9 0;
BA_ "Platform" SG_ 1273 Byte0_TCP_4F9 "";
BA_ "GenMsgILSupport" BO_ 1273 0;
BA_ "TpMessage" BO_ 1273 1;
BA_ "TpTxIndex" BO_ 1273 47;
BA_REL_ "GenSigTimeoutTime" BU_SG_REL_ H_U SG_ 1273 Byte1_Data_4F9 0;
BA_ "Platform" SG_ 1273 Byte1_Data_4F9 "";
BA_ "GenMsgILSupport" BO_ 1273 0;
BA_ "TpMessage" BO_ 1273 1;
BA_ "TpTxIndex" BO_ 1273 47;
BA_REL_ "GenSigTimeoutTime" BU_SG_REL_ H_U SG_ 1273 Byte2_Data_4F9 0;
BA_ "Platform" SG_ 1273 Byte2_Data_4F9 "";
BA_ "GenMsgILSupport" BO_ 1273 0;
BA_ "TpMessage" BO_ 1273 1;
BA_ "TpTxIndex" BO_ 1273 47;
BA_REL_ "GenSigTimeoutTime" BU_SG_REL_ H_U SG_ 1273 Byte3_Data_4F9 0;
BA_ "Platform" SG_ 1273 Byte3_Data_4F9 "";
BA_ "GenMsgILSupport" BO_ 1273 0;
BA_ "TpMessage" BO_ 1273 1;
BA_ "TpTxIndex" BO_ 1273 47;
BA_REL_ "GenSigTimeoutTime" BU_SG_REL_ H_U SG_ 1273 Byte4_Data_4F9 0;
BA_ "Platform" SG_ 1273 Byte4_Data_4F9 "";
BA_ "GenMsgILSupport" BO_ 1273 0;
BA_ "TpMessage" BO_ 1273 1;
BA_ "TpTxIndex" BO_ 1273 47;
BA_REL_ "GenSigTimeoutTime" BU_SG_REL_ H_U SG_ 1273 Byte5_Data_4F9 0;
BA_ "Platform" SG_ 1273 Byte5_Data_4F9 "";
BA_ "GenMsgILSupport" BO_ 1273 0;
BA_ "TpMessage" BO_ 1273 1;
BA_ "TpTxIndex" BO_ 1273 47;
BA_REL_ "GenSigTimeoutTime" BU_SG_REL_ H_U SG_ 1273 Byte6_Data_4F9 0;
BA_ "Platform" SG_ 1273 Byte6_Data_4F9 "";
BA_ "GenMsgILSupport" BO_ 1273 0;
BA_ "TpMessage" BO_ 1273 1;
BA_ "TpTxIndex" BO_ 1273 47;
BA_REL_ "GenSigTimeoutTime" BU_SG_REL_ H_U SG_ 1273 Byte7_Data_4F9 0;
BA_ "Platform" SG_ 1273 Byte7_Data_4F9 "";
BA_ "GenMsgILSupport" BO_ 1263 0;
BA_ "TpMessage" BO_ 1263 1;
BA_ "TpTxIndex" BO_ 1263 39;
BA_REL_ "GenSigTimeoutTime" BU_SG_REL_ H_U SG_ 1263 Byte0_TCP_4EF 0;
BA_ "Platform" SG_ 1263 Byte0_TCP_4EF "";
BA_ "GenMsgILSupport" BO_ 1263 0;
BA_ "TpMessage" BO_ 1263 1;
BA_ "TpTxIndex" BO_ 1263 39;
BA_REL_ "GenSigTimeoutTime" BU_SG_REL_ H_U SG_ 1263 Byte1_Data_4EF 0;
BA_ "Platform" SG_ 1263 Byte1_Data_4EF "";
BA_ "GenMsgILSupport" BO_ 1263 0;
BA_ "TpMessage" BO_ 1263 1;
BA_ "TpTxIndex" BO_ 1263 39;
BA_REL_ "GenSigTimeoutTime" BU_SG_REL_ H_U SG_ 1263 Byte2_Data_4EF 0;
BA_ "Platform" SG_ 1263 Byte2_Data_4EF "";
BA_ "GenMsgILSupport" BO_ 1263 0;
BA_ "TpMessage" BO_ 1263 1;
BA_ "TpTxIndex" BO_ 1263 39;
BA_REL_ "GenSigTimeoutTime" BU_SG_REL_ H_U SG_ 1263 Byte3_Data_4EF 0;
BA_ "Platform" SG_ 1263 Byte3_Data_4EF "";
BA_ "GenMsgILSupport" BO_ 1263 0;
BA_ "TpMessage" BO_ 1263 1;
BA_ "TpTxIndex" BO_ 1263 39;
BA_REL_ "GenSigTimeoutTime" BU_SG_REL_ H_U SG_ 1263 Byte4_Data_4EF 0;
BA_ "Platform" SG_ 1263 Byte4_Data_4EF "";
BA_ "GenMsgILSupport" BO_ 1263 0;
BA_ "TpMessage" BO_ 1263 1;
BA_ "TpTxIndex" BO_ 1263 39;
BA_REL_ "GenSigTimeoutTime" BU_SG_REL_ H_U SG_ 1263 Byte5_Data_4EF 0;
BA_ "Platform" SG_ 1263 Byte5_Data_4EF "";
BA_ "GenMsgILSupport" BO_ 1263 0;
BA_ "TpMessage" BO_ 1263 1;
BA_ "TpTxIndex" BO_ 1263 39;
BA_REL_ "GenSigTimeoutTime" BU_SG_REL_ H_U SG_ 1263 Byte6_Data_4EF 0;
BA_ "Platform" SG_ 1263 Byte6_Data_4EF "";
BA_ "GenMsgILSupport" BO_ 1263 0;
BA_ "TpMessage" BO_ 1263 1;
BA_ "TpTxIndex" BO_ 1263 39;
BA_REL_ "GenSigTimeoutTime" BU_SG_REL_ H_U SG_ 1263 Byte7_Data_4EF 0;
BA_ "Platform" SG_ 1263 Byte7_Data_4EF "";
BA_ "GenMsgILSupport" BO_ 1277 0;
BA_ "TpMessage" BO_ 1277 1;
BA_ "TpTxIndex" BO_ 1277 49;
BA_REL_ "GenSigTimeoutTime" BU_SG_REL_ H_U SG_ 1277 Byte0_TCP_4FD 0;
BA_ "Platform" SG_ 1277 Byte0_TCP_4FD "";
BA_ "GenMsgILSupport" BO_ 1277 0;
BA_ "TpMessage" BO_ 1277 1;
BA_ "TpTxIndex" BO_ 1277 49;
BA_REL_ "GenSigTimeoutTime" BU_SG_REL_ H_U SG_ 1277 Byte1_Data_4FD 0;
BA_ "Platform" SG_ 1277 Byte1_Data_4FD "";
BA_ "GenMsgILSupport" BO_ 1277 0;
BA_ "TpMessage" BO_ 1277 1;
BA_ "TpTxIndex" BO_ 1277 49;
BA_REL_ "GenSigTimeoutTime" BU_SG_REL_ H_U SG_ 1277 Byte2_Data_4FD 0;
BA_ "Platform" SG_ 1277 Byte2_Data_4FD "";
BA_ "GenMsgILSupport" BO_ 1277 0;
BA_ "TpMessage" BO_ 1277 1;
BA_ "TpTxIndex" BO_ 1277 49;
BA_REL_ "GenSigTimeoutTime" BU_SG_REL_ H_U SG_ 1277 Byte3_Data_4FD 0;
BA_ "Platform" SG_ 1277 Byte3_Data_4FD "";
BA_ "GenMsgILSupport" BO_ 1277 0;
BA_ "TpMessage" BO_ 1277 1;
BA_ "TpTxIndex" BO_ 1277 49;
BA_REL_ "GenSigTimeoutTime" BU_SG_REL_ H_U SG_ 1277 Byte4_Data_4FD 0;
BA_ "Platform" SG_ 1277 Byte4_Data_4FD "";
BA_ "GenMsgILSupport" BO_ 1277 0;
BA_ "TpMessage" BO_ 1277 1;
BA_ "TpTxIndex" BO_ 1277 49;
BA_REL_ "GenSigTimeoutTime" BU_SG_REL_ H_U SG_ 1277 Byte5_Data_4FD 0;
BA_ "Platform" SG_ 1277 Byte5_Data_4FD "";
BA_ "GenMsgILSupport" BO_ 1277 0;
BA_ "TpMessage" BO_ 1277 1;
BA_ "TpTxIndex" BO_ 1277 49;
BA_REL_ "GenSigTimeoutTime" BU_SG_REL_ H_U SG_ 1277 Byte6_Data_4FD 0;
BA_ "Platform" SG_ 1277 Byte6_Data_4FD "";
BA_ "GenMsgILSupport" BO_ 1277 0;
BA_ "TpMessage" BO_ 1277 1;
BA_ "TpTxIndex" BO_ 1277 49;
BA_REL_ "GenSigTimeoutTime" BU_SG_REL_ H_U SG_ 1277 Byte7_Data_4FD 0;
BA_ "Platform" SG_ 1277 Byte7_Data_4FD "";
BA_ "GenMsgILSupport" BO_ 1251 0;
BA_ "TpMessage" BO_ 1251 1;
BA_ "TpTxIndex" BO_ 1251 33;
BA_REL_ "GenSigTimeoutTime" BU_SG_REL_ H_U SG_ 1251 Byte0_TCP_4E3 0;
BA_ "Platform" SG_ 1251 Byte0_TCP_4E3 "";
BA_ "GenMsgILSupport" BO_ 1251 0;
BA_ "TpMessage" BO_ 1251 1;
BA_ "TpTxIndex" BO_ 1251 33;
BA_REL_ "GenSigTimeoutTime" BU_SG_REL_ H_U SG_ 1251 Byte1_Data_4E3 0;
BA_ "Platform" SG_ 1251 Byte1_Data_4E3 "";
BA_ "GenMsgILSupport" BO_ 1251 0;
BA_ "TpMessage" BO_ 1251 1;
BA_ "TpTxIndex" BO_ 1251 33;
BA_REL_ "GenSigTimeoutTime" BU_SG_REL_ H_U SG_ 1251 Byte2_Data_4E3 0;
BA_ "Platform" SG_ 1251 Byte2_Data_4E3 "";
BA_ "GenMsgILSupport" BO_ 1251 0;
BA_ "TpMessage" BO_ 1251 1;
BA_ "TpTxIndex" BO_ 1251 33;
BA_REL_ "GenSigTimeoutTime" BU_SG_REL_ H_U SG_ 1251 Byte3_Data_4E3 0;
BA_ "Platform" SG_ 1251 Byte3_Data_4E3 "";
BA_ "GenMsgILSupport" BO_ 1251 0;
BA_ "TpMessage" BO_ 1251 1;
BA_ "TpTxIndex" BO_ 1251 33;
BA_REL_ "GenSigTimeoutTime" BU_SG_REL_ H_U SG_ 1251 Byte4_Data_4E3 0;
BA_ "Platform" SG_ 1251 Byte4_Data_4E3 "";
BA_ "GenMsgILSupport" BO_ 1251 0;
BA_ "TpMessage" BO_ 1251 1;
BA_ "TpTxIndex" BO_ 1251 33;
BA_REL_ "GenSigTimeoutTime" BU_SG_REL_ H_U SG_ 1251 Byte5_Data_4E3 0;
BA_ "Platform" SG_ 1251 Byte5_Data_4E3 "";
BA_ "GenMsgILSupport" BO_ 1251 0;
BA_ "TpMessage" BO_ 1251 1;
BA_ "TpTxIndex" BO_ 1251 33;
BA_REL_ "GenSigTimeoutTime" BU_SG_REL_ H_U SG_ 1251 Byte6_Data_4E3 0;
BA_ "Platform" SG_ 1251 Byte6_Data_4E3 "";
BA_ "GenMsgILSupport" BO_ 1251 0;
BA_ "TpMessage" BO_ 1251 1;
BA_ "TpTxIndex" BO_ 1251 33;
BA_REL_ "GenSigTimeoutTime" BU_SG_REL_ H_U SG_ 1251 Byte7_Data_4E3 0;
BA_ "Platform" SG_ 1251 Byte7_Data_4E3 "";
BA_ "GenMsgILSupport" BO_ 1275 0;
BA_ "TpMessage" BO_ 1275 1;
BA_ "TpTxIndex" BO_ 1275 48;
BA_REL_ "GenSigTimeoutTime" BU_SG_REL_ H_U SG_ 1275 Byte0_TCP_4FB 0;
BA_ "Platform" SG_ 1275 Byte0_TCP_4FB "";
BA_ "GenMsgILSupport" BO_ 1275 0;
BA_ "TpMessage" BO_ 1275 1;
BA_ "TpTxIndex" BO_ 1275 48;
BA_REL_ "GenSigTimeoutTime" BU_SG_REL_ H_U SG_ 1275 Byte1_Data_4FB 0;
BA_ "Platform" SG_ 1275 Byte1_Data_4FB "";
BA_ "GenMsgILSupport" BO_ 1275 0;
BA_ "TpMessage" BO_ 1275 1;
BA_ "TpTxIndex" BO_ 1275 48;
BA_REL_ "GenSigTimeoutTime" BU_SG_REL_ H_U SG_ 1275 Byte2_Data_4FB 0;
BA_ "Platform" SG_ 1275 Byte2_Data_4FB "";
BA_ "GenMsgILSupport" BO_ 1275 0;
BA_ "TpMessage" BO_ 1275 1;
BA_ "TpTxIndex" BO_ 1275 48;
BA_REL_ "GenSigTimeoutTime" BU_SG_REL_ H_U SG_ 1275 Byte3_Data_4FB 0;
BA_ "Platform" SG_ 1275 Byte3_Data_4FB "";
BA_ "GenMsgILSupport" BO_ 1275 0;
BA_ "TpMessage" BO_ 1275 1;
BA_ "TpTxIndex" BO_ 1275 48;
BA_REL_ "GenSigTimeoutTime" BU_SG_REL_ H_U SG_ 1275 Byte4_Data_4FB 0;
BA_ "Platform" SG_ 1275 Byte4_Data_4FB "";
BA_ "GenMsgILSupport" BO_ 1275 0;
BA_ "TpMessage" BO_ 1275 1;
BA_ "TpTxIndex" BO_ 1275 48;
BA_REL_ "GenSigTimeoutTime" BU_SG_REL_ H_U SG_ 1275 Byte5_Data_4FB 0;
BA_ "Platform" SG_ 1275 Byte5_Data_4FB "";
BA_ "GenMsgILSupport" BO_ 1275 0;
BA_ "TpMessage" BO_ 1275 1;
BA_ "TpTxIndex" BO_ 1275 48;
BA_REL_ "GenSigTimeoutTime" BU_SG_REL_ H_U SG_ 1275 Byte6_Data_4FB 0;
BA_ "Platform" SG_ 1275 Byte6_Data_4FB "";
BA_ "GenMsgILSupport" BO_ 1275 0;
BA_ "TpMessage" BO_ 1275 1;
BA_ "TpTxIndex" BO_ 1275 48;
BA_REL_ "GenSigTimeoutTime" BU_SG_REL_ H_U SG_ 1275 Byte7_Data_4FB 0;
BA_ "Platform" SG_ 1275 Byte7_Data_4FB "";
BA_ "GenMsgILSupport" BO_ 1259 0;
BA_ "TpMessage" BO_ 1259 1;
BA_ "TpTxIndex" BO_ 1259 37;
BA_REL_ "GenSigTimeoutTime" BU_SG_REL_ H_U SG_ 1259 Byte0_TCP_4EB 0;
BA_ "Platform" SG_ 1259 Byte0_TCP_4EB "";
BA_ "GenMsgILSupport" BO_ 1259 0;
BA_ "TpMessage" BO_ 1259 1;
BA_ "TpTxIndex" BO_ 1259 37;
BA_REL_ "GenSigTimeoutTime" BU_SG_REL_ H_U SG_ 1259 Byte1_Data_4EB 0;
BA_ "Platform" SG_ 1259 Byte1_Data_4EB "";
BA_ "GenMsgILSupport" BO_ 1259 0;
BA_ "TpMessage" BO_ 1259 1;
BA_ "TpTxIndex" BO_ 1259 37;
BA_REL_ "GenSigTimeoutTime" BU_SG_REL_ H_U SG_ 1259 Byte2_Data_4EB 0;
BA_ "Platform" SG_ 1259 Byte2_Data_4EB "";
BA_ "GenMsgILSupport" BO_ 1259 0;
BA_ "TpMessage" BO_ 1259 1;
BA_ "TpTxIndex" BO_ 1259 37;
BA_REL_ "GenSigTimeoutTime" BU_SG_REL_ H_U SG_ 1259 Byte3_Data_4EB 0;
BA_ "Platform" SG_ 1259 Byte3_Data_4EB "";
BA_ "GenMsgILSupport" BO_ 1259 0;
BA_ "TpMessage" BO_ 1259 1;
BA_ "TpTxIndex" BO_ 1259 37;
BA_REL_ "GenSigTimeoutTime" BU_SG_REL_ H_U SG_ 1259 Byte4_Data_4EB 0;
BA_ "Platform" SG_ 1259 Byte4_Data_4EB "";
BA_ "GenMsgILSupport" BO_ 1259 0;
BA_ "TpMessage" BO_ 1259 1;
BA_ "TpTxIndex" BO_ 1259 37;
BA_REL_ "GenSigTimeoutTime" BU_SG_REL_ H_U SG_ 1259 Byte5_Data_4EB 0;
BA_ "Platform" SG_ 1259 Byte5_Data_4EB "";
BA_ "GenMsgILSupport" BO_ 1259 0;
BA_ "TpMessage" BO_ 1259 1;
BA_ "TpTxIndex" BO_ 1259 37;
BA_REL_ "GenSigTimeoutTime" BU_SG_REL_ H_U SG_ 1259 Byte6_Data_4EB 0;
BA_ "Platform" SG_ 1259 Byte6_Data_4EB "";
BA_ "GenMsgILSupport" BO_ 1259 0;
BA_ "TpMessage" BO_ 1259 1;
BA_ "TpTxIndex" BO_ 1259 37;
BA_REL_ "GenSigTimeoutTime" BU_SG_REL_ H_U SG_ 1259 Byte7_Data_4EB 0;
BA_ "Platform" SG_ 1259 Byte7_Data_4EB "";
BA_ "GenMsgSendType" BO_ 277 0;
BA_ "GenMsgCycleTime" BO_ 277 200;
BA_ "GenMsgCycleTimeFast" BO_ 277 40;
BA_ "GenMsgNrOfRepetition" BO_ 277 3;
BA_ "GenMsgStartDelayTime" BO_ 277 170;
BA_REL_ "GenSigTimeoutTime" BU_SG_REL_ CLU SG_ 277 TBT_Display_Type 750;
BA_ "SigDescription" SG_ 277 TBT_Display_Type "Signal value table description abbreviation reference
C : Center
R : Right
M : Middle
L : Left
WP : Way Point";
BA_ "Platform" SG_ 277 TBT_Display_Type "";
BA_ "GenSigSendType" SG_ 277 TBT_Display_Type 4;
BA_ "GenSigStartValue" SG_ 277 TBT_Display_Type 255;
BA_ "NmNetworkRequest" SG_ 277 TBT_Display_Type 1;
BA_ "TimeoutValue" SG_ 277 TBT_Display_Type "Old Value";
BA_ "Platform" SG_ 277 TBT_Side_Street "";
BA_ "GenSigSendType" SG_ 277 TBT_Side_Street 4;
BA_ "GenSigStartValue" SG_ 277 TBT_Side_Street 65535;
BA_ "NmNetworkRequest" SG_ 277 TBT_Side_Street 1;
BA_ "TimeoutValue" SG_ 277 TBT_Side_Street "Old value";
BA_ "Platform" SG_ 277 TBT_Direction "";
BA_ "GenSigSendType" SG_ 277 TBT_Direction 4;
BA_ "GenSigStartValue" SG_ 277 TBT_Direction 255;
BA_ "NmNetworkRequest" SG_ 277 TBT_Direction 1;
BA_ "TimeoutValue" SG_ 277 TBT_Direction "Old value";
BA_ "Platform" SG_ 277 TBT_Distance_Turn_Point "";
BA_ "GenSigSendType" SG_ 277 TBT_Distance_Turn_Point 4;
BA_ "GenSigStartValue" SG_ 277 TBT_Distance_Turn_Point 65535;
BA_ "NmNetworkRequest" SG_ 277 TBT_Distance_Turn_Point 1;
BA_ "TimeoutValue" SG_ 277 TBT_Distance_Turn_Point "Old value";
BA_ "Platform" SG_ 277 TBT_Combined_Side_Street "";
BA_ "GenSigSendType" SG_ 277 TBT_Combined_Side_Street 4;
BA_ "GenSigStartValue" SG_ 277 TBT_Combined_Side_Street 15;
BA_ "NmNetworkRequest" SG_ 277 TBT_Combined_Side_Street 1;
BA_ "TimeoutValue" SG_ 277 TBT_Combined_Side_Street "Old value";
BA_ "Platform" SG_ 277 TBT_Scale "";
BA_ "GenSigSendType" SG_ 277 TBT_Scale 4;
BA_ "GenSigStartValue" SG_ 277 TBT_Scale 15;
BA_ "NmNetworkRequest" SG_ 277 TBT_Scale 1;
BA_ "TimeoutValue" SG_ 277 TBT_Scale "Old value";
BA_ "Platform" SG_ 277 TBT_DistancetoTurnPoint "";
BA_ "GenSigSendType" SG_ 277 TBT_DistancetoTurnPoint 4;
BA_ "GenSigStartValue" SG_ 277 TBT_DistancetoTurnPoint 15;
BA_ "NmNetworkRequest" SG_ 277 TBT_DistancetoTurnPoint 1;
BA_ "TimeoutValue" SG_ 277 TBT_DistancetoTurnPoint "Old value";
BA_ "GenMsgSendType" BO_ 406 0;
BA_ "GenMsgCycleTime" BO_ 406 200;
BA_ "GenMsgCycleTimeFast" BO_ 406 40;
BA_ "GenMsgNrOfRepetition" BO_ 406 3;
BA_ "GenMsgStartDelayTime" BO_ 406 180;
BA_ "Platform" SG_ 406 HD_SPS_ChannelNo "";
BA_ "GenSigSendType" SG_ 406 HD_SPS_ChannelNo 4;
BA_ "GenSigStartValue" SG_ 406 HD_SPS_ChannelNo 15;
BA_ "NmNetworkRequest" SG_ 406 HD_SPS_ChannelNo 1;
BA_ "Platform" SG_ 406 SXM_ChannelNo "";
BA_ "GenSigSendType" SG_ 406 SXM_ChannelNo 4;
BA_ "GenSigStartValue" SG_ 406 SXM_ChannelNo 1023;
BA_ "NmNetworkRequest" SG_ 406 SXM_ChannelNo 1;
BA_ "TimeoutValue" SG_ 406 SXM_ChannelNo "Old Value";
BA_ "GenMsgSendType" BO_ 407 0;
BA_ "GenMsgCycleTime" BO_ 407 1000;
BA_ "GenMsgCycleTimeFast" BO_ 407 40;
BA_ "GenMsgNrOfRepetition" BO_ 407 3;
BA_ "GenMsgStartDelayTime" BO_ 407 560;
BA_REL_ "GenSigTimeoutTime" BU_SG_REL_ CGW SG_ 407 HU_LanguageInfo 3500;
BA_REL_ "GenSigTimeoutTime" BU_SG_REL_ CLU SG_ 407 HU_LanguageInfo 3500;
BA_ "SigDescription" SG_ 407 HU_LanguageInfo "Hungarian (0x1C) ¼öÁ¤ (For AE)";
BA_ "Platform" SG_ 407 HU_LanguageInfo "";
BA_ "GenSigSendType" SG_ 407 HU_LanguageInfo 4;
BA_ "GenSigStartValue" SG_ 407 HU_LanguageInfo 255;
BA_ "NmNetworkRequest" SG_ 407 HU_LanguageInfo 1;
BA_ "TimeoutValue" SG_ 407 HU_LanguageInfo "Old Value";
BA_REL_ "GenSigTimeoutTime" BU_SG_REL_ CLU SG_ 407 HU_MuteStatus 3500;
BA_ "Platform" SG_ 407 HU_MuteStatus "";
BA_ "GenSigSendType" SG_ 407 HU_MuteStatus 4;
BA_ "GenSigStartValue" SG_ 407 HU_MuteStatus 3;
BA_ "NmNetworkRequest" SG_ 407 HU_MuteStatus 1;
BA_ "TimeoutValue" SG_ 407 HU_MuteStatus "Old Value";
BA_REL_ "GenSigTimeoutTime" BU_SG_REL_ CLU SG_ 407 HU_VolumeStatus 3500;
BA_ "Platform" SG_ 407 HU_VolumeStatus "";
BA_ "GenSigSendType" SG_ 407 HU_VolumeStatus 4;
BA_ "GenSigStartValue" SG_ 407 HU_VolumeStatus 63;
BA_ "NmNetworkRequest" SG_ 407 HU_VolumeStatus 1;
BA_ "TimeoutValue" SG_ 407 HU_VolumeStatus "Old Value";
BA_REL_ "GenSigTimeoutTime" BU_SG_REL_ CLU SG_ 407 HU_NaviDisp 3500;
BA_ "Platform" SG_ 407 HU_NaviDisp "";
BA_ "GenSigSendType" SG_ 407 HU_NaviDisp 4;
BA_ "GenSigStartValue" SG_ 407 HU_NaviDisp 3;
BA_ "NmNetworkRequest" SG_ 407 HU_NaviDisp 1;
BA_ "TimeoutValue" SG_ 407 HU_NaviDisp "Old Value";
BA_REL_ "GenSigTimeoutTime" BU_SG_REL_ CGW SG_ 407 HU_NaviStatus 3500;
BA_REL_ "GenSigTimeoutTime" BU_SG_REL_ CLU SG_ 407 HU_NaviStatus 3500;
BA_ "Platform" SG_ 407 HU_NaviStatus "";
BA_ "GenSigSendType" SG_ 407 HU_NaviStatus 4;
BA_ "GenSigStartValue" SG_ 407 HU_NaviStatus 3;
BA_ "Gatewaysignal" SG_ 407 HU_NaviStatus 5;
BA_ "NmNetworkRequest" SG_ 407 HU_NaviStatus 1;
BA_ "TimeoutValue" SG_ 407 HU_NaviStatus "Old Value";
BA_REL_ "GenSigTimeoutTime" BU_SG_REL_ CLU SG_ 407 HU_UsmSupport 3500;
BA_ "Platform" SG_ 407 HU_UsmSupport "";
BA_ "GenSigSendType" SG_ 407 HU_UsmSupport 3;
BA_ "GenSigStartValue" SG_ 407 HU_UsmSupport 3;
BA_ "TimeoutValue" SG_ 407 HU_UsmSupport "Old value";
BA_REL_ "GenSigTimeoutTime" BU_SG_REL_ CGW SG_ 407 HU_NaviCamSettingStatus 3500;
BA_REL_ "GenSigTimeoutTime" BU_SG_REL_ CLU SG_ 407 HU_NaviCamSettingStatus 3500;
BA_ "Platform" SG_ 407 HU_NaviCamSettingStatus "";
BA_ "GenSigSendType" SG_ 407 HU_NaviCamSettingStatus 4;
BA_ "GenSigStartValue" SG_ 407 HU_NaviCamSettingStatus 255;
BA_ "Gatewaysignal" SG_ 407 HU_NaviCamSettingStatus 3;
BA_ "NmNetworkRequest" SG_ 407 HU_NaviCamSettingStatus 1;
BA_ "TimeoutValue" SG_ 407 HU_NaviCamSettingStatus "Old Value";
BA_ "GenMsgSendType" BO_ 290 0;
BA_ "GenMsgCycleTime" BO_ 290 200;
BA_ "GenMsgCycleTimeFast" BO_ 290 40;
BA_ "GenMsgNrOfRepetition" BO_ 290 3;
BA_ "GenMsgStartDelayTime" BO_ 290 180;
BA_REL_ "GenSigTimeoutTime" BU_SG_REL_ AMP SG_ 290 HU_OpState_New 2000;
BA_REL_ "GenSigTimeoutTime" BU_SG_REL_ CLU SG_ 290 HU_OpState_New 2000;
BA_ "Platform" SG_ 290 HU_OpState_New "";
BA_ "GenSigSendType" SG_ 290 HU_OpState_New 4;
BA_ "GenSigStartValue" SG_ 290 HU_OpState_New 127;
BA_ "NmNetworkRequest" SG_ 290 HU_OpState_New 1;
BA_ "TimeoutValue" SG_ 290 HU_OpState_New "0x7F";
BA_ "Platform" SG_ 290 HU_Frequency_Unit "";
BA_ "GenSigSendType" SG_ 290 HU_Frequency_Unit 3;
BA_ "GenSigStartValue" SG_ 290 HU_Frequency_Unit 3;
BA_ "Platform" SG_ 290 HU_User_Input "Compact AVN,D-Audio,Economic Audio 3.0,Integrated AVN1.0 High,Integrated AVN1.0 Mid,Premium AVN 2.0,Standard AVN 4.0,Standard Audio 3.0,Standard Audio 4.0";
BA_ "GenSigSendType" SG_ 290 HU_User_Input 3;
BA_ "TimeoutValue" SG_ 290 HU_User_Input "Invalid";
BA_REL_ "GenSigTimeoutTime" BU_SG_REL_ AMP SG_ 290 HU_FMFrequency_Offset_Type 2000;
BA_REL_ "GenSigTimeoutTime" BU_SG_REL_ CLU SG_ 290 HU_FMFrequency_Offset_Type 2000;
BA_ "SigDescription" SG_ 290 HU_FMFrequency_Offset_Type "Case 1) Offset Type==1(8750) : 'HU_Frequency_New' signal offset value is 8750

Case 2) Offset Type==2(6000) : 'HU_Frequency_New' signal offset value is 6000
 - In case FM frequency minimum value is less than 8750, offset type 2 is applied. (Brazil, Japan, etc...)";
BA_ "Platform" SG_ 290 HU_FMFrequency_Offset_Type "D-Audio,Integrated AVN1.0 High,Integrated AVN1.0 Mid,Premium AVN 2.0,Standard Audio 4.0";
BA_ "GenSigSendType" SG_ 290 HU_FMFrequency_Offset_Type 3;
BA_ "TimeoutValue" SG_ 290 HU_FMFrequency_Offset_Type "Invalid";
BA_ "Platform" SG_ 290 FM_Decimal_Point "";
BA_ "GenSigSendType" SG_ 290 FM_Decimal_Point 4;
BA_ "GenSigStartValue" SG_ 290 FM_Decimal_Point 3;
BA_ "NmNetworkRequest" SG_ 290 FM_Decimal_Point 1;
BA_ "TimeoutValue" SG_ 290 FM_Decimal_Point "0x3";
BA_ "Platform" SG_ 290 HU_Track_Number_New "";
BA_ "GenSigSendType" SG_ 290 HU_Track_Number_New 4;
BA_ "GenSigStartValue" SG_ 290 HU_Track_Number_New 65535;
BA_ "NmNetworkRequest" SG_ 290 HU_Track_Number_New 1;
BA_ "TimeoutValue" SG_ 290 HU_Track_Number_New "0xFFFF";
BA_ "Platform" SG_ 290 HU_Play_time_Sec_New "";
BA_ "GenSigSendType" SG_ 290 HU_Play_time_Sec_New 4;
BA_ "GenSigStartValue" SG_ 290 HU_Play_time_Sec_New 63;
BA_ "NmNetworkRequest" SG_ 290 HU_Play_time_Sec_New 1;
BA_ "TimeoutValue" SG_ 290 HU_Play_time_Sec_New "0x3F";
BA_ "Platform" SG_ 290 HU_Play_time_Min_New "";
BA_ "GenSigSendType" SG_ 290 HU_Play_time_Min_New 4;
BA_ "GenSigStartValue" SG_ 290 HU_Play_time_Min_New 63;
BA_ "NmNetworkRequest" SG_ 290 HU_Play_time_Min_New 1;
BA_ "TimeoutValue" SG_ 290 HU_Play_time_Min_New "0x3F";
BA_ "Platform" SG_ 290 HU_Play_time_Hour_New "";
BA_ "GenSigSendType" SG_ 290 HU_Play_time_Hour_New 4;
BA_ "GenSigStartValue" SG_ 290 HU_Play_time_Hour_New 127;
BA_ "NmNetworkRequest" SG_ 290 HU_Play_time_Hour_New 1;
BA_ "TimeoutValue" SG_ 290 HU_Play_time_Hour_New "0x7F";
BA_REL_ "GenSigTimeoutTime" BU_SG_REL_ AMP SG_ 290 HU_Frequency_New 2000;
BA_REL_ "GenSigTimeoutTime" BU_SG_REL_ CLU SG_ 290 HU_Frequency_New 2000;
BA_ "SigDescription" SG_ 290 HU_Frequency_New "AM : Frequency = Signal value (ignore Decimal_Point value)
FM : Frequency = (Signal value (in decimal) + Offset Type) / 100
Case 1) 'HU_FMFrequency_Offset_Type'==8750 (Hex==0x0)
            : 'HU_Frequency_New' signal offset value is 8750
Case 2) 'HU_FMFrequency_Offset_Type'==6000 (Hex==0x1)
            : 'HU_Frequency_New' signal offset value is 6000";
BA_ "Platform" SG_ 290 HU_Frequency_New "D-Audio,Integrated AVN1.0 High,Integrated AVN1.0 Mid,Premium AVN 2.0,Standard Audio 4.0";
BA_ "GenSigSendType" SG_ 290 HU_Frequency_New 4;
BA_ "GenSigStartValue" SG_ 290 HU_Frequency_New 8191;
BA_ "NmNetworkRequest" SG_ 290 HU_Frequency_New 1;
BA_ "TimeoutValue" SG_ 290 HU_Frequency_New "0x1FFF";
BA_ "GenMsgSendType" BO_ 291 0;
BA_ "GenMsgCycleTime" BO_ 291 200;
BA_ "GenMsgCycleTimeFast" BO_ 291 40;
BA_ "GenMsgNrOfRepetition" BO_ 291 3;
BA_ "GenMsgStartDelayTime" BO_ 291 170;
BA_ "Platform" SG_ 291 NV_Display_TG "";
BA_ "GenSigSendType" SG_ 291 NV_Display_TG 4;
BA_ "GenSigStartValue" SG_ 291 NV_Display_TG 3;
BA_ "NmNetworkRequest" SG_ 291 NV_Display_TG 1;
BA_REL_ "GenSigTimeoutTime" BU_SG_REL_ CLU SG_ 291 TBT_BarGraph100Level 750;
BA_ "Platform" SG_ 291 TBT_BarGraph100Level "";
BA_ "GenSigSendType" SG_ 291 TBT_BarGraph100Level 3;
BA_ "GenSigStartValue" SG_ 291 TBT_BarGraph100Level 255;
BA_ "TimeoutValue" SG_ 291 TBT_BarGraph100Level "old vaule";
BA_ "Validity" SG_ 291 TBT_BarGraph100Level 2;
BA_ "GenMsgSendType" BO_ 286 0;
BA_ "GenMsgCycleTime" BO_ 286 200;
BA_ "GenMsgStartDelayTime" BO_ 286 190;
BA_ "Platform" SG_ 286 Navi_WarnDist_OverDec "Compact AVN,DIS 2,Integrated AVN1.0 High,Integrated AVN1.0 Mid,Premium AVN 2.0,Standard AVN 4.0";
BA_ "GenSigSendType" SG_ 286 Navi_WarnDist_OverDec 3;
BA_ "GenSigStartValue" SG_ 286 Navi_WarnDist_OverDec 65535;
BA_ "TimeoutValue" SG_ 286 Navi_WarnDist_OverDec "Old value";
BA_ "Platform" SG_ 286 Navi_WarnDist_UnderDec "Compact AVN,DIS 2,Integrated AVN1.0 High,Integrated AVN1.0 Mid,Premium AVN 2.0,Standard AVN 4.0";
BA_ "GenSigSendType" SG_ 286 Navi_WarnDist_UnderDec 3;
BA_ "GenSigStartValue" SG_ 286 Navi_WarnDist_UnderDec 15;
BA_ "TimeoutValue" SG_ 286 Navi_WarnDist_UnderDec "Old value";
BA_ "Platform" SG_ 286 Navi_WarnDist_Scale "Compact AVN,DIS 2,Integrated AVN1.0 High,Integrated AVN1.0 Mid,Premium AVN 2.0,Standard AVN 4.0";
BA_ "GenSigSendType" SG_ 286 Navi_WarnDist_Scale 3;
BA_ "GenSigStartValue" SG_ 286 Navi_WarnDist_Scale 15;
BA_ "TimeoutValue" SG_ 286 Navi_WarnDist_Scale "Old value";
BA_REL_ "GenSigTimeoutTime" BU_SG_REL_ CGW SG_ 56 C_DrvWindowOpenCmd 0;
BA_REL_ "GenSigTimeoutTime" BU_SG_REL_ CLU SG_ 56 C_DrvWindowOpenCmd 0;
BA_ "Platform" SG_ 56 C_DrvWindowOpenCmd "";
BA_ "GenSigSendType" SG_ 56 C_DrvWindowOpenCmd 3;
BA_ "GenSigStartValue" SG_ 56 C_DrvWindowOpenCmd 3;
BA_REL_ "GenSigTimeoutTime" BU_SG_REL_ CGW SG_ 56 C_AstWindowCmdAVN 0;
BA_REL_ "GenSigTimeoutTime" BU_SG_REL_ CLU SG_ 56 C_AstWindowCmdAVN 0;
BA_ "Platform" SG_ 56 C_AstWindowCmdAVN "";
BA_ "GenSigSendType" SG_ 56 C_AstWindowCmdAVN 3;
BA_ "GenSigStartValue" SG_ 56 C_AstWindowCmdAVN 3;
BA_REL_ "GenSigTimeoutTime" BU_SG_REL_ CGW SG_ 56 C_RLWindowCmdAVN 0;
BA_REL_ "GenSigTimeoutTime" BU_SG_REL_ CLU SG_ 56 C_RLWindowCmdAVN 0;
BA_ "Platform" SG_ 56 C_RLWindowCmdAVN "";
BA_ "GenSigSendType" SG_ 56 C_RLWindowCmdAVN 3;
BA_ "GenSigStartValue" SG_ 56 C_RLWindowCmdAVN 3;
BA_REL_ "GenSigTimeoutTime" BU_SG_REL_ CGW SG_ 56 C_RRWindowCmdAVN 0;
BA_REL_ "GenSigTimeoutTime" BU_SG_REL_ CLU SG_ 56 C_RRWindowCmdAVN 0;
BA_ "Platform" SG_ 56 C_RRWindowCmdAVN "";
BA_ "GenSigSendType" SG_ 56 C_RRWindowCmdAVN 3;
BA_ "GenSigStartValue" SG_ 56 C_RRWindowCmdAVN 3;
BA_REL_ "GenSigTimeoutTime" BU_SG_REL_ CGW SG_ 56 C_RrDefoggerCmdAVN 0;
BA_REL_ "GenSigTimeoutTime" BU_SG_REL_ CLU SG_ 56 C_RrDefoggerCmdAVN 0;
BA_ "Platform" SG_ 56 C_RrDefoggerCmdAVN "";
BA_ "GenSigSendType" SG_ 56 C_RrDefoggerCmdAVN 3;
BA_ "GenSigStartValue" SG_ 56 C_RrDefoggerCmdAVN 3;
BA_ "Validity" SG_ 56 C_RrDefoggerCmdAVN 2;
BA_REL_ "GenSigTimeoutTime" BU_SG_REL_ CGW SG_ 56 C_StrgWhlHeatedCmdAVN 0;
BA_REL_ "GenSigTimeoutTime" BU_SG_REL_ CLU SG_ 56 C_StrgWhlHeatedCmdAVN 0;
BA_ "Platform" SG_ 56 C_StrgWhlHeatedCmdAVN "";
BA_ "GenSigSendType" SG_ 56 C_StrgWhlHeatedCmdAVN 3;
BA_ "GenSigStartValue" SG_ 56 C_StrgWhlHeatedCmdAVN 3;
BA_ "Validity" SG_ 56 C_StrgWhlHeatedCmdAVN 3;
BA_REL_ "GenSigTimeoutTime" BU_SG_REL_ CGW SG_ 56 C_TrunkTlgtCmdAVN 0;
BA_REL_ "GenSigTimeoutTime" BU_SG_REL_ CLU SG_ 56 C_TrunkTlgtCmdAVN 0;
BA_ "Platform" SG_ 56 C_TrunkTlgtCmdAVN "";
BA_ "GenSigSendType" SG_ 56 C_TrunkTlgtCmdAVN 3;
BA_ "GenSigStartValue" SG_ 56 C_TrunkTlgtCmdAVN 3;
BA_ "Validity" SG_ 56 C_TrunkTlgtCmdAVN 2;
BA_REL_ "GenSigTimeoutTime" BU_SG_REL_ CGW SG_ 56 C_PTGCNTLCmdAVN 0;
BA_REL_ "GenSigTimeoutTime" BU_SG_REL_ CLU SG_ 56 C_PTGCNTLCmdAVN 0;
BA_ "Platform" SG_ 56 C_PTGCNTLCmdAVN "";
BA_ "GenSigSendType" SG_ 56 C_PTGCNTLCmdAVN 3;
BA_ "GenSigStartValue" SG_ 56 C_PTGCNTLCmdAVN 3;
BA_ "Validity" SG_ 56 C_PTGCNTLCmdAVN 2;
BA_REL_ "GenSigTimeoutTime" BU_SG_REL_ CGW SG_ 56 C_AVNIMSButtonCmd 0;
BA_REL_ "GenSigTimeoutTime" BU_SG_REL_ CLU SG_ 56 C_AVNIMSButtonCmd 0;
BA_ "Platform" SG_ 56 C_AVNIMSButtonCmd "";
BA_ "GenSigSendType" SG_ 56 C_AVNIMSButtonCmd 3;
BA_ "GenSigStartValue" SG_ 56 C_AVNIMSButtonCmd 7;
BA_REL_ "GenSigTimeoutTime" BU_SG_REL_ CGW SG_ 52 HU_DATC_DrTempUpDn 0;
BA_REL_ "GenSigTimeoutTime" BU_SG_REL_ CLU SG_ 52 HU_DATC_DrTempUpDn 0;
BA_ "Platform" SG_ 52 HU_DATC_DrTempUpDn "";
BA_ "GenSigSendType" SG_ 52 HU_DATC_DrTempUpDn 3;
BA_ "GenSigStartValue" SG_ 52 HU_DATC_DrTempUpDn 3;
BA_ "Gatewaysignal" SG_ 52 HU_DATC_DrTempUpDn 3;
BA_ "Validity" SG_ 52 HU_DATC_DrTempUpDn 2;
BA_REL_ "GenSigTimeoutTime" BU_SG_REL_ CGW SG_ 52 HU_DATC_MainBlower 0;
BA_REL_ "GenSigTimeoutTime" BU_SG_REL_ CLU SG_ 52 HU_DATC_MainBlower 0;
BA_ "Platform" SG_ 52 HU_DATC_MainBlower "";
BA_ "GenSigSendType" SG_ 52 HU_DATC_MainBlower 3;
BA_ "GenSigStartValue" SG_ 52 HU_DATC_MainBlower 15;
BA_ "Gatewaysignal" SG_ 52 HU_DATC_MainBlower 3;
BA_ "Validity" SG_ 52 HU_DATC_MainBlower 2;
BA_REL_ "GenSigTimeoutTime" BU_SG_REL_ CGW SG_ 52 HU_DATC_FrontModeSet 0;
BA_REL_ "GenSigTimeoutTime" BU_SG_REL_ CLU SG_ 52 HU_DATC_FrontModeSet 0;
BA_ "Platform" SG_ 52 HU_DATC_FrontModeSet "";
BA_ "GenSigSendType" SG_ 52 HU_DATC_FrontModeSet 3;
BA_ "GenSigStartValue" SG_ 52 HU_DATC_FrontModeSet 15;
BA_ "Gatewaysignal" SG_ 52 HU_DATC_FrontModeSet 3;
BA_ "Validity" SG_ 52 HU_DATC_FrontModeSet 2;
BA_REL_ "GenSigTimeoutTime" BU_SG_REL_ CGW SG_ 52 HU_DATC_AutoSet 0;
BA_REL_ "GenSigTimeoutTime" BU_SG_REL_ CLU SG_ 52 HU_DATC_AutoSet 0;
BA_ "Platform" SG_ 52 HU_DATC_AutoSet "";
BA_ "GenSigSendType" SG_ 52 HU_DATC_AutoSet 3;
BA_ "GenSigStartValue" SG_ 52 HU_DATC_AutoSet 3;
BA_ "Gatewaysignal" SG_ 52 HU_DATC_AutoSet 3;
BA_ "Validity" SG_ 52 HU_DATC_AutoSet 2;
BA_REL_ "GenSigTimeoutTime" BU_SG_REL_ CGW SG_ 52 HU_DATC_IntakeSet 0;
BA_REL_ "GenSigTimeoutTime" BU_SG_REL_ CLU SG_ 52 HU_DATC_IntakeSet 0;
BA_ "Platform" SG_ 52 HU_DATC_IntakeSet "";
BA_ "GenSigSendType" SG_ 52 HU_DATC_IntakeSet 3;
BA_ "GenSigStartValue" SG_ 52 HU_DATC_IntakeSet 3;
BA_ "Gatewaysignal" SG_ 52 HU_DATC_IntakeSet 3;
BA_ "Validity" SG_ 52 HU_DATC_IntakeSet 2;
BA_REL_ "GenSigTimeoutTime" BU_SG_REL_ CGW SG_ 52 HU_DATC_AcSet 0;
BA_REL_ "GenSigTimeoutTime" BU_SG_REL_ CLU SG_ 52 HU_DATC_AcSet 0;
BA_ "Platform" SG_ 52 HU_DATC_AcSet "";
BA_ "GenSigSendType" SG_ 52 HU_DATC_AcSet 3;
BA_ "GenSigStartValue" SG_ 52 HU_DATC_AcSet 3;
BA_ "Gatewaysignal" SG_ 52 HU_DATC_AcSet 3;
BA_ "Validity" SG_ 52 HU_DATC_AcSet 2;
BA_REL_ "GenSigTimeoutTime" BU_SG_REL_ CGW SG_ 52 HU_DATC_FrontDefog 0;
BA_REL_ "GenSigTimeoutTime" BU_SG_REL_ CLU SG_ 52 HU_DATC_FrontDefog 0;
BA_ "Platform" SG_ 52 HU_DATC_FrontDefog "";
BA_ "GenSigSendType" SG_ 52 HU_DATC_FrontDefog 3;
BA_ "GenSigStartValue" SG_ 52 HU_DATC_FrontDefog 3;
BA_ "Gatewaysignal" SG_ 52 HU_DATC_FrontDefog 3;
BA_ "Validity" SG_ 52 HU_DATC_FrontDefog 2;
BA_ "GenMsgNrOfRepetition" BO_ 52 3;
BA_ "GenMsgCycleTimeFast" BO_ 52 40;
BA_REL_ "GenSigTimeoutTime" BU_SG_REL_ CGW SG_ 52 DATC_ADSOnOffSet 0;
BA_REL_ "GenSigTimeoutTime" BU_SG_REL_ CLU SG_ 52 DATC_ADSOnOffSet 0;
BA_ "Platform" SG_ 52 DATC_ADSOnOffSet "";
BA_ "GenSigSendType" SG_ 52 DATC_ADSOnOffSet 4;
BA_ "GenSigStartValue" SG_ 52 DATC_ADSOnOffSet 3;
BA_ "Gatewaysignal" SG_ 52 DATC_ADSOnOffSet 3;
BA_ "NmNetworkRequest" SG_ 52 DATC_ADSOnOffSet 1;
BA_ "Validity" SG_ 52 DATC_ADSOnOffSet 2;
BA_REL_ "GenSigTimeoutTime" BU_SG_REL_ CGW SG_ 52 HU_DATC_MainBlowerUpDn 0;
BA_REL_ "GenSigTimeoutTime" BU_SG_REL_ CLU SG_ 52 HU_DATC_MainBlowerUpDn 0;
BA_ "Platform" SG_ 52 HU_DATC_MainBlowerUpDn "";
BA_ "GenSigSendType" SG_ 52 HU_DATC_MainBlowerUpDn 3;
BA_ "GenSigStartValue" SG_ 52 HU_DATC_MainBlowerUpDn 3;
BA_ "Validity" SG_ 52 HU_DATC_MainBlowerUpDn 2;
BA_REL_ "GenSigTimeoutTime" BU_SG_REL_ CGW SG_ 52 HU_DATC_AirCleaningSet 0;
BA_REL_ "GenSigTimeoutTime" BU_SG_REL_ CLU SG_ 52 HU_DATC_AirCleaningSet 0;
BA_ "Platform" SG_ 52 HU_DATC_AirCleaningSet "";
BA_ "GenSigSendType" SG_ 52 HU_DATC_AirCleaningSet 3;
BA_ "GenSigStartValue" SG_ 52 HU_DATC_AirCleaningSet 3;
BA_ "Validity" SG_ 52 HU_DATC_AirCleaningSet 2;
BA_REL_ "GenSigTimeoutTime" BU_SG_REL_ CGW SG_ 54 HU_DATC_DrTempSetC 0;
BA_REL_ "GenSigTimeoutTime" BU_SG_REL_ CLU SG_ 54 HU_DATC_DrTempSetC 0;
BA_ "Platform" SG_ 54 HU_DATC_DrTempSetC "";
BA_ "GenSigSendType" SG_ 54 HU_DATC_DrTempSetC 3;
BA_ "GenSigStartValue" SG_ 54 HU_DATC_DrTempSetC 255;
BA_ "Validity" SG_ 54 HU_DATC_DrTempSetC 2;
BA_REL_ "GenSigTimeoutTime" BU_SG_REL_ CGW SG_ 54 HU_DATC_DrTempSetF 0;
BA_REL_ "GenSigTimeoutTime" BU_SG_REL_ CLU SG_ 54 HU_DATC_DrTempSetF 0;
BA_ "Platform" SG_ 54 HU_DATC_DrTempSetF "";
BA_ "GenSigSendType" SG_ 54 HU_DATC_DrTempSetF 3;
BA_ "GenSigStartValue" SG_ 54 HU_DATC_DrTempSetF 255;
BA_ "Validity" SG_ 54 HU_DATC_DrTempSetF 2;
BA_ "GenMsgSendType" BO_ 256 0;
BA_ "GenMsgCycleTime" BO_ 256 2000;
BA_ "GenMsgCycleTimeFast" BO_ 256 40;
BA_ "GenMsgNrOfRepetition" BO_ 256 3;
BA_ "GenMsgStartDelayTime" BO_ 256 610;
BA_REL_ "GenSigTimeoutTime" BU_SG_REL_ AMP SG_ 256 HU_Type 3500;
BA_REL_ "GenSigTimeoutTime" BU_SG_REL_ CGW SG_ 256 HU_Type 3500;
BA_REL_ "GenSigTimeoutTime" BU_SG_REL_ CLU SG_ 256 HU_Type 3500;
BA_ "Platform" SG_ 256 HU_Type "Compact AVN,D-Audio,DIS 2,Economic Audio 3.0,Integrated AVN1.0 High,Integrated AVN1.0 Mid,Premium AVN 2.0,Standard AVN 4.0,Standard Audio 3.0,Standard Audio 4.0,UVO3 (D-Audio Kia)";
BA_ "GenSigSendType" SG_ 256 HU_Type 4;
BA_ "GenSigStartValue" SG_ 256 HU_Type 255;
BA_ "NmNetworkRequest" SG_ 256 HU_Type 1;
BA_ "TimeoutValue" SG_ 256 HU_Type "0xFF";
BA_REL_ "GenSigTimeoutTime" BU_SG_REL_ AMP SG_ 256 HU_DistributeInfo 3500;
BA_REL_ "GenSigTimeoutTime" BU_SG_REL_ CGW SG_ 256 HU_DistributeInfo 3500;
BA_REL_ "GenSigTimeoutTime" BU_SG_REL_ CLU SG_ 256 HU_DistributeInfo 3500;
BA_ "Platform" SG_ 256 HU_DistributeInfo "";
BA_ "GenSigSendType" SG_ 256 HU_DistributeInfo 4;
BA_ "GenSigStartValue" SG_ 256 HU_DistributeInfo 255;
BA_ "NmNetworkRequest" SG_ 256 HU_DistributeInfo 1;
BA_ "TimeoutValue" SG_ 256 HU_DistributeInfo "0xFF";
BA_REL_ "GenSigTimeoutTime" BU_SG_REL_ AMP SG_ 256 HU_OptionInfo 3500;
BA_REL_ "GenSigTimeoutTime" BU_SG_REL_ CGW SG_ 256 HU_OptionInfo 3500;
BA_REL_ "GenSigTimeoutTime" BU_SG_REL_ CLU SG_ 256 HU_OptionInfo 3500;
BA_ "SigDescription" SG_ 256 HU_OptionInfo "Bit0 : Navi (0: Not Support / 1: Support)
Bit1 : USM (0: Not Support / 1: Support)
Bit2 : TMS (0: Not Support / 1: Support)
Bit3 : Multi Profile (0: Not Support(No Profile or Single Profile)  / 1: Support)
Bit4 : Camera Guideline (0: Displayed by Camera / 1: Displayed by H/U)
Bit5~Bit14 : Reserved
Bit15 : 1 Invalid";
BA_ "Platform" SG_ 256 HU_OptionInfo "";
BA_ "GenSigSendType" SG_ 256 HU_OptionInfo 3;
BA_ "TimeoutValue" SG_ 256 HU_OptionInfo "0x8000";
BA_REL_ "GenSigTimeoutTime" BU_SG_REL_ CGW SG_ 256 HU_AdasSupport 3500;
BA_REL_ "GenSigTimeoutTime" BU_SG_REL_ CLU SG_ 256 HU_AdasSupport 3500;
BA_ "Platform" SG_ 256 HU_AdasSupport "";
BA_ "GenSigSendType" SG_ 256 HU_AdasSupport 4;
BA_ "GenSigStartValue" SG_ 256 HU_AdasSupport 7;
BA_ "Gatewaysignal" SG_ 256 HU_AdasSupport 3;
BA_ "NmNetworkRequest" SG_ 256 HU_AdasSupport 1;
BA_ "TimeoutValue" SG_ 256 HU_AdasSupport "Old Value";
BA_ "GenMsgCycleTimeFast" BO_ 206 40;
BA_ "GenMsgNrOfRepetition" BO_ 206 3;
BA_REL_ "GenSigTimeoutTime" BU_SG_REL_ CGW SG_ 206 META_MapProvider 0;
BA_REL_ "GenSigTimeoutTime" BU_SG_REL_ CLU SG_ 206 META_MapProvider 0;
BA_ "SigDescription" SG_ 206 META_MapProvider "[Default Value]
0x0";
BA_ "Platform" SG_ 206 META_MapProvider "";
BA_ "GenSigSendType" SG_ 206 META_MapProvider 4;
BA_ "GenSigStartValue" SG_ 206 META_MapProvider 7;
BA_ "NmNetworkRequest" SG_ 206 META_MapProvider 1;
BA_ "Validity" SG_ 206 META_MapProvider 2;
BA_REL_ "GenSigTimeoutTime" BU_SG_REL_ CGW SG_ 206 META_MessageType 0;
BA_REL_ "GenSigTimeoutTime" BU_SG_REL_ CLU SG_ 206 META_MessageType 0;
BA_ "SigDescription" SG_ 206 META_MessageType "[Default Value]
0x6";
BA_ "Platform" SG_ 206 META_MessageType "";
BA_ "GenSigSendType" SG_ 206 META_MessageType 4;
BA_ "GenSigStartValue" SG_ 206 META_MessageType 7;
BA_ "NmNetworkRequest" SG_ 206 META_MessageType 1;
BA_ "Validity" SG_ 206 META_MessageType 2;
BA_REL_ "GenSigTimeoutTime" BU_SG_REL_ CGW SG_ 206 META_CountryCode 0;
BA_REL_ "GenSigTimeoutTime" BU_SG_REL_ CLU SG_ 206 META_CountryCode 0;
BA_ "SigDescription" SG_ 206 META_CountryCode "[Default Value]
0x0";
BA_ "Platform" SG_ 206 META_CountryCode "";
BA_ "GenSigSendType" SG_ 206 META_CountryCode 4;
BA_ "GenSigStartValue" SG_ 206 META_CountryCode 1023;
BA_ "NmNetworkRequest" SG_ 206 META_CountryCode 1;
BA_ "Validity" SG_ 206 META_CountryCode 2;
BA_REL_ "GenSigTimeoutTime" BU_SG_REL_ CGW SG_ 206 META_MinorProtocolSubVer 0;
BA_REL_ "GenSigTimeoutTime" BU_SG_REL_ CLU SG_ 206 META_MinorProtocolSubVer 0;
BA_ "SigDescription" SG_ 206 META_MinorProtocolSubVer "[Default Value]
0x0";
BA_ "Platform" SG_ 206 META_MinorProtocolSubVer "";
BA_ "GenSigSendType" SG_ 206 META_MinorProtocolSubVer 4;
BA_ "NmNetworkRequest" SG_ 206 META_MinorProtocolSubVer 1;
BA_ "Validity" SG_ 206 META_MinorProtocolSubVer 2;
BA_REL_ "GenSigTimeoutTime" BU_SG_REL_ CGW SG_ 206 META_MajorProtocolVersion 0;
BA_REL_ "GenSigTimeoutTime" BU_SG_REL_ CLU SG_ 206 META_MajorProtocolVersion 0;
BA_ "SigDescription" SG_ 206 META_MajorProtocolVersion "[Default Value]
0x0";
BA_ "Platform" SG_ 206 META_MajorProtocolVersion "";
BA_ "GenSigSendType" SG_ 206 META_MajorProtocolVersion 4;
BA_ "NmNetworkRequest" SG_ 206 META_MajorProtocolVersion 1;
BA_ "Validity" SG_ 206 META_MajorProtocolVersion 2;
BA_REL_ "GenSigTimeoutTime" BU_SG_REL_ CGW SG_ 206 META_CyclicCounter 0;
BA_REL_ "GenSigTimeoutTime" BU_SG_REL_ CLU SG_ 206 META_CyclicCounter 0;
BA_ "SigDescription" SG_ 206 META_CyclicCounter "[Default Value]
0x0";
BA_ "Platform" SG_ 206 META_CyclicCounter "";
BA_ "GenSigSendType" SG_ 206 META_CyclicCounter 4;
BA_ "NmNetworkRequest" SG_ 206 META_CyclicCounter 1;
BA_ "Validity" SG_ 206 META_CyclicCounter 2;
BA_REL_ "GenSigTimeoutTime" BU_SG_REL_ CGW SG_ 206 META_HardwareVersion 0;
BA_REL_ "GenSigTimeoutTime" BU_SG_REL_ CLU SG_ 206 META_HardwareVersion 0;
BA_ "SigDescription" SG_ 206 META_HardwareVersion "[Default Value]
0x0";
BA_ "Platform" SG_ 206 META_HardwareVersion "";
BA_ "GenSigSendType" SG_ 206 META_HardwareVersion 4;
BA_ "GenSigStartValue" SG_ 206 META_HardwareVersion 511;
BA_ "NmNetworkRequest" SG_ 206 META_HardwareVersion 1;
BA_ "Validity" SG_ 206 META_HardwareVersion 2;
BA_REL_ "GenSigTimeoutTime" BU_SG_REL_ CGW SG_ 206 META_DrivingSide 0;
BA_REL_ "GenSigTimeoutTime" BU_SG_REL_ CLU SG_ 206 META_DrivingSide 0;
BA_ "SigDescription" SG_ 206 META_DrivingSide "[Default Value]
0x0";
BA_ "Platform" SG_ 206 META_DrivingSide "";
BA_ "GenSigSendType" SG_ 206 META_DrivingSide 4;
BA_ "NmNetworkRequest" SG_ 206 META_DrivingSide 1;
BA_ "Validity" SG_ 206 META_DrivingSide 2;
BA_REL_ "GenSigTimeoutTime" BU_SG_REL_ CGW SG_ 206 META_RegionCode 0;
BA_REL_ "GenSigTimeoutTime" BU_SG_REL_ CLU SG_ 206 META_RegionCode 0;
BA_ "SigDescription" SG_ 206 META_RegionCode "[Default Value]
0x7FFF";
BA_ "Platform" SG_ 206 META_RegionCode "";
BA_ "GenSigSendType" SG_ 206 META_RegionCode 4;
BA_ "GenSigStartValue" SG_ 206 META_RegionCode 32767;
BA_ "NmNetworkRequest" SG_ 206 META_RegionCode 1;
BA_ "Validity" SG_ 206 META_RegionCode 2;
BA_REL_ "GenSigTimeoutTime" BU_SG_REL_ CGW SG_ 206 META_MapVersionYear 0;
BA_REL_ "GenSigTimeoutTime" BU_SG_REL_ CLU SG_ 206 META_MapVersionYear 0;
BA_ "SigDescription" SG_ 206 META_MapVersionYear "[Default Value]
0x3F";
BA_ "Platform" SG_ 206 META_MapVersionYear "";
BA_ "GenSigSendType" SG_ 206 META_MapVersionYear 4;
BA_ "GenSigStartValue" SG_ 206 META_MapVersionYear 63;
BA_ "NmNetworkRequest" SG_ 206 META_MapVersionYear 1;
BA_ "Validity" SG_ 206 META_MapVersionYear 2;
BA_REL_ "GenSigTimeoutTime" BU_SG_REL_ CGW SG_ 206 META_MapVersionQuarter 0;
BA_REL_ "GenSigTimeoutTime" BU_SG_REL_ CLU SG_ 206 META_MapVersionQuarter 0;
BA_ "SigDescription" SG_ 206 META_MapVersionQuarter "[Default Value]
0x0";
BA_ "Platform" SG_ 206 META_MapVersionQuarter "";
BA_ "GenSigSendType" SG_ 206 META_MapVersionQuarter 4;
BA_ "NmNetworkRequest" SG_ 206 META_MapVersionQuarter 1;
BA_ "Validity" SG_ 206 META_MapVersionQuarter 2;
BA_REL_ "GenSigTimeoutTime" BU_SG_REL_ CGW SG_ 206 META_MinorProtocolVersion 0;
BA_REL_ "GenSigTimeoutTime" BU_SG_REL_ CLU SG_ 206 META_MinorProtocolVersion 0;
BA_ "SigDescription" SG_ 206 META_MinorProtocolVersion "[Default Value]
0x0";
BA_ "Platform" SG_ 206 META_MinorProtocolVersion "";
BA_ "GenSigSendType" SG_ 206 META_MinorProtocolVersion 4;
BA_ "NmNetworkRequest" SG_ 206 META_MinorProtocolVersion 1;
BA_ "Validity" SG_ 206 META_MinorProtocolVersion 2;
BA_REL_ "GenSigTimeoutTime" BU_SG_REL_ CGW SG_ 206 META_SpeedUnit 0;
BA_REL_ "GenSigTimeoutTime" BU_SG_REL_ CLU SG_ 206 META_SpeedUnit 0;
BA_ "SigDescription" SG_ 206 META_SpeedUnit "[Default Value]
0x0";
BA_ "Platform" SG_ 206 META_SpeedUnit "";
BA_ "GenSigSendType" SG_ 206 META_SpeedUnit 4;
BA_ "NmNetworkRequest" SG_ 206 META_SpeedUnit 1;
BA_ "Validity" SG_ 206 META_SpeedUnit 2;
BA_ "GenMsgCycleTimeFast" BO_ 205 40;
BA_ "GenMsgNrOfRepetition" BO_ 205 3;
BA_REL_ "GenSigTimeoutTime" BU_SG_REL_ CGW SG_ 205 PROLONG_Value 0;
BA_REL_ "GenSigTimeoutTime" BU_SG_REL_ CLU SG_ 205 PROLONG_Value 0;
BA_ "SigDescription" SG_ 205 PROLONG_Value "[Default Value]
0xFFFFFFFF";
BA_ "Platform" SG_ 205 PROLONG_Value "";
BA_ "GenSigSendType" SG_ 205 PROLONG_Value 4;
BA_ "NmNetworkRequest" SG_ 205 PROLONG_Value 1;
BA_ "Validity" SG_ 205 PROLONG_Value 2;
BA_REL_ "GenSigTimeoutTime" BU_SG_REL_ CGW SG_ 205 PROLONG_MessageType 0;
BA_REL_ "GenSigTimeoutTime" BU_SG_REL_ CLU SG_ 205 PROLONG_MessageType 0;
BA_ "SigDescription" SG_ 205 PROLONG_MessageType "[Default Value]
0x5";
BA_ "Platform" SG_ 205 PROLONG_MessageType "";
BA_ "GenSigSendType" SG_ 205 PROLONG_MessageType 4;
BA_ "GenSigStartValue" SG_ 205 PROLONG_MessageType 7;
BA_ "NmNetworkRequest" SG_ 205 PROLONG_MessageType 1;
BA_ "Validity" SG_ 205 PROLONG_MessageType 2;
BA_REL_ "GenSigTimeoutTime" BU_SG_REL_ CGW SG_ 205 PROLONG_Offset 0;
BA_REL_ "GenSigTimeoutTime" BU_SG_REL_ CLU SG_ 205 PROLONG_Offset 0;
BA_ "SigDescription" SG_ 205 PROLONG_Offset "[Default Value]
0x1FFF";
BA_ "Platform" SG_ 205 PROLONG_Offset "";
BA_ "GenSigSendType" SG_ 205 PROLONG_Offset 4;
BA_ "GenSigStartValue" SG_ 205 PROLONG_Offset 8191;
BA_ "NmNetworkRequest" SG_ 205 PROLONG_Offset 1;
BA_ "Validity" SG_ 205 PROLONG_Offset 2;
BA_REL_ "GenSigTimeoutTime" BU_SG_REL_ CGW SG_ 205 PROLONG_PathIndex 0;
BA_REL_ "GenSigTimeoutTime" BU_SG_REL_ CLU SG_ 205 PROLONG_PathIndex 0;
BA_ "SigDescription" SG_ 205 PROLONG_PathIndex "[Default Value]
0x0";
BA_ "Platform" SG_ 205 PROLONG_PathIndex "";
BA_ "GenSigSendType" SG_ 205 PROLONG_PathIndex 4;
BA_ "NmNetworkRequest" SG_ 205 PROLONG_PathIndex 1;
BA_ "Validity" SG_ 205 PROLONG_PathIndex 2;
BA_REL_ "GenSigTimeoutTime" BU_SG_REL_ CGW SG_ 205 PROLONG_CyclicCounter 0;
BA_REL_ "GenSigTimeoutTime" BU_SG_REL_ CLU SG_ 205 PROLONG_CyclicCounter 0;
BA_ "SigDescription" SG_ 205 PROLONG_CyclicCounter "[Default Value]
0x0";
BA_ "Platform" SG_ 205 PROLONG_CyclicCounter "";
BA_ "GenSigSendType" SG_ 205 PROLONG_CyclicCounter 4;
BA_ "NmNetworkRequest" SG_ 205 PROLONG_CyclicCounter 1;
BA_ "Validity" SG_ 205 PROLONG_CyclicCounter 2;
BA_REL_ "GenSigTimeoutTime" BU_SG_REL_ CGW SG_ 205 PROLONG_Update 0;
BA_REL_ "GenSigTimeoutTime" BU_SG_REL_ CLU SG_ 205 PROLONG_Update 0;
BA_ "SigDescription" SG_ 205 PROLONG_Update "[Default Value]
0x0";
BA_ "Platform" SG_ 205 PROLONG_Update "";
BA_ "GenSigSendType" SG_ 205 PROLONG_Update 4;
BA_ "NmNetworkRequest" SG_ 205 PROLONG_Update 1;
BA_ "Validity" SG_ 205 PROLONG_Update 2;
BA_REL_ "GenSigTimeoutTime" BU_SG_REL_ CGW SG_ 205 PROLONG_Retransmission 0;
BA_REL_ "GenSigTimeoutTime" BU_SG_REL_ CLU SG_ 205 PROLONG_Retransmission 0;
BA_ "SigDescription" SG_ 205 PROLONG_Retransmission "[Default Vaule]
0x0";
BA_ "Platform" SG_ 205 PROLONG_Retransmission "";
BA_ "GenSigSendType" SG_ 205 PROLONG_Retransmission 4;
BA_ "NmNetworkRequest" SG_ 205 PROLONG_Retransmission 1;
BA_ "Validity" SG_ 205 PROLONG_Retransmission 2;
BA_REL_ "GenSigTimeoutTime" BU_SG_REL_ CGW SG_ 205 PROLONG_CountrolPoint 0;
BA_REL_ "GenSigTimeoutTime" BU_SG_REL_ CLU SG_ 205 PROLONG_CountrolPoint 0;
BA_ "SigDescription" SG_ 205 PROLONG_CountrolPoint "[Default Value]
0x0";
BA_ "Platform" SG_ 205 PROLONG_CountrolPoint "";
BA_ "GenSigSendType" SG_ 205 PROLONG_CountrolPoint 4;
BA_ "NmNetworkRequest" SG_ 205 PROLONG_CountrolPoint 1;
BA_ "Validity" SG_ 205 PROLONG_CountrolPoint 2;
BA_REL_ "GenSigTimeoutTime" BU_SG_REL_ CGW SG_ 205 PROLONG_ProfileType 0;
BA_REL_ "GenSigTimeoutTime" BU_SG_REL_ CLU SG_ 205 PROLONG_ProfileType 0;
BA_ "SigDescription" SG_ 205 PROLONG_ProfileType "[Default Value]
0x0";
BA_ "Platform" SG_ 205 PROLONG_ProfileType "";
BA_ "GenSigSendType" SG_ 205 PROLONG_ProfileType 4;
BA_ "NmNetworkRequest" SG_ 205 PROLONG_ProfileType 1;
BA_ "Validity" SG_ 205 PROLONG_ProfileType 2;
BA_ "GenMsgCycleTimeFast" BO_ 204 40;
BA_ "GenMsgNrOfRepetition" BO_ 204 3;
BA_REL_ "GenSigTimeoutTime" BU_SG_REL_ CGW SG_ 204 PROSHORT_MessageType 0;
BA_REL_ "GenSigTimeoutTime" BU_SG_REL_ CLU SG_ 204 PROSHORT_MessageType 0;
BA_ "SigDescription" SG_ 204 PROSHORT_MessageType "[Default Value]
0x4";
BA_ "Platform" SG_ 204 PROSHORT_MessageType "";
BA_ "GenSigSendType" SG_ 204 PROSHORT_MessageType 4;
BA_ "GenSigStartValue" SG_ 204 PROSHORT_MessageType 7;
BA_ "NmNetworkRequest" SG_ 204 PROSHORT_MessageType 1;
BA_ "Validity" SG_ 204 PROSHORT_MessageType 2;
BA_REL_ "GenSigTimeoutTime" BU_SG_REL_ CGW SG_ 204 PROSHORT_Offset 0;
BA_REL_ "GenSigTimeoutTime" BU_SG_REL_ CLU SG_ 204 PROSHORT_Offset 0;
BA_ "SigDescription" SG_ 204 PROSHORT_Offset "[Default Value]
0x1FFF";
BA_ "Platform" SG_ 204 PROSHORT_Offset "";
BA_ "GenSigSendType" SG_ 204 PROSHORT_Offset 4;
BA_ "GenSigStartValue" SG_ 204 PROSHORT_Offset 8191;
BA_ "NmNetworkRequest" SG_ 204 PROSHORT_Offset 1;
BA_ "Validity" SG_ 204 PROSHORT_Offset 2;
BA_REL_ "GenSigTimeoutTime" BU_SG_REL_ CGW SG_ 204 PROSHORT_PathIndex 0;
BA_REL_ "GenSigTimeoutTime" BU_SG_REL_ CLU SG_ 204 PROSHORT_PathIndex 0;
BA_ "SigDescription" SG_ 204 PROSHORT_PathIndex "[Default Value]
0x0";
BA_ "Platform" SG_ 204 PROSHORT_PathIndex "";
BA_ "GenSigSendType" SG_ 204 PROSHORT_PathIndex 4;
BA_ "NmNetworkRequest" SG_ 204 PROSHORT_PathIndex 1;
BA_ "Validity" SG_ 204 PROSHORT_PathIndex 2;
BA_REL_ "GenSigTimeoutTime" BU_SG_REL_ CGW SG_ 204 PROSHORT_CyclicCounter 0;
BA_REL_ "GenSigTimeoutTime" BU_SG_REL_ CLU SG_ 204 PROSHORT_CyclicCounter 0;
BA_ "SigDescription" SG_ 204 PROSHORT_CyclicCounter "[Default Value]
0x0";
BA_ "Platform" SG_ 204 PROSHORT_CyclicCounter "";
BA_ "GenSigSendType" SG_ 204 PROSHORT_CyclicCounter 4;
BA_ "NmNetworkRequest" SG_ 204 PROSHORT_CyclicCounter 1;
BA_ "Validity" SG_ 204 PROSHORT_CyclicCounter 2;
BA_REL_ "GenSigTimeoutTime" BU_SG_REL_ CGW SG_ 204 PROSHORT_Accuracy 0;
BA_REL_ "GenSigTimeoutTime" BU_SG_REL_ CLU SG_ 204 PROSHORT_Accuracy 0;
BA_ "SigDescription" SG_ 204 PROSHORT_Accuracy "[Default Value]
0x3";
BA_ "Platform" SG_ 204 PROSHORT_Accuracy "";
BA_ "GenSigSendType" SG_ 204 PROSHORT_Accuracy 4;
BA_ "GenSigStartValue" SG_ 204 PROSHORT_Accuracy 3;
BA_ "NmNetworkRequest" SG_ 204 PROSHORT_Accuracy 1;
BA_ "Validity" SG_ 204 PROSHORT_Accuracy 2;
BA_REL_ "GenSigTimeoutTime" BU_SG_REL_ CGW SG_ 204 PROSHORT_Distance 0;
BA_REL_ "GenSigTimeoutTime" BU_SG_REL_ CLU SG_ 204 PROSHORT_Distance 0;
BA_ "SigDescription" SG_ 204 PROSHORT_Distance "[Default Value]
0x3FF";
BA_ "Platform" SG_ 204 PROSHORT_Distance "";
BA_ "GenSigSendType" SG_ 204 PROSHORT_Distance 4;
BA_ "GenSigStartValue" SG_ 204 PROSHORT_Distance 1023;
BA_ "NmNetworkRequest" SG_ 204 PROSHORT_Distance 1;
BA_ "Validity" SG_ 204 PROSHORT_Distance 2;
BA_REL_ "GenSigTimeoutTime" BU_SG_REL_ CGW SG_ 204 PROSHORT_Value0 0;
BA_REL_ "GenSigTimeoutTime" BU_SG_REL_ CLU SG_ 204 PROSHORT_Value0 0;
BA_ "SigDescription" SG_ 204 PROSHORT_Value0 "[Default Value]
0x3FF";
BA_ "Platform" SG_ 204 PROSHORT_Value0 "";
BA_ "GenSigSendType" SG_ 204 PROSHORT_Value0 4;
BA_ "GenSigStartValue" SG_ 204 PROSHORT_Value0 1023;
BA_ "NmNetworkRequest" SG_ 204 PROSHORT_Value0 1;
BA_ "Validity" SG_ 204 PROSHORT_Value0 2;
BA_REL_ "GenSigTimeoutTime" BU_SG_REL_ CGW SG_ 204 PROSHORT_Value1 0;
BA_REL_ "GenSigTimeoutTime" BU_SG_REL_ CLU SG_ 204 PROSHORT_Value1 0;
BA_ "SigDescription" SG_ 204 PROSHORT_Value1 "[Default Value]
0x3FF";
BA_ "Platform" SG_ 204 PROSHORT_Value1 "";
BA_ "GenSigSendType" SG_ 204 PROSHORT_Value1 4;
BA_ "GenSigStartValue" SG_ 204 PROSHORT_Value1 1023;
BA_ "NmNetworkRequest" SG_ 204 PROSHORT_Value1 1;
BA_ "Validity" SG_ 204 PROSHORT_Value1 2;
BA_REL_ "GenSigTimeoutTime" BU_SG_REL_ CGW SG_ 204 PROSHORT_Update 0;
BA_REL_ "GenSigTimeoutTime" BU_SG_REL_ CLU SG_ 204 PROSHORT_Update 0;
BA_ "SigDescription" SG_ 204 PROSHORT_Update "[Default Value]
0x0";
BA_ "Platform" SG_ 204 PROSHORT_Update "";
BA_ "GenSigSendType" SG_ 204 PROSHORT_Update 4;
BA_ "NmNetworkRequest" SG_ 204 PROSHORT_Update 1;
BA_ "Validity" SG_ 204 PROSHORT_Update 2;
BA_REL_ "GenSigTimeoutTime" BU_SG_REL_ CGW SG_ 204 PROSHORT_Retransmission 0;
BA_REL_ "GenSigTimeoutTime" BU_SG_REL_ CLU SG_ 204 PROSHORT_Retransmission 0;
BA_ "SigDescription" SG_ 204 PROSHORT_Retransmission "[Default Value]
0x0";
BA_ "Platform" SG_ 204 PROSHORT_Retransmission "";
BA_ "GenSigSendType" SG_ 204 PROSHORT_Retransmission 4;
BA_ "NmNetworkRequest" SG_ 204 PROSHORT_Retransmission 1;
BA_ "Validity" SG_ 204 PROSHORT_Retransmission 2;
BA_REL_ "GenSigTimeoutTime" BU_SG_REL_ CGW SG_ 204 PROSHORT_ControlPoint 0;
BA_REL_ "GenSigTimeoutTime" BU_SG_REL_ CLU SG_ 204 PROSHORT_ControlPoint 0;
BA_ "SigDescription" SG_ 204 PROSHORT_ControlPoint "[Default Value]
0x0";
BA_ "Platform" SG_ 204 PROSHORT_ControlPoint "";
BA_ "GenSigSendType" SG_ 204 PROSHORT_ControlPoint 4;
BA_ "NmNetworkRequest" SG_ 204 PROSHORT_ControlPoint 1;
BA_ "Validity" SG_ 204 PROSHORT_ControlPoint 2;
BA_REL_ "GenSigTimeoutTime" BU_SG_REL_ CGW SG_ 204 PROSHORT_ProfileType 0;
BA_REL_ "GenSigTimeoutTime" BU_SG_REL_ CLU SG_ 204 PROSHORT_ProfileType 0;
BA_ "SigDescription" SG_ 204 PROSHORT_ProfileType "[Default Value]
0x0";
BA_ "Platform" SG_ 204 PROSHORT_ProfileType "";
BA_ "GenSigSendType" SG_ 204 PROSHORT_ProfileType 4;
BA_ "NmNetworkRequest" SG_ 204 PROSHORT_ProfileType 1;
BA_ "Validity" SG_ 204 PROSHORT_ProfileType 2;
BA_ "GenMsgCycleTimeFast" BO_ 207 40;
BA_ "GenMsgNrOfRepetition" BO_ 207 3;
BA_REL_ "GenSigTimeoutTime" BU_SG_REL_ CGW SG_ 207 PROSHORT_MessageType_01 0;
BA_REL_ "GenSigTimeoutTime" BU_SG_REL_ CLU SG_ 207 PROSHORT_MessageType_01 0;
BA_ "SigDescription" SG_ 207 PROSHORT_MessageType_01 "[Default Value]
0x4";
BA_ "Platform" SG_ 207 PROSHORT_MessageType_01 "";
BA_ "GenSigSendType" SG_ 207 PROSHORT_MessageType_01 4;
BA_ "GenSigStartValue" SG_ 207 PROSHORT_MessageType_01 7;
BA_ "NmNetworkRequest" SG_ 207 PROSHORT_MessageType_01 1;
BA_ "Validity" SG_ 207 PROSHORT_MessageType_01 2;
BA_REL_ "GenSigTimeoutTime" BU_SG_REL_ CGW SG_ 207 PROSHORT_Offset_01 0;
BA_REL_ "GenSigTimeoutTime" BU_SG_REL_ CLU SG_ 207 PROSHORT_Offset_01 0;
BA_ "SigDescription" SG_ 207 PROSHORT_Offset_01 "[Default Value]
0x1FFF";
BA_ "Platform" SG_ 207 PROSHORT_Offset_01 "";
BA_ "GenSigSendType" SG_ 207 PROSHORT_Offset_01 4;
BA_ "GenSigStartValue" SG_ 207 PROSHORT_Offset_01 8191;
BA_ "NmNetworkRequest" SG_ 207 PROSHORT_Offset_01 1;
BA_ "Validity" SG_ 207 PROSHORT_Offset_01 2;
BA_REL_ "GenSigTimeoutTime" BU_SG_REL_ CGW SG_ 207 PROSHORT_PathIndex_01 0;
BA_REL_ "GenSigTimeoutTime" BU_SG_REL_ CLU SG_ 207 PROSHORT_PathIndex_01 0;
BA_ "SigDescription" SG_ 207 PROSHORT_PathIndex_01 "[Default Value]
0x0";
BA_ "Platform" SG_ 207 PROSHORT_PathIndex_01 "";
BA_ "GenSigSendType" SG_ 207 PROSHORT_PathIndex_01 4;
BA_ "NmNetworkRequest" SG_ 207 PROSHORT_PathIndex_01 1;
BA_ "Validity" SG_ 207 PROSHORT_PathIndex_01 2;
BA_REL_ "GenSigTimeoutTime" BU_SG_REL_ CGW SG_ 207 PROSHORT_CyclicCounter_01 0;
BA_REL_ "GenSigTimeoutTime" BU_SG_REL_ CLU SG_ 207 PROSHORT_CyclicCounter_01 0;
BA_ "SigDescription" SG_ 207 PROSHORT_CyclicCounter_01 "[Default Value]
0x0";
BA_ "Platform" SG_ 207 PROSHORT_CyclicCounter_01 "";
BA_ "GenSigSendType" SG_ 207 PROSHORT_CyclicCounter_01 4;
BA_ "NmNetworkRequest" SG_ 207 PROSHORT_CyclicCounter_01 1;
BA_ "Validity" SG_ 207 PROSHORT_CyclicCounter_01 2;
BA_REL_ "GenSigTimeoutTime" BU_SG_REL_ CGW SG_ 207 PROSHORT_Accuracy_01 0;
BA_REL_ "GenSigTimeoutTime" BU_SG_REL_ CLU SG_ 207 PROSHORT_Accuracy_01 0;
BA_ "SigDescription" SG_ 207 PROSHORT_Accuracy_01 "[Default Value]
0x3";
BA_ "Platform" SG_ 207 PROSHORT_Accuracy_01 "";
BA_ "GenSigSendType" SG_ 207 PROSHORT_Accuracy_01 4;
BA_ "GenSigStartValue" SG_ 207 PROSHORT_Accuracy_01 3;
BA_ "NmNetworkRequest" SG_ 207 PROSHORT_Accuracy_01 1;
BA_ "Validity" SG_ 207 PROSHORT_Accuracy_01 2;
BA_REL_ "GenSigTimeoutTime" BU_SG_REL_ CGW SG_ 207 PROSHORT_Distance_01 0;
BA_REL_ "GenSigTimeoutTime" BU_SG_REL_ CLU SG_ 207 PROSHORT_Distance_01 0;
BA_ "SigDescription" SG_ 207 PROSHORT_Distance_01 "[Default Value]
0x3FF";
BA_ "Platform" SG_ 207 PROSHORT_Distance_01 "";
BA_ "GenSigSendType" SG_ 207 PROSHORT_Distance_01 4;
BA_ "GenSigStartValue" SG_ 207 PROSHORT_Distance_01 1023;
BA_ "NmNetworkRequest" SG_ 207 PROSHORT_Distance_01 1;
BA_ "Validity" SG_ 207 PROSHORT_Distance_01 2;
BA_REL_ "GenSigTimeoutTime" BU_SG_REL_ CGW SG_ 207 PROSHORT_Value0_01 0;
BA_REL_ "GenSigTimeoutTime" BU_SG_REL_ CLU SG_ 207 PROSHORT_Value0_01 0;
BA_ "SigDescription" SG_ 207 PROSHORT_Value0_01 "[Default Value]
0x3FF";
BA_ "Platform" SG_ 207 PROSHORT_Value0_01 "";
BA_ "GenSigSendType" SG_ 207 PROSHORT_Value0_01 4;
BA_ "GenSigStartValue" SG_ 207 PROSHORT_Value0_01 1023;
BA_ "NmNetworkRequest" SG_ 207 PROSHORT_Value0_01 1;
BA_ "Validity" SG_ 207 PROSHORT_Value0_01 2;
BA_REL_ "GenSigTimeoutTime" BU_SG_REL_ CGW SG_ 207 PROSHORT_Value1_01 0;
BA_REL_ "GenSigTimeoutTime" BU_SG_REL_ CLU SG_ 207 PROSHORT_Value1_01 0;
BA_ "SigDescription" SG_ 207 PROSHORT_Value1_01 "[Default Value]
0x3FF";
BA_ "Platform" SG_ 207 PROSHORT_Value1_01 "";
BA_ "GenSigSendType" SG_ 207 PROSHORT_Value1_01 4;
BA_ "GenSigStartValue" SG_ 207 PROSHORT_Value1_01 1023;
BA_ "NmNetworkRequest" SG_ 207 PROSHORT_Value1_01 1;
BA_ "Validity" SG_ 207 PROSHORT_Value1_01 2;
BA_REL_ "GenSigTimeoutTime" BU_SG_REL_ CGW SG_ 207 PROSHORT_Update_01 0;
BA_REL_ "GenSigTimeoutTime" BU_SG_REL_ CLU SG_ 207 PROSHORT_Update_01 0;
BA_ "SigDescription" SG_ 207 PROSHORT_Update_01 "[Default Value]
0x0";
BA_ "Platform" SG_ 207 PROSHORT_Update_01 "";
BA_ "GenSigSendType" SG_ 207 PROSHORT_Update_01 4;
BA_ "NmNetworkRequest" SG_ 207 PROSHORT_Update_01 1;
BA_ "Validity" SG_ 207 PROSHORT_Update_01 2;
BA_REL_ "GenSigTimeoutTime" BU_SG_REL_ CGW SG_ 207 PROSHORT_Retransmission_01 0;
BA_REL_ "GenSigTimeoutTime" BU_SG_REL_ CLU SG_ 207 PROSHORT_Retransmission_01 0;
BA_ "SigDescription" SG_ 207 PROSHORT_Retransmission_01 "[Default Value]
0x0";
BA_ "Platform" SG_ 207 PROSHORT_Retransmission_01 "";
BA_ "GenSigSendType" SG_ 207 PROSHORT_Retransmission_01 4;
BA_ "NmNetworkRequest" SG_ 207 PROSHORT_Retransmission_01 1;
BA_ "Validity" SG_ 207 PROSHORT_Retransmission_01 2;
BA_REL_ "GenSigTimeoutTime" BU_SG_REL_ CGW SG_ 207 PROSHORT_ControlPoint_01 0;
BA_REL_ "GenSigTimeoutTime" BU_SG_REL_ CLU SG_ 207 PROSHORT_ControlPoint_01 0;
BA_ "SigDescription" SG_ 207 PROSHORT_ControlPoint_01 "[Default Value]
0x0";
BA_ "Platform" SG_ 207 PROSHORT_ControlPoint_01 "";
BA_ "GenSigSendType" SG_ 207 PROSHORT_ControlPoint_01 4;
BA_ "NmNetworkRequest" SG_ 207 PROSHORT_ControlPoint_01 1;
BA_ "Validity" SG_ 207 PROSHORT_ControlPoint_01 2;
BA_REL_ "GenSigTimeoutTime" BU_SG_REL_ CGW SG_ 207 PROSHORT_ProfileType_01 0;
BA_REL_ "GenSigTimeoutTime" BU_SG_REL_ CLU SG_ 207 PROSHORT_ProfileType_01 0;
BA_ "SigDescription" SG_ 207 PROSHORT_ProfileType_01 "[Default Value]
0x0";
BA_ "Platform" SG_ 207 PROSHORT_ProfileType_01 "";
BA_ "GenSigSendType" SG_ 207 PROSHORT_ProfileType_01 4;
BA_ "NmNetworkRequest" SG_ 207 PROSHORT_ProfileType_01 1;
BA_ "Validity" SG_ 207 PROSHORT_ProfileType_01 2;
BA_ "GenMsgILSupport" BO_ 1268 0;
BA_ "TpMessage" BO_ 1268 1;
BA_ "TpTxIndex" BO_ 1268 45;
BA_REL_ "GenSigTimeoutTime" BU_SG_REL_ CLU SG_ 1268 Byte0_TCP_4F4 0;
BA_ "Platform" SG_ 1268 Byte0_TCP_4F4 "";
BA_ "GenMsgILSupport" BO_ 1268 0;
BA_ "TpMessage" BO_ 1268 1;
BA_ "TpTxIndex" BO_ 1268 45;
BA_REL_ "GenSigTimeoutTime" BU_SG_REL_ CLU SG_ 1268 Byte1_Data_4F4 0;
BA_ "Platform" SG_ 1268 Byte1_Data_4F4 "";
BA_ "GenMsgILSupport" BO_ 1268 0;
BA_ "TpMessage" BO_ 1268 1;
BA_ "TpTxIndex" BO_ 1268 45;
BA_REL_ "GenSigTimeoutTime" BU_SG_REL_ CLU SG_ 1268 Byte2_Data_4F4 0;
BA_ "Platform" SG_ 1268 Byte2_Data_4F4 "";
BA_ "GenMsgILSupport" BO_ 1268 0;
BA_ "TpMessage" BO_ 1268 1;
BA_ "TpTxIndex" BO_ 1268 45;
BA_REL_ "GenSigTimeoutTime" BU_SG_REL_ CLU SG_ 1268 Byte3_Data_4F4 0;
BA_ "Platform" SG_ 1268 Byte3_Data_4F4 "";
BA_ "GenMsgILSupport" BO_ 1268 0;
BA_ "TpMessage" BO_ 1268 1;
BA_ "TpTxIndex" BO_ 1268 45;
BA_REL_ "GenSigTimeoutTime" BU_SG_REL_ CLU SG_ 1268 Byte4_Data_4F4 0;
BA_ "Platform" SG_ 1268 Byte4_Data_4F4 "";
BA_ "GenMsgILSupport" BO_ 1268 0;
BA_ "TpMessage" BO_ 1268 1;
BA_ "TpTxIndex" BO_ 1268 45;
BA_REL_ "GenSigTimeoutTime" BU_SG_REL_ CLU SG_ 1268 Byte5_Data_4F4 0;
BA_ "Platform" SG_ 1268 Byte5_Data_4F4 "";
BA_ "GenMsgILSupport" BO_ 1268 0;
BA_ "TpMessage" BO_ 1268 1;
BA_ "TpTxIndex" BO_ 1268 45;
BA_REL_ "GenSigTimeoutTime" BU_SG_REL_ CLU SG_ 1268 Byte6_Data_4F4 0;
BA_ "Platform" SG_ 1268 Byte6_Data_4F4 "";
BA_ "GenMsgILSupport" BO_ 1268 0;
BA_ "TpMessage" BO_ 1268 1;
BA_ "TpTxIndex" BO_ 1268 45;
BA_REL_ "GenSigTimeoutTime" BU_SG_REL_ CLU SG_ 1268 Byte7_Data_4F4 0;
BA_ "Platform" SG_ 1268 Byte7_Data_4F4 "";
BA_ "GenMsgILSupport" BO_ 1260 0;
BA_ "TpMessage" BO_ 1260 1;
BA_ "TpTxIndex" BO_ 1260 6;
BA_REL_ "GenSigTimeoutTime" BU_SG_REL_ CLU SG_ 1260 Byte0_TCP_4EC 0;
BA_ "Platform" SG_ 1260 Byte0_TCP_4EC "";
BA_ "GenMsgILSupport" BO_ 1260 0;
BA_ "TpMessage" BO_ 1260 1;
BA_ "TpTxIndex" BO_ 1260 6;
BA_REL_ "GenSigTimeoutTime" BU_SG_REL_ CLU SG_ 1260 Byte1_Data_4EC 0;
BA_ "Platform" SG_ 1260 Byte1_Data_4EC "";
BA_ "GenMsgILSupport" BO_ 1260 0;
BA_ "TpMessage" BO_ 1260 1;
BA_ "TpTxIndex" BO_ 1260 6;
BA_REL_ "GenSigTimeoutTime" BU_SG_REL_ CLU SG_ 1260 Byte2_Data_4EC 0;
BA_ "Platform" SG_ 1260 Byte2_Data_4EC "";
BA_ "GenMsgILSupport" BO_ 1260 0;
BA_ "TpMessage" BO_ 1260 1;
BA_ "TpTxIndex" BO_ 1260 6;
BA_REL_ "GenSigTimeoutTime" BU_SG_REL_ CLU SG_ 1260 Byte3_Data_4EC 0;
BA_ "Platform" SG_ 1260 Byte3_Data_4EC "";
BA_ "GenMsgILSupport" BO_ 1260 0;
BA_ "TpMessage" BO_ 1260 1;
BA_ "TpTxIndex" BO_ 1260 6;
BA_REL_ "GenSigTimeoutTime" BU_SG_REL_ CLU SG_ 1260 Byte4_Data_4EC 0;
BA_ "Platform" SG_ 1260 Byte4_Data_4EC "";
BA_ "GenMsgILSupport" BO_ 1260 0;
BA_ "TpMessage" BO_ 1260 1;
BA_ "TpTxIndex" BO_ 1260 6;
BA_REL_ "GenSigTimeoutTime" BU_SG_REL_ CLU SG_ 1260 Byte5_Data_4EC 0;
BA_ "Platform" SG_ 1260 Byte5_Data_4EC "";
BA_ "GenMsgILSupport" BO_ 1260 0;
BA_ "TpMessage" BO_ 1260 1;
BA_ "TpTxIndex" BO_ 1260 6;
BA_REL_ "GenSigTimeoutTime" BU_SG_REL_ CLU SG_ 1260 Byte6_Data_4EC 0;
BA_ "Platform" SG_ 1260 Byte6_Data_4EC "";
BA_ "GenMsgILSupport" BO_ 1260 0;
BA_ "TpMessage" BO_ 1260 1;
BA_ "TpTxIndex" BO_ 1260 6;
BA_REL_ "GenSigTimeoutTime" BU_SG_REL_ CLU SG_ 1260 Byte7_Data_4EC 0;
BA_ "Platform" SG_ 1260 Byte7_Data_4EC "";
BA_ "GenMsgILSupport" BO_ 1270 0;
BA_ "TpMessage" BO_ 1270 1;
BA_ "TpTxIndex" BO_ 1270 46;
BA_REL_ "GenSigTimeoutTime" BU_SG_REL_ CLU SG_ 1270 Byte0_TCP_4F6 0;
BA_ "Platform" SG_ 1270 Byte0_TCP_4F6 "";
BA_ "GenMsgILSupport" BO_ 1270 0;
BA_ "TpMessage" BO_ 1270 1;
BA_ "TpTxIndex" BO_ 1270 46;
BA_REL_ "GenSigTimeoutTime" BU_SG_REL_ CLU SG_ 1270 Byte1_Data_4F6 0;
BA_ "Platform" SG_ 1270 Byte1_Data_4F6 "";
BA_ "GenMsgILSupport" BO_ 1270 0;
BA_ "TpMessage" BO_ 1270 1;
BA_ "TpTxIndex" BO_ 1270 46;
BA_REL_ "GenSigTimeoutTime" BU_SG_REL_ CLU SG_ 1270 Byte2_Data_4F6 0;
BA_ "Platform" SG_ 1270 Byte2_Data_4F6 "";
BA_ "GenMsgILSupport" BO_ 1270 0;
BA_ "TpMessage" BO_ 1270 1;
BA_ "TpTxIndex" BO_ 1270 46;
BA_REL_ "GenSigTimeoutTime" BU_SG_REL_ CLU SG_ 1270 Byte3_Data_4F6 0;
BA_ "Platform" SG_ 1270 Byte3_Data_4F6 "";
BA_ "GenMsgILSupport" BO_ 1270 0;
BA_ "TpMessage" BO_ 1270 1;
BA_ "TpTxIndex" BO_ 1270 46;
BA_REL_ "GenSigTimeoutTime" BU_SG_REL_ CLU SG_ 1270 Byte4_Data_4F6 0;
BA_ "Platform" SG_ 1270 Byte4_Data_4F6 "";
BA_ "GenMsgILSupport" BO_ 1270 0;
BA_ "TpMessage" BO_ 1270 1;
BA_ "TpTxIndex" BO_ 1270 46;
BA_REL_ "GenSigTimeoutTime" BU_SG_REL_ CLU SG_ 1270 Byte5_Data_4F6 0;
BA_ "Platform" SG_ 1270 Byte5_Data_4F6 "";
BA_ "GenMsgILSupport" BO_ 1270 0;
BA_ "TpMessage" BO_ 1270 1;
BA_ "TpTxIndex" BO_ 1270 46;
BA_REL_ "GenSigTimeoutTime" BU_SG_REL_ CLU SG_ 1270 Byte6_Data_4F6 0;
BA_ "Platform" SG_ 1270 Byte6_Data_4F6 "";
BA_ "GenMsgILSupport" BO_ 1270 0;
BA_ "TpMessage" BO_ 1270 1;
BA_ "TpTxIndex" BO_ 1270 46;
BA_REL_ "GenSigTimeoutTime" BU_SG_REL_ CLU SG_ 1270 Byte7_Data_4F6 0;
BA_ "Platform" SG_ 1270 Byte7_Data_4F6 "";
BA_ "GenMsgILSupport" BO_ 1264 0;
BA_ "TpMessage" BO_ 1264 1;
BA_ "TpTxIndex" BO_ 1264 38;
BA_REL_ "GenSigTimeoutTime" BU_SG_REL_ CLU SG_ 1264 Byte0_TCP_4F0 0;
BA_ "Platform" SG_ 1264 Byte0_TCP_4F0 "";
BA_ "GenMsgILSupport" BO_ 1264 0;
BA_ "TpMessage" BO_ 1264 1;
BA_ "TpTxIndex" BO_ 1264 38;
BA_REL_ "GenSigTimeoutTime" BU_SG_REL_ CLU SG_ 1264 Byte1_Data_4F0 0;
BA_ "Platform" SG_ 1264 Byte1_Data_4F0 "";
BA_ "GenMsgILSupport" BO_ 1264 0;
BA_ "TpMessage" BO_ 1264 1;
BA_ "TpTxIndex" BO_ 1264 38;
BA_REL_ "GenSigTimeoutTime" BU_SG_REL_ CLU SG_ 1264 Byte2_Data_4F0 0;
BA_ "Platform" SG_ 1264 Byte2_Data_4F0 "";
BA_ "GenMsgILSupport" BO_ 1264 0;
BA_ "TpMessage" BO_ 1264 1;
BA_ "TpTxIndex" BO_ 1264 38;
BA_REL_ "GenSigTimeoutTime" BU_SG_REL_ CLU SG_ 1264 Byte3_Data_4F0 0;
BA_ "Platform" SG_ 1264 Byte3_Data_4F0 "";
BA_ "GenMsgILSupport" BO_ 1264 0;
BA_ "TpMessage" BO_ 1264 1;
BA_ "TpTxIndex" BO_ 1264 38;
BA_REL_ "GenSigTimeoutTime" BU_SG_REL_ CLU SG_ 1264 Byte4_Data_4F0 0;
BA_ "Platform" SG_ 1264 Byte4_Data_4F0 "";
BA_ "GenMsgILSupport" BO_ 1264 0;
BA_ "TpMessage" BO_ 1264 1;
BA_ "TpTxIndex" BO_ 1264 38;
BA_REL_ "GenSigTimeoutTime" BU_SG_REL_ CLU SG_ 1264 Byte5_Data_4F0 0;
BA_ "Platform" SG_ 1264 Byte5_Data_4F0 "";
BA_ "GenMsgILSupport" BO_ 1264 0;
BA_ "TpMessage" BO_ 1264 1;
BA_ "TpTxIndex" BO_ 1264 38;
BA_REL_ "GenSigTimeoutTime" BU_SG_REL_ CLU SG_ 1264 Byte6_Data_4F0 0;
BA_ "Platform" SG_ 1264 Byte6_Data_4F0 "";
BA_ "GenMsgILSupport" BO_ 1264 0;
BA_ "TpMessage" BO_ 1264 1;
BA_ "TpTxIndex" BO_ 1264 38;
BA_REL_ "GenSigTimeoutTime" BU_SG_REL_ CLU SG_ 1264 Byte7_Data_4F0 0;
BA_ "Platform" SG_ 1264 Byte7_Data_4F0 "";
BA_ "GenMsgILSupport" BO_ 1266 0;
BA_ "TpMessage" BO_ 1266 1;
BA_ "TpTxIndex" BO_ 1266 44;
BA_REL_ "GenSigTimeoutTime" BU_SG_REL_ CLU SG_ 1266 Byte0_TCP_4F2 0;
BA_ "Platform" SG_ 1266 Byte0_TCP_4F2 "";
BA_ "GenMsgILSupport" BO_ 1266 0;
BA_ "TpMessage" BO_ 1266 1;
BA_ "TpTxIndex" BO_ 1266 44;
BA_REL_ "GenSigTimeoutTime" BU_SG_REL_ CLU SG_ 1266 Byte1_Data_4F2 0;
BA_ "Platform" SG_ 1266 Byte1_Data_4F2 "";
BA_ "GenMsgILSupport" BO_ 1266 0;
BA_ "TpMessage" BO_ 1266 1;
BA_ "TpTxIndex" BO_ 1266 44;
BA_REL_ "GenSigTimeoutTime" BU_SG_REL_ CLU SG_ 1266 Byte2_Data_4F2 0;
BA_ "Platform" SG_ 1266 Byte2_Data_4F2 "";
BA_ "GenMsgILSupport" BO_ 1266 0;
BA_ "TpMessage" BO_ 1266 1;
BA_ "TpTxIndex" BO_ 1266 44;
BA_REL_ "GenSigTimeoutTime" BU_SG_REL_ CLU SG_ 1266 Byte3_Data_4F2 0;
BA_ "Platform" SG_ 1266 Byte3_Data_4F2 "";
BA_ "GenMsgILSupport" BO_ 1266 0;
BA_ "TpMessage" BO_ 1266 1;
BA_ "TpTxIndex" BO_ 1266 44;
BA_REL_ "GenSigTimeoutTime" BU_SG_REL_ CLU SG_ 1266 Byte4_Data_4F2 0;
BA_ "Platform" SG_ 1266 Byte4_Data_4F2 "";
BA_ "GenMsgILSupport" BO_ 1266 0;
BA_ "TpMessage" BO_ 1266 1;
BA_ "TpTxIndex" BO_ 1266 44;
BA_REL_ "GenSigTimeoutTime" BU_SG_REL_ CLU SG_ 1266 Byte5_Data_4F2 0;
BA_ "Platform" SG_ 1266 Byte5_Data_4F2 "";
BA_ "GenMsgILSupport" BO_ 1266 0;
BA_ "TpMessage" BO_ 1266 1;
BA_ "TpTxIndex" BO_ 1266 44;
BA_REL_ "GenSigTimeoutTime" BU_SG_REL_ CLU SG_ 1266 Byte6_Data_4F2 0;
BA_ "Platform" SG_ 1266 Byte6_Data_4F2 "";
BA_ "GenMsgILSupport" BO_ 1266 0;
BA_ "TpMessage" BO_ 1266 1;
BA_ "TpTxIndex" BO_ 1266 44;
BA_REL_ "GenSigTimeoutTime" BU_SG_REL_ CLU SG_ 1266 Byte7_Data_4F2 0;
BA_ "Platform" SG_ 1266 Byte7_Data_4F2 "";
BA_ "GenMsgILSupport" BO_ 1256 0;
BA_ "TpMessage" BO_ 1256 1;
BA_ "TpTxIndex" BO_ 1256 36;
BA_REL_ "GenSigTimeoutTime" BU_SG_REL_ CLU SG_ 1256 Byte0_TCP_4E8 0;
BA_ "Platform" SG_ 1256 Byte0_TCP_4E8 "";
BA_ "GenMsgILSupport" BO_ 1256 0;
BA_ "TpMessage" BO_ 1256 1;
BA_ "TpTxIndex" BO_ 1256 36;
BA_REL_ "GenSigTimeoutTime" BU_SG_REL_ CLU SG_ 1256 Byte1_Data_4E8 0;
BA_ "Platform" SG_ 1256 Byte1_Data_4E8 "";
BA_ "GenMsgILSupport" BO_ 1256 0;
BA_ "TpMessage" BO_ 1256 1;
BA_ "TpTxIndex" BO_ 1256 36;
BA_REL_ "GenSigTimeoutTime" BU_SG_REL_ CLU SG_ 1256 Byte2_Data_4E8 0;
BA_ "Platform" SG_ 1256 Byte2_Data_4E8 "";
BA_ "GenMsgILSupport" BO_ 1256 0;
BA_ "TpMessage" BO_ 1256 1;
BA_ "TpTxIndex" BO_ 1256 36;
BA_REL_ "GenSigTimeoutTime" BU_SG_REL_ CLU SG_ 1256 Byte3_Data_4E8 0;
BA_ "Platform" SG_ 1256 Byte3_Data_4E8 "";
BA_ "GenMsgILSupport" BO_ 1256 0;
BA_ "TpMessage" BO_ 1256 1;
BA_ "TpTxIndex" BO_ 1256 36;
BA_REL_ "GenSigTimeoutTime" BU_SG_REL_ CLU SG_ 1256 Byte4_Data_4E8 0;
BA_ "Platform" SG_ 1256 Byte4_Data_4E8 "";
BA_ "GenMsgILSupport" BO_ 1256 0;
BA_ "TpMessage" BO_ 1256 1;
BA_ "TpTxIndex" BO_ 1256 36;
BA_REL_ "GenSigTimeoutTime" BU_SG_REL_ CLU SG_ 1256 Byte5_Data_4E8 0;
BA_ "Platform" SG_ 1256 Byte5_Data_4E8 "";
BA_ "GenMsgILSupport" BO_ 1256 0;
BA_ "TpMessage" BO_ 1256 1;
BA_ "TpTxIndex" BO_ 1256 36;
BA_REL_ "GenSigTimeoutTime" BU_SG_REL_ CLU SG_ 1256 Byte6_Data_4E8 0;
BA_ "Platform" SG_ 1256 Byte6_Data_4E8 "";
BA_ "GenMsgILSupport" BO_ 1256 0;
BA_ "TpMessage" BO_ 1256 1;
BA_ "TpTxIndex" BO_ 1256 36;
BA_REL_ "GenSigTimeoutTime" BU_SG_REL_ CLU SG_ 1256 Byte7_Data_4E8 0;
BA_ "Platform" SG_ 1256 Byte7_Data_4E8 "";
BA_ "GenMsgILSupport" BO_ 1272 0;
BA_ "TpMessage" BO_ 1272 1;
BA_ "TpTxIndex" BO_ 1272 47;
BA_REL_ "GenSigTimeoutTime" BU_SG_REL_ CLU SG_ 1272 Byte0_TCP_4F8 0;
BA_ "Platform" SG_ 1272 Byte0_TCP_4F8 "";
BA_ "GenMsgILSupport" BO_ 1272 0;
BA_ "TpMessage" BO_ 1272 1;
BA_ "TpTxIndex" BO_ 1272 47;
BA_REL_ "GenSigTimeoutTime" BU_SG_REL_ CLU SG_ 1272 Byte1_Data_4F8 0;
BA_ "Platform" SG_ 1272 Byte1_Data_4F8 "";
BA_ "GenMsgILSupport" BO_ 1272 0;
BA_ "TpMessage" BO_ 1272 1;
BA_ "TpTxIndex" BO_ 1272 47;
BA_REL_ "GenSigTimeoutTime" BU_SG_REL_ CLU SG_ 1272 Byte2_Data_4F8 0;
BA_ "Platform" SG_ 1272 Byte2_Data_4F8 "";
BA_ "GenMsgILSupport" BO_ 1272 0;
BA_ "TpMessage" BO_ 1272 1;
BA_ "TpTxIndex" BO_ 1272 47;
BA_REL_ "GenSigTimeoutTime" BU_SG_REL_ CLU SG_ 1272 Byte3_Data_4F8 0;
BA_ "Platform" SG_ 1272 Byte3_Data_4F8 "";
BA_ "GenMsgILSupport" BO_ 1272 0;
BA_ "TpMessage" BO_ 1272 1;
BA_ "TpTxIndex" BO_ 1272 47;
BA_REL_ "GenSigTimeoutTime" BU_SG_REL_ CLU SG_ 1272 Byte4_Data_4F8 0;
BA_ "Platform" SG_ 1272 Byte4_Data_4F8 "";
BA_ "GenMsgILSupport" BO_ 1272 0;
BA_ "TpMessage" BO_ 1272 1;
BA_ "TpTxIndex" BO_ 1272 47;
BA_REL_ "GenSigTimeoutTime" BU_SG_REL_ CLU SG_ 1272 Byte5_Data_4F8 0;
BA_ "Platform" SG_ 1272 Byte5_Data_4F8 "";
BA_ "GenMsgILSupport" BO_ 1272 0;
BA_ "TpMessage" BO_ 1272 1;
BA_ "TpTxIndex" BO_ 1272 47;
BA_REL_ "GenSigTimeoutTime" BU_SG_REL_ CLU SG_ 1272 Byte6_Data_4F8 0;
BA_ "Platform" SG_ 1272 Byte6_Data_4F8 "";
BA_ "GenMsgILSupport" BO_ 1272 0;
BA_ "TpMessage" BO_ 1272 1;
BA_ "TpTxIndex" BO_ 1272 47;
BA_REL_ "GenSigTimeoutTime" BU_SG_REL_ CLU SG_ 1272 Byte7_Data_4F8 0;
BA_ "Platform" SG_ 1272 Byte7_Data_4F8 "";
BA_ "GenMsgILSupport" BO_ 1262 0;
BA_ "TpMessage" BO_ 1262 1;
BA_ "TpTxIndex" BO_ 1262 39;
BA_REL_ "GenSigTimeoutTime" BU_SG_REL_ CLU SG_ 1262 Byte0_TCP_4EE 0;
BA_ "Platform" SG_ 1262 Byte0_TCP_4EE "";
BA_ "GenMsgILSupport" BO_ 1262 0;
BA_ "TpMessage" BO_ 1262 1;
BA_ "TpTxIndex" BO_ 1262 39;
BA_REL_ "GenSigTimeoutTime" BU_SG_REL_ CLU SG_ 1262 Byte1_Data_4EE 0;
BA_ "Platform" SG_ 1262 Byte1_Data_4EE "";
BA_ "GenMsgILSupport" BO_ 1262 0;
BA_ "TpMessage" BO_ 1262 1;
BA_ "TpTxIndex" BO_ 1262 39;
BA_REL_ "GenSigTimeoutTime" BU_SG_REL_ CLU SG_ 1262 Byte2_Data_4EE 0;
BA_ "Platform" SG_ 1262 Byte2_Data_4EE "";
BA_ "GenMsgILSupport" BO_ 1262 0;
BA_ "TpMessage" BO_ 1262 1;
BA_ "TpTxIndex" BO_ 1262 39;
BA_REL_ "GenSigTimeoutTime" BU_SG_REL_ CLU SG_ 1262 Byte3_Data_4EE 0;
BA_ "Platform" SG_ 1262 Byte3_Data_4EE "";
BA_ "GenMsgILSupport" BO_ 1262 0;
BA_ "TpMessage" BO_ 1262 1;
BA_ "TpTxIndex" BO_ 1262 39;
BA_REL_ "GenSigTimeoutTime" BU_SG_REL_ CLU SG_ 1262 Byte4_Data_4EE 0;
BA_ "Platform" SG_ 1262 Byte4_Data_4EE "";
BA_ "GenMsgILSupport" BO_ 1262 0;
BA_ "TpMessage" BO_ 1262 1;
BA_ "TpTxIndex" BO_ 1262 39;
BA_REL_ "GenSigTimeoutTime" BU_SG_REL_ CLU SG_ 1262 Byte5_Data_4EE 0;
BA_ "Platform" SG_ 1262 Byte5_Data_4EE "";
BA_ "GenMsgILSupport" BO_ 1262 0;
BA_ "TpMessage" BO_ 1262 1;
BA_ "TpTxIndex" BO_ 1262 39;
BA_REL_ "GenSigTimeoutTime" BU_SG_REL_ CLU SG_ 1262 Byte6_Data_4EE 0;
BA_ "Platform" SG_ 1262 Byte6_Data_4EE "";
BA_ "GenMsgILSupport" BO_ 1262 0;
BA_ "TpMessage" BO_ 1262 1;
BA_ "TpTxIndex" BO_ 1262 39;
BA_REL_ "GenSigTimeoutTime" BU_SG_REL_ CLU SG_ 1262 Byte7_Data_4EE 0;
BA_ "Platform" SG_ 1262 Byte7_Data_4EE "";
BA_ "GenMsgILSupport" BO_ 1276 0;
BA_ "TpMessage" BO_ 1276 1;
BA_ "TpTxIndex" BO_ 1276 49;
BA_REL_ "GenSigTimeoutTime" BU_SG_REL_ CLU SG_ 1276 Byte0_TCP_4FC 0;
BA_ "Platform" SG_ 1276 Byte0_TCP_4FC "";
BA_ "GenMsgILSupport" BO_ 1276 0;
BA_ "TpMessage" BO_ 1276 1;
BA_ "TpTxIndex" BO_ 1276 49;
BA_REL_ "GenSigTimeoutTime" BU_SG_REL_ CLU SG_ 1276 Byte1_Data_4FC 0;
BA_ "Platform" SG_ 1276 Byte1_Data_4FC "";
BA_ "GenMsgILSupport" BO_ 1276 0;
BA_ "TpMessage" BO_ 1276 1;
BA_ "TpTxIndex" BO_ 1276 49;
BA_REL_ "GenSigTimeoutTime" BU_SG_REL_ CLU SG_ 1276 Byte2_Data_4FC 0;
BA_ "Platform" SG_ 1276 Byte2_Data_4FC "";
BA_ "GenMsgILSupport" BO_ 1276 0;
BA_ "TpMessage" BO_ 1276 1;
BA_ "TpTxIndex" BO_ 1276 49;
BA_REL_ "GenSigTimeoutTime" BU_SG_REL_ CLU SG_ 1276 Byte3_Data_4FC 0;
BA_ "Platform" SG_ 1276 Byte3_Data_4FC "";
BA_ "GenMsgILSupport" BO_ 1276 0;
BA_ "TpMessage" BO_ 1276 1;
BA_ "TpTxIndex" BO_ 1276 49;
BA_REL_ "GenSigTimeoutTime" BU_SG_REL_ CLU SG_ 1276 Byte4_Data_4FC 0;
BA_ "Platform" SG_ 1276 Byte4_Data_4FC "";
BA_ "GenMsgILSupport" BO_ 1276 0;
BA_ "TpMessage" BO_ 1276 1;
BA_ "TpTxIndex" BO_ 1276 49;
BA_REL_ "GenSigTimeoutTime" BU_SG_REL_ CLU SG_ 1276 Byte5_Data_4FC 0;
BA_ "Platform" SG_ 1276 Byte5_Data_4FC "";
BA_ "GenMsgILSupport" BO_ 1276 0;
BA_ "TpMessage" BO_ 1276 1;
BA_ "TpTxIndex" BO_ 1276 49;
BA_REL_ "GenSigTimeoutTime" BU_SG_REL_ CLU SG_ 1276 Byte6_Data_4FC 0;
BA_ "Platform" SG_ 1276 Byte6_Data_4FC "";
BA_ "GenMsgILSupport" BO_ 1276 0;
BA_ "TpMessage" BO_ 1276 1;
BA_ "TpTxIndex" BO_ 1276 49;
BA_REL_ "GenSigTimeoutTime" BU_SG_REL_ CLU SG_ 1276 Byte7_Data_4FC 0;
BA_ "Platform" SG_ 1276 Byte7_Data_4FC "";
BA_ "GenMsgILSupport" BO_ 1250 0;
BA_ "TpMessage" BO_ 1250 1;
BA_ "TpTxIndex" BO_ 1250 33;
BA_REL_ "GenSigTimeoutTime" BU_SG_REL_ CLU SG_ 1250 Byte0_TCP_4E2 0;
BA_ "Platform" SG_ 1250 Byte0_TCP_4E2 "";
BA_ "GenMsgILSupport" BO_ 1250 0;
BA_ "TpMessage" BO_ 1250 1;
BA_ "TpTxIndex" BO_ 1250 33;
BA_REL_ "GenSigTimeoutTime" BU_SG_REL_ CLU SG_ 1250 Byte1_Data_4E2 0;
BA_ "Platform" SG_ 1250 Byte1_Data_4E2 "";
BA_ "GenMsgILSupport" BO_ 1250 0;
BA_ "TpMessage" BO_ 1250 1;
BA_ "TpTxIndex" BO_ 1250 33;
BA_REL_ "GenSigTimeoutTime" BU_SG_REL_ CLU SG_ 1250 Byte2_Data_4E2 0;
BA_ "Platform" SG_ 1250 Byte2_Data_4E2 "";
BA_ "GenMsgILSupport" BO_ 1250 0;
BA_ "TpMessage" BO_ 1250 1;
BA_ "TpTxIndex" BO_ 1250 33;
BA_REL_ "GenSigTimeoutTime" BU_SG_REL_ CLU SG_ 1250 Byte3_Data_4E2 0;
BA_ "Platform" SG_ 1250 Byte3_Data_4E2 "";
BA_ "GenMsgILSupport" BO_ 1250 0;
BA_ "TpMessage" BO_ 1250 1;
BA_ "TpTxIndex" BO_ 1250 33;
BA_REL_ "GenSigTimeoutTime" BU_SG_REL_ CLU SG_ 1250 Byte4_Data_4E2 0;
BA_ "Platform" SG_ 1250 Byte4_Data_4E2 "";
BA_ "GenMsgILSupport" BO_ 1250 0;
BA_ "TpMessage" BO_ 1250 1;
BA_ "TpTxIndex" BO_ 1250 33;
BA_REL_ "GenSigTimeoutTime" BU_SG_REL_ CLU SG_ 1250 Byte5_Data_4E2 0;
BA_ "Platform" SG_ 1250 Byte5_Data_4E2 "";
BA_ "GenMsgILSupport" BO_ 1250 0;
BA_ "TpMessage" BO_ 1250 1;
BA_ "TpTxIndex" BO_ 1250 33;
BA_REL_ "GenSigTimeoutTime" BU_SG_REL_ CLU SG_ 1250 Byte6_Data_4E2 0;
BA_ "Platform" SG_ 1250 Byte6_Data_4E2 "";
BA_ "GenMsgILSupport" BO_ 1250 0;
BA_ "TpMessage" BO_ 1250 1;
BA_ "TpTxIndex" BO_ 1250 33;
BA_REL_ "GenSigTimeoutTime" BU_SG_REL_ CLU SG_ 1250 Byte7_Data_4E2 0;
BA_ "Platform" SG_ 1250 Byte7_Data_4E2 "";
BA_ "GenMsgILSupport" BO_ 1274 0;
BA_ "TpMessage" BO_ 1274 1;
BA_ "TpTxIndex" BO_ 1274 48;
BA_REL_ "GenSigTimeoutTime" BU_SG_REL_ CLU SG_ 1274 Byte0_TCP_4FA 0;
BA_ "Platform" SG_ 1274 Byte0_TCP_4FA "";
BA_ "GenMsgILSupport" BO_ 1274 0;
BA_ "TpMessage" BO_ 1274 1;
BA_ "TpTxIndex" BO_ 1274 48;
BA_REL_ "GenSigTimeoutTime" BU_SG_REL_ CLU SG_ 1274 Byte1_Data_4FA 0;
BA_ "Platform" SG_ 1274 Byte1_Data_4FA "";
BA_ "GenMsgILSupport" BO_ 1274 0;
BA_ "TpMessage" BO_ 1274 1;
BA_ "TpTxIndex" BO_ 1274 48;
BA_REL_ "GenSigTimeoutTime" BU_SG_REL_ CLU SG_ 1274 Byte2_Data_4FA 0;
BA_ "Platform" SG_ 1274 Byte2_Data_4FA "";
BA_ "GenMsgILSupport" BO_ 1274 0;
BA_ "TpMessage" BO_ 1274 1;
BA_ "TpTxIndex" BO_ 1274 48;
BA_REL_ "GenSigTimeoutTime" BU_SG_REL_ CLU SG_ 1274 Byte3_Data_4FA 0;
BA_ "Platform" SG_ 1274 Byte3_Data_4FA "";
BA_ "GenMsgILSupport" BO_ 1274 0;
BA_ "TpMessage" BO_ 1274 1;
BA_ "TpTxIndex" BO_ 1274 48;
BA_REL_ "GenSigTimeoutTime" BU_SG_REL_ CLU SG_ 1274 Byte4_Data_4FA 0;
BA_ "Platform" SG_ 1274 Byte4_Data_4FA "";
BA_ "GenMsgILSupport" BO_ 1274 0;
BA_ "TpMessage" BO_ 1274 1;
BA_ "TpTxIndex" BO_ 1274 48;
BA_REL_ "GenSigTimeoutTime" BU_SG_REL_ CLU SG_ 1274 Byte5_Data_4FA 0;
BA_ "Platform" SG_ 1274 Byte5_Data_4FA "";
BA_ "GenMsgILSupport" BO_ 1274 0;
BA_ "TpMessage" BO_ 1274 1;
BA_ "TpTxIndex" BO_ 1274 48;
BA_REL_ "GenSigTimeoutTime" BU_SG_REL_ CLU SG_ 1274 Byte6_Data_4FA 0;
BA_ "Platform" SG_ 1274 Byte6_Data_4FA "";
BA_ "GenMsgILSupport" BO_ 1274 0;
BA_ "TpMessage" BO_ 1274 1;
BA_ "TpTxIndex" BO_ 1274 48;
BA_REL_ "GenSigTimeoutTime" BU_SG_REL_ CLU SG_ 1274 Byte7_Data_4FA 0;
BA_ "Platform" SG_ 1274 Byte7_Data_4FA "";
BA_ "GenMsgILSupport" BO_ 1258 0;
BA_ "TpMessage" BO_ 1258 1;
BA_ "TpTxIndex" BO_ 1258 37;
BA_REL_ "GenSigTimeoutTime" BU_SG_REL_ CLU SG_ 1258 Byte0_TCP_4EA 0;
BA_ "Platform" SG_ 1258 Byte0_TCP_4EA "";
BA_ "GenMsgILSupport" BO_ 1258 0;
BA_ "TpMessage" BO_ 1258 1;
BA_ "TpTxIndex" BO_ 1258 37;
BA_REL_ "GenSigTimeoutTime" BU_SG_REL_ CLU SG_ 1258 Byte1_Data_4EA 0;
BA_ "Platform" SG_ 1258 Byte1_Data_4EA "";
BA_ "GenMsgILSupport" BO_ 1258 0;
BA_ "TpMessage" BO_ 1258 1;
BA_ "TpTxIndex" BO_ 1258 37;
BA_REL_ "GenSigTimeoutTime" BU_SG_REL_ CLU SG_ 1258 Byte2_Data_4EA 0;
BA_ "Platform" SG_ 1258 Byte2_Data_4EA "";
BA_ "GenMsgILSupport" BO_ 1258 0;
BA_ "TpMessage" BO_ 1258 1;
BA_ "TpTxIndex" BO_ 1258 37;
BA_REL_ "GenSigTimeoutTime" BU_SG_REL_ CLU SG_ 1258 Byte3_Data_4EA 0;
BA_ "Platform" SG_ 1258 Byte3_Data_4EA "";
BA_ "GenMsgILSupport" BO_ 1258 0;
BA_ "TpMessage" BO_ 1258 1;
BA_ "TpTxIndex" BO_ 1258 37;
BA_REL_ "GenSigTimeoutTime" BU_SG_REL_ CLU SG_ 1258 Byte4_Data_4EA 0;
BA_ "Platform" SG_ 1258 Byte4_Data_4EA "";
BA_ "GenMsgILSupport" BO_ 1258 0;
BA_ "TpMessage" BO_ 1258 1;
BA_ "TpTxIndex" BO_ 1258 37;
BA_REL_ "GenSigTimeoutTime" BU_SG_REL_ CLU SG_ 1258 Byte5_Data_4EA 0;
BA_ "Platform" SG_ 1258 Byte5_Data_4EA "";
BA_ "GenMsgILSupport" BO_ 1258 0;
BA_ "TpMessage" BO_ 1258 1;
BA_ "TpTxIndex" BO_ 1258 37;
BA_REL_ "GenSigTimeoutTime" BU_SG_REL_ CLU SG_ 1258 Byte6_Data_4EA 0;
BA_ "Platform" SG_ 1258 Byte6_Data_4EA "";
BA_ "GenMsgILSupport" BO_ 1258 0;
BA_ "TpMessage" BO_ 1258 1;
BA_ "TpTxIndex" BO_ 1258 37;
BA_REL_ "GenSigTimeoutTime" BU_SG_REL_ CLU SG_ 1258 Byte7_Data_4EA 0;
BA_ "Platform" SG_ 1258 Byte7_Data_4EA "";
VAL_ 384 HU_InitInfo 0 "Not used" 1 "Init_request" 2 "Init_completed" 3 "Invalid" ;
VAL_ 384 AMP_ASDModeState 0 "Not use" 1 "ASD OFF" 2 "Reserved" 3 "ASD ON" 4 "Reserved" 5 "Reserved" 6 "Reserved" 7 "Invalid" ;
VAL_ 384 AMP_NaviModeState 0 "Navi Off" 1 "Navi ON" 2 "Unused" 3 "Invalid" ;
VAL_ 384 AMP_SPDIFInfo 0 "Not used" 1 "Unlock" 2 "Null" 3 "PCM" 4 "Compressed" 5 "Reserved" 6 "Reserved" 7 "Invalid" ;
VAL_ 384 AMP_StartUpComplete 0 "Not used" 1 "Start-up completed" 2 "Reserved" 3 "Invalid" ;
VAL_ 384 AMP_VSCModeState 0 "Speed gain mode Off" 1 "Speed gain mode On" 2 "state of SDVC 4 StePControl" 3 "Invalid" ;
VAL_ 384 AMP_SDVCStepState 0 "off" 1 "low" 2 "mid" 3 "high" 7 "Invalid" ;
VAL_ 384 AMP_Beep1ModeState 0 "Beep1 mode off" 1 "Beep1 mode On" 2 "Unsed" 3 "InValid" ;
VAL_ 384 AMP_DistrInfoState 255 "Invalid" ;
VAL_ 384 AMP_INFORM_TO_IPM 0 "off" 1 "Warning Sound Supportable" 2 "Reserved" 3 "Invalid" ;
VAL_ 479 Clu_OutTempC 0 "0x0~0x64:-40~60¡É" 100 "0x0~0x64:-40~60¡É" 101 "0x65~0xFE:Reserved" 254 "0x65~0xFE:Reserved" 255 "Invalid" ;
VAL_ 479 Clu_OutTempF 0 "0x0~0xB4:-40~140¢µ" 180 "0x0~0xB4:-40~140¢µ" 181 "Reserved" 182 "Reserved" 183 "Reserved" 184 "Reserved" 185 "Reserved" 186 "Reserved" 187 "Reserved" 188 "Reserved" 189 "Reserved" 190 "Reserved" 191 "Reserved" 192 "Reserved" 193 "Reserved" 194 "Reserved" 195 "Reserved" 196 "Reserved" 197 "Reserved" 198 "Reserved" 199 "Reserved" 200 "Reserved" 201 "Reserved" 202 "Reserved" 203 "Reserved" 204 "Reserved" 205 "Reserved" 206 "Reserved" 207 "Reserved" 208 "Reserved" 209 "Reserved" 210 "Reserved" 211 "Reserved" 212 "Reserved" 213 "Reserved" 214 "Reserved" 215 "Reserved" 216 "Reserved" 217 "Reserved" 218 "Reserved" 219 "Reserved" 220 "Reserved" 221 "Reserved" 222 "Reserved" 223 "Reserved" 224 "Reserved" 225 "Reserved" 226 "Reserved" 227 "Reserved" 228 "Reserved" 229 "Reserved" 230 "Reserved" 231 "Reserved" 232 "Reserved" 233 "Reserved" 234 "Reserved" 235 "Reserved" 236 "Reserved" 237 "Reserved" 238 "Reserved" 239 "Reserved" 240 "Reserved" 241 "Reserved" 242 "Reserved" 243 "Reserved" 244 "Reserved" 245 "Reserved" 246 "Reserved" 247 "Reserved" 248 "Reserved" 249 "Reserved" 250 "Reserved" 251 "Reserved" 252 "Reserved" 253 "Reserved" 254 "Reserved" 255 "Invalid" ;
VAL_ 479 C_InhibitNMT 0 "Off" 1 "On" 2 "Reserved" 3 "Invalid" ;
VAL_ 479 Clu_RheostatLvl 0 "reserved" 1 "Step 1" 2 "Step 2" 3 "Step 3" 4 "Step 4" 5 "Step 5" 6 "Step 6" 7 "Step 7" 8 "Step 8" 9 "Step 9" 10 "Step 10" 11 "Step 11" 12 "Step 12" 13 "Step 13" 14 "Step 14" 15 "Step 15" 16 "Step 16" 17 "Step 17" 18 "Step 18" 19 "Step 19" 20 "Step 20(Reset Value)" 21 "Step 21 (Detent)" 31 "Invalid" ;
VAL_ 277 TBT_Display_Type 0 "No Symbol" 1 "No info" 16 "Turn Combination2" 17 "Exit-R" 18 "Exit-L" 19 "Exit Combination1-R" 20 "Exit Combination1-L" 21 "Exit Combination2-R" 22 "Exit Combination2-L" 23 "Srv Road-R" 24 "Srv Road-L" 25 "Fork-2" 26 "Fork-3" 27 "Roundabout Trs-R" 28 "Roundabout Trs-L" 29 "Square Trs-R" 30 "Square Trs-L" 31 "U turn" 2 "Direction to Dest" 32 "Exit Roundabout Trs-R" 33 "Exit Roundabout Trs-L" 34 "Prepare Turn" 35 "Prepare Roundabout" 36 "Prepare Exit" 37 "Prepare Square" 38 "Prepare U Turn" 39 "Exit Ramp Up-R" 40 "Exit Ramp Down-R" 41 "Exit Ramp Up-L" 42 "Exit Ramp Down-L" 43 "Overpass-R" 44 "Overpass-L" 45 "Underpass-R" 46 "Underpass-L" 47 "Schematic Diagram" 3 "Arrived" 4 "Near Dest" 64 "No Direction" 65 "Straight" 66 "Turn 1 oclock" 67 "Turn-R" 68 "Turn 4 oclock" 69 "Turn 8 oclock" 70 "Turn-L" 71 "Turn 11 oclock" 72 "U Turn-L" 73 "U Turn-R" 74 "P Turn-L" 75 "P Turn-R" 76 "Permitted Turn-L" 5 "Arrived Dest Off Map" 80 "Aside Overpass-C" 81 "Aside Overpass-R" 82 "Aside Overpass-L" 83 "Aside Underpass-C" 84 "Aside Underpass-R" 85 "Aside Underpass-L" 86 "Into Overpass-C" 87 "Into Overpass-R" 88 "Into Overpass-L" 89 "Into Underpass-C" 90 "Into Underpass-R" 91 "Into Underpass-L" 6 "OffRoad" 96 "Roundabout(R12)" 97 "Roundabout(R1~R11)" 98 "Roundabout(R1~R11)" 99 "Roundabout(R1~R11)" 100 "Roundabout(R1~R11)" 101 "Roundabout(R1~R11)" 102 "Roundabout(R1~R11)" 103 "Roundabout(R1~R11)" 104 "Roundabout(R1~R11)" 105 "Roundabout(R1~R11)" 106 "Roundabout(R1~R11)" 107 "Roundabout(R1~R11)" 7 "Off Map" 112 "Dest-C" 113 "Dest-R" 114 "Dest-L" 115 "WP1-C" 116 "WP1-R" 117 "WP1-L" 118 "WP2-C" 119 "WP2-R" 120 "WP2-L" 121 "WP3-C" 122 "WP3-R" 123 "WP3-L" 124 "WP4-C" 125 "WP4-R" 126 "WP4-L" 8 "No Route(Compass)" 128 "WP5-C" 129 "WP5-L" 130 "WP5-R" 131 "WP6-C" 132 "WP6-L" 133 "WP6-R" 134 "WP7-C" 135 "WP7-L" 136 "WP7-R" 137 "walk to Dest" 138 "walk to WP1" 139 "walk to WP2" 140 "walk to WP3" 141 "walk to WP4" 9 "Calc Route" 144 "Fork-2-R" 145 "Fork-2-L" 146 "Fork-SR Straight" 147 "Fork-SR-R" 148 "Fork-SL Straight" 149 "Fork-SL-L" 10 "Recalc Route" 160 "FWY Entrance-C" 161 "FWY Entrance-R" 162 "FWY Entrance-L" 163 "FWY Exit-C" 164 "FWY Exit-R" 165 "FWY Exit-L" 166 "CHWY Entrance-C" 167 "CHWY Entrance-R" 168 "CHWY Entrance-L" 169 "CHWY Exit-C" 170 "CHWY Exit-R" 171 "CHWY Exit-L" 172 "MainRoad Entrance-C" 173 "MainRoad Entrance-R" 174 "MainRoad Entrance-L" 11 "Follow Street" 176 "Ferry" 177 "Tunnel" 178 "Toll" 179 "IC" 180 "JC" 181 "SA" 182 "PA" 183 "SA Entrance" 184 "Coin Toll" 185 "JC Exit-C" 186 "JC Exit-R" 187 "JC Exit-L" 12 "Change Lane" 192 "Roundabout(L12)" 193 "Roundabout(L1~L11)" 194 "Roundabout(L1~L11)" 195 "Roundabout(L1~L11)" 196 "Roundabout(L1~L11)" 197 "Roundabout(L1~L11)" 198 "Roundabout(L1~L11)" 199 "Roundabout(L1~L11)" 200 "Roundabout(L1~L11)" 201 "Roundabout(L1~L11)" 202 "Roundabout(L1~L11)" 203 "Roundabout(L1~L11)" 204 "Enter roundabout" 205 "Exit roundabout" 206 "most-L of line" 207 "most-R of line" 13 "Turn" 208 "M of line" 209 "most-L of 3 normal/JCT/SAPA" 210 "most-R of 3 normal/JCT/SAPA" 211 "Enter ferry" 212 "Exit ferry" 213 "8 direction L front-L" 214 "8 direction L front-R" 215 "8 direction R front-L" 216 "8 direction R front-R" 217 "Go Straight Conditions" 218 "M of 3 normal/JCT/SAPA" 219 "Starting Point" 220 "IC 2 on L straight walk IC" 221 "IC 2 on the R straight walk IC" 222 "Normal/JCT/SAPA 2 on L straight line" 223 "Normal/JCT/SAPA 2 on R straight line" 14 "Turn On Main Road" 224 "Normal/JCT/SAPA 3 on L straight line" 225 "Normal/JCT/SAPA 3 on M straight line" 226 "Normal/JCT/SAPA 3 on R straight line" 227 "IC 3 on L side of IC" 228 "IC 3 on M side of IC" 229 "IC 3 on R side of IC" 230 "IC 3 on L straight line" 231 "IC 3 on M straight line" 232 "IC 3 on R straight line" 233 "8 direction straight L" 234 "8 direction straight R" 235 "8 direction on the most L straight line" 236 "8 direction on M straight line" 237 "8 direction on the most R straight line" 238 "8 direction turn L, then L" 239 "8 direction turn L, then R" 15 "Turn Combination1" 240 "8 direction turn L, then the most L" 241 "8 direction turn L, then M" 242 "8 direction turn L, then the most R" 243 "8 direction turn R, then L" 244 "8 direction turn R, then R" 245 "8 direction turn R, then the most L" 246 "8 direction turn R, then M" 247 "8 direction turn R, then the most R" 248 "8 direction turn around, then L" 249 "8 direction turn around, then R" 250 "8 direction turn around, then the most L" 251 "8 direction turn around, then M" 252 "8 direction turn around, then the most R" 253 "Reserved" 254 "Reserved" 255 "Invalid" ;
VAL_ 277 TBT_Side_Street 65535 "Invalid" ;
VAL_ 277 TBT_Direction 0 "Increase value (0~352.5 deg.)" 1 "Increase value (0~352.5 deg.)" 2 "Increase value (0~352.5 deg.)" 3 "Increase value (0~352.5 deg.)" 4 "Increase value (0~352.5 deg.)" 5 "Increase value (0~352.5 deg.)" 6 "Increase value (0~352.5 deg.)" 7 "Increase value (0~352.5 deg.)" 8 "Increase value (0~352.5 deg.)" 9 "Increase value (0~352.5 deg.)" 10 "Increase value (0~352.5 deg.)" 11 "Increase value (0~352.5 deg.)" 12 "Increase value (0~352.5 deg.)" 13 "Increase value (0~352.5 deg.)" 14 "Increase value (0~352.5 deg.)" 15 "Increase value (0~352.5 deg.)" 16 "Increase value (0~352.5 deg.)" 17 "Increase value (0~352.5 deg.)" 18 "Increase value (0~352.5 deg.)" 19 "Increase value (0~352.5 deg.)" 20 "Increase value (0~352.5 deg.)" 21 "Increase value (0~352.5 deg.)" 22 "Increase value (0~352.5 deg.)" 23 "Increase value (0~352.5 deg.)" 24 "Increase value (0~352.5 deg.)" 25 "Increase value (0~352.5 deg.)" 26 "Increase value (0~352.5 deg.)" 27 "Increase value (0~352.5 deg.)" 28 "Increase value (0~352.5 deg.)" 29 "Increase value (0~352.5 deg.)" 30 "Increase value (0~352.5 deg.)" 31 "Increase value (0~352.5 deg.)" 32 "Increase value (0~352.5 deg.)" 33 "Increase value (0~352.5 deg.)" 34 "Increase value (0~352.5 deg.)" 35 "Increase value (0~352.5 deg.)" 36 "Increase value (0~352.5 deg.)" 37 "Increase value (0~352.5 deg.)" 38 "Increase value (0~352.5 deg.)" 39 "Increase value (0~352.5 deg.)" 40 "Increase value (0~352.5 deg.)" 41 "Increase value (0~352.5 deg.)" 42 "Increase value (0~352.5 deg.)" 43 "Increase value (0~352.5 deg.)" 44 "Increase value (0~352.5 deg.)" 45 "Increase value (0~352.5 deg.)" 46 "Increase value (0~352.5 deg.)" 47 "Increase value (0~352.5 deg.)" 255 "Invalid" ;
VAL_ 277 TBT_Distance_Turn_Point 0 "0" 1 "0x0001~0xFFFE:distance" 65534 "0x0001~0xFFFE:distance" 65535 "Invalid" ;
VAL_ 277 TBT_Combined_Side_Street 0 "No Combined" 1 "Right Combined" 2 "Left combined" 3 "Bothside" 4 "Reserved" 5 "Reserved" 6 "Reserved" 7 "Reserved" 8 "Reserved" 9 "Reserved" 10 "Reserved" 11 "Reserved" 12 "Reserved" 13 "Reserved" 14 "Reserved" 15 "Invalid" ;
VAL_ 277 TBT_Scale 0 "Meter" 1 "Kilometer" 2 "Mile" 3 "Feet" 4 "yard" 15 "Invalid" ;
VAL_ 277 TBT_DistancetoTurnPoint 0 "0" 1 "number of tuning point" 2 "number of tuning point" 3 "number of tuning point" 4 "number of tuning point" 5 "number of tuning point" 6 "number of tuning point" 7 "number of tuning point" 8 "number of tuning point" 9 "number of tuning point" 10 "Reserved" 11 "Reserved" 12 "Reserved" 13 "Reserved" 14 "Reserved" 15 "Invalid" ;
VAL_ 406 HD_SPS_ChannelNo 0 "Off" 1 "HD" 2 "HD1" 3 "HD2" 4 "HD3" 5 "HD4" 6 "HD5" 7 "HD6" 8 "HD7" 9 "HD8" 10 "reserved" 11 "reserved" 12 "reserved" 13 "reserved" 14 "reserved" 15 "Invalid" ;
VAL_ 406 SXM_ChannelNo 1023 "Invalid" ;
VAL_ 407 HU_LanguageInfo 0 "Off" 1 "Korea" 2 "English(US)" 3 "English(UK)" 4 "Simplified chinese" 5 "Traditional chinese" 6 "French(EU)" 7 "Spanish(EU)" 8 "Arabic" 9 "Czech" 10 "Danish" 11 "German" 12 "Italian" 13 "Dutch" 14 "Polish" 15 "Portuguese" 16 "Russain" 17 "Slovak" 18 "Swedish" 19 "Turkish" 20 "French(US)" 21 "Spanish(US)" 22 "English(India)" 23 "Norwegian" 24 "Finnish" 25 "Indonesian" 26 "Brazilian Portuguese" 27 "Malay" 28 "Hungarian" 29 "English (Australia)" 30 "Japanese" 31 "0x1F~0xFE:reserved" 254 "0x1F~0xFE:reserved" 255 "Invalid" ;
VAL_ 407 HU_MuteStatus 0 "Off" 1 "Mute On" 2 "reserved" 3 "Invalid" ;
VAL_ 407 HU_VolumeStatus 63 "Invalid" ;
VAL_ 407 HU_NaviDisp 0 "Non_Navi" 1 "Navi" 2 "reserved" 3 "Invalid" ;
VAL_ 407 HU_NaviStatus 0 "Booting" 1 "Normal Operation" 2 "No SD Card(Map)" 3 "Invalid" ;
VAL_ 407 HU_UsmSupport 0 "Not support" 1 "Support" 2 "reserved" 3 "Invalid" ;
VAL_ 407 HU_NaviCamSettingStatus 0 "Navi Camera Alert Setting Status" 1 "Navi Camera Alert Setting Status" 2 "Navi Camera Alert Setting Status" 3 "Navi Camera Alert Setting Status" 4 "Navi Camera Alert Setting Status" 5 "Navi Camera Alert Setting Status" 6 "Navi Camera Alert Setting Status" 7 "Navi Camera Alert Setting Status" 8 "Navi Camera Alert Setting Status" 9 "Navi Camera Alert Setting Status" 10 "Navi Camera Alert Setting Status" 11 "Navi Camera Alert Setting Status" 12 "Navi Camera Alert Setting Status" 13 "Navi Camera Alert Setting Status" 14 "Navi Camera Alert Setting Status" 15 "Navi Camera Alert Setting Status" 16 "Navi Camera Alert Setting Status" 17 "Navi Camera Alert Setting Status" 18 "Navi Camera Alert Setting Status" 19 "Navi Camera Alert Setting Status" 20 "Navi Camera Alert Setting Status" 21 "Navi Camera Alert Setting Status" 22 "Navi Camera Alert Setting Status" 23 "Navi Camera Alert Setting Status" 24 "Navi Camera Alert Setting Status" 25 "Navi Camera Alert Setting Status" 26 "Navi Camera Alert Setting Status" 27 "Navi Camera Alert Setting Status" 28 "Navi Camera Alert Setting Status" 29 "Navi Camera Alert Setting Status" 30 "Navi Camera Alert Setting Status" 31 "Navi Camera Alert Setting Status" 32 "0x20~0xFE:Reserved" 254 "0x20~0xFE:Reserved" 255 "Invalid" ;
VAL_ 290 HU_OpState_New 0 "Initial" 1 "iBox App" 2 "Reserved" 3 "Reserved" 4 "Reserved" 5 "Reserved" 6 "ZUNE" 7 "Juke Box" 8 "Bluetooth Audio" 9 "Reserved" 10 "AV OFF" 11 "AV PowerOFF" 12 "MY music (ripping)" 13 "Internet Radio(Pandora)" 14 "Reserved" 15 "JukeBox-video" 16 "Aha Radio" 17 "FM" 18 "FM1" 19 "FM2" 20 "AM" 21 "Reserved" 22 "Reserved" 23 "Reserved" 24 "FMA" 25 "AMA" 26 "Emergency Call" 27 "ACN" 28 "Center Call" 29 "Hyundai Emergency Services" 30 "Kia Emergency Services" 31 "Reserved" 32 "Reserved" 33 "FM(HD)" 34 "FM1(HD)" 35 "FM2(HD)" 36 "AM(HD)" 37 "FMA_OLD(Use 0x18)" 38 "AMA_OLD(Use 0x19)" 39 "Reserved" 40 "Reserved" 41 "Reserved" 42 "Mozen Incoming call" 43 "Mozen Active call" 44 "Mozen Hangup" 45 "Mozen outgoing call" 46 "Reserved" 47 "Reserved" 48 "Reserved" 49 "SXM" 50 "XM1" 51 "XM2" 52 "XM3" 53 "Reserved" 54 "DAB" 55 "DAB1" 56 "DAB2" 57 "DAB3" 58 "Reserved" 59 "SXM Receiving" 60 "SXM Signal Weak" 61 "Reserved" 62 "DAB Receiving" 63 "DAB Signal Weak" 64 "Reserved" 65 "DMB1 TV" 66 "ISDB-T" 67 "Reserved" 68 "Reserved" 69 "DMB TV" 70 "DMB Radio" 71 "DMB Searching" 72 "Reserved" 73 "Reserved" 74 "Reserved" 75 "DMB Receiving" 76 "DMB Signal Weak" 77 "Reserved" 78 "Reserved" 79 "Reserved" 80 "CD" 81 "CD Audio" 82 "CD MP3" 83 "Mixed CD (Audio)" 84 "DVD" 85 "Reserved" 86 "Reserved" 87 "Reserved" 88 "Reserved" 89 "Disc reading" 90 "Mirror Link" 91 "Car Life" 92 "Reserved" 93 "READING CD" 94 "LOADING CD" 95 "Reserved" 96 "Loading" 97 "iPod" 98 "USB" 99 "AUX(Use 0x6B 0x6C Instead)" 100 "USB Video" 101 "USB Music" 102 "Rear USB Video" 103 "Rear USB Audio" 104 "IPOD Reading" 105 "USB Reading" 106 "Reading Media" 107 "AUX-audio" 108 "AUX-video" 109 "Reserved" 110 "CarPlay" 111 "Android Auto" 112 "Reserved" 113 "Incoming call" 114 "Active call" 115 "Hangup" 116 "Last Call" 117 "Reserved" 118 "Reserved" 119 "Reserved" 120 "Reserved" 121 "Reserved" 122 "BlueLink Mode" 123 "MOZEN Mode for cubis -T" 124 "RSA" 125 "Baidu Music" 126 "Reserved" 127 "Invalid" ;
VAL_ 290 HU_Frequency_Unit 0 "Off (Not Display)" 1 "On (Display)" 2 "Reserved" 3 "Invalid" ;
VAL_ 290 HU_User_Input 0 "Off" 1 "User Input" 2 "Reserved" 3 "Invalid" ;
VAL_ 290 HU_FMFrequency_Offset_Type 0 "Offset Type 1(8750)" 1 "Offset Type 2(6000)" 2 "Reserved" 3 "Invalid" ;
VAL_ 290 FM_Decimal_Point 0 "Off" 1 "1 Digit under point" 2 "2 Digits under point" 3 "Invalid" ;
VAL_ 290 HU_Track_Number_New 0 "0x0~0x327:Track No." 807 "0x0~0x327:Track No." 65535 "Invalid" ;
VAL_ 290 HU_Play_time_Sec_New 0 "0~59 sec." 1 "0~59 sec." 2 "0~59 sec." 3 "0~59 sec." 4 "0~59 sec." 5 "0~59 sec." 6 "0~59 sec." 7 "0~59 sec." 8 "0~59 sec." 9 "0~59 sec." 10 "0~59 sec." 11 "0~59 sec." 12 "0~59 sec." 13 "0~59 sec." 14 "0~59 sec." 15 "0~59 sec." 16 "0~59 sec." 17 "0~59 sec." 18 "0~59 sec." 19 "0~59 sec." 20 "0~59 sec." 21 "0~59 sec." 22 "0~59 sec." 23 "0~59 sec." 24 "0~59 sec." 25 "0~59 sec." 26 "0~59 sec." 27 "0~59 sec." 28 "0~59 sec." 29 "0~59 sec." 30 "0~59 sec." 31 "0~59 sec." 32 "0~59 sec." 33 "0~59 sec." 34 "0~59 sec." 35 "0~59 sec." 36 "0~59 sec." 37 "0~59 sec." 38 "0~59 sec." 39 "0~59 sec." 40 "0~59 sec." 41 "0~59 sec." 42 "0~59 sec." 43 "0~59 sec." 44 "0~59 sec." 45 "0~59 sec." 46 "0~59 sec." 47 "0~59 sec." 48 "0~59 sec." 49 "0~59 sec." 50 "0~59 sec." 51 "0~59 sec." 52 "0~59 sec." 53 "0~59 sec." 54 "0~59 sec." 55 "0~59 sec." 56 "0~59 sec." 57 "0~59 sec." 58 "0~59 sec." 59 "0~59 sec." 63 "Invalid" ;
VAL_ 290 HU_Play_time_Min_New 0 "0~59 min." 1 "0~59 min." 2 "0~59 min." 3 "0~59 min." 4 "0~59 min." 5 "0~59 min." 6 "0~59 min." 7 "0~59 min." 8 "0~59 min." 9 "0~59 min." 10 "0~59 min." 11 "0~59 min." 12 "0~59 min." 13 "0~59 min." 14 "0~59 min." 15 "0~59 min." 16 "0~59 min." 17 "0~59 min." 18 "0~59 min." 19 "0~59 min." 20 "0~59 min." 21 "0~59 min." 22 "0~59 min." 23 "0~59 min." 24 "0~59 min." 25 "0~59 min." 26 "0~59 min." 27 "0~59 min." 28 "0~59 min." 29 "0~59 min." 30 "0~59 min." 31 "0~59 min." 32 "0~59 min." 33 "0~59 min." 34 "0~59 min." 35 "0~59 min." 36 "0~59 min." 37 "0~59 min." 38 "0~59 min." 39 "0~59 min." 40 "0~59 min." 41 "0~59 min." 42 "0~59 min." 43 "0~59 min." 44 "0~59 min." 45 "0~59 min." 46 "0~59 min." 47 "0~59 min." 48 "0~59 min." 49 "0~59 min." 50 "0~59 min." 51 "0~59 min." 52 "0~59 min." 53 "0~59 min." 54 "0~59 min." 55 "0~59 min." 56 "0~59 min." 57 "0~59 min." 58 "0~59 min." 59 "0~59 min." 63 "Invalid" ;
VAL_ 290 HU_Play_time_Hour_New 0 "0~99 Hour" 1 "0~99 Hour" 2 "0~99 Hour" 3 "0~99 Hour" 4 "0~99 Hour" 5 "0~99 Hour" 6 "0~99 Hour" 7 "0~99 Hour" 8 "0~99 Hour" 9 "0~99 Hour" 10 "0~99 Hour" 11 "0~99 Hour" 12 "0~99 Hour" 13 "0~99 Hour" 14 "0~99 Hour" 15 "0~99 Hour" 16 "0~99 Hour" 17 "0~99 Hour" 18 "0~99 Hour" 19 "0~99 Hour" 20 "0~99 Hour" 21 "0~99 Hour" 22 "0~99 Hour" 23 "0~99 Hour" 24 "0~99 Hour" 25 "0~99 Hour" 26 "0~99 Hour" 27 "0~99 Hour" 28 "0~99 Hour" 29 "0~99 Hour" 30 "0~99 Hour" 31 "0~99 Hour" 32 "0~99 Hour" 33 "0~99 Hour" 34 "0~99 Hour" 35 "0~99 Hour" 36 "0~99 Hour" 37 "0~99 Hour" 38 "0~99 Hour" 39 "0~99 Hour" 40 "0~99 Hour" 41 "0~99 Hour" 42 "0~99 Hour" 43 "0~99 Hour" 44 "0~99 Hour" 45 "0~99 Hour" 46 "0~99 Hour" 47 "0~99 Hour" 48 "0~99 Hour" 49 "0~99 Hour" 50 "0~99 Hour" 51 "0~99 Hour" 52 "0~99 Hour" 53 "0~99 Hour" 54 "0~99 Hour" 55 "0~99 Hour" 56 "0~99 Hour" 57 "0~99 Hour" 58 "0~99 Hour" 59 "0~99 Hour" 60 "0~99 Hour" 61 "0~99 Hour" 62 "0~99 Hour" 63 "0~99 Hour" 64 "0~99 Hour" 65 "0~99 Hour" 66 "0~99 Hour" 67 "0~99 Hour" 68 "0~99 Hour" 69 "0~99 Hour" 70 "0~99 Hour" 71 "0~99 Hour" 72 "0~99 Hour" 73 "0~99 Hour" 74 "0~99 Hour" 75 "0~99 Hour" 76 "0~99 Hour" 77 "0~99 Hour" 78 "0~99 Hour" 79 "0~99 Hour" 80 "0~99 Hour" 81 "0~99 Hour" 82 "0~99 Hour" 83 "0~99 Hour" 84 "0~99 Hour" 85 "0~99 Hour" 86 "0~99 Hour" 87 "0~99 Hour" 88 "0~99 Hour" 89 "0~99 Hour" 90 "0~99 Hour" 91 "0~99 Hour" 92 "0~99 Hour" 93 "0~99 Hour" 94 "0~99 Hour" 95 "0~99 Hour" 96 "0~99 Hour" 97 "0~99 Hour" 98 "0~99 Hour" 99 "0~99 Hour" 127 "Invalid" ;
VAL_ 290 HU_Frequency_New 0 "0x0~0x1FFE:Refer to Signal Description" 8190 "0x0~0x1FFE:Refer to Signal Description" 8191 "invalid" ;
VAL_ 291 NV_Display_TG 0 "off" 1 "on" 2 "not used" 3 "invalid" ;
VAL_ 291 TBT_BarGraph100Level 0 "0x0~0x64:Physical value" 100 "0x0~0x64:Physical value" 254 "Not Displayed" 255 "initial value, invald" ;
VAL_ 286 Navi_WarnDist_OverDec 0 "0" 1 "0x1~0xFFFD:distance" 65533 "0x1~0xFFFD:distance" 65533 "no display over decimal point" 65535 "invalid" ;
VAL_ 286 Navi_WarnDist_UnderDec 0 "0" 1 "distance" 2 "distance" 3 "distance" 4 "distance" 5 "distance" 6 "distance" 7 "distance" 8 "distance" 9 "distance" 10 "reserved" 11 "reserved" 12 "reserved" 13 "reserved" 14 "no display under decimal point" 15 "invalid" ;
VAL_ 286 Navi_WarnDist_Scale 0 "m" 1 "km" 2 "mile" 3 "feet" 4 "yard" 5 "reserved" 6 "reserved" 7 "reserved" 8 "reserved" 9 "reserved" 10 "reserved" 11 "reserved" 12 "reserved" 13 "reserved" 14 "reserved" 15 "invalid" ;
VAL_ 56 C_DrvWindowOpenCmd 0 "No Action" 1 "Auto Down" 2 "Auto Up" 3 "Invalid" ;
VAL_ 56 C_AstWindowCmdAVN 0 "No Action" 1 "Auto Down" 2 "Auto Up" 3 "Invalid" ;
VAL_ 56 C_RLWindowCmdAVN 0 "No Action" 1 "Auto Down" 2 "Auto Up" 3 "Invalid" ;
VAL_ 56 C_RRWindowCmdAVN 0 "No Action" 1 "Auto Down" 2 "Auto Up" 3 "Invalid" ;
VAL_ 56 C_RrDefoggerCmdAVN 0 "Off" 1 "On" 2 "Reserved" 3 "Invalid" ;
VAL_ 56 C_StrgWhlHeatedCmdAVN 0 "Off" 1 "Heat 1st ON" 2 "Reserved" 3 "Invalid" ;
VAL_ 56 C_TrunkTlgtCmdAVN 0 "Off" 1 "Open(Release)" 2 "Reserved" 3 "Invalid" ;
VAL_ 56 C_PTGCNTLCmdAVN 0 "Close" 1 "Open" 2 "Reserved" 3 "Invalid" ;
VAL_ 56 C_AVNIMSButtonCmd 0 "Default" 1 "Memory P1 CMD" 2 "Memory P2 CMD" 3 "Memory P3 CMD" 4 "PBack P1 CMD" 5 "PBack P2 CMD" 6 "PBack P3 CMD" 7 "Invalid" ;
VAL_ 52 HU_DATC_DrTempUpDn 0 "Reserved" 1 "Temp Up" 2 "Temp Down" 3 "Invalid" ;
VAL_ 52 HU_DATC_MainBlower 0 "DATC Off" 1 "0 level (Do not use)" 2 "1 level" 3 "2 level" 4 "3 level" 5 "4 level" 6 "5 level" 7 "6 level" 8 "7 level" 9 "8 level" 15 "Invalid" ;
VAL_ 52 HU_DATC_FrontModeSet 0 "Reserved" 1 "VENT" 2 "BL" 3 "FLOOR" 4 "MIX" 5 "reserved" 6 "reserved" 7 "reserved" 8 "reserved" 9 "reserved" 10 "reserved" 11 "reserved" 12 "reserved" 13 "reserved" 14 "reserved" 15 "Invalid" ;
VAL_ 52 HU_DATC_AutoSet 0 "reserved" 1 "AUTO ON" 2 "reserved" 3 "Invalid" ;
VAL_ 52 HU_DATC_IntakeSet 0 "REC Off (Fresh On)" 1 "REC ON (Fresh Off" 2 "reserved" 3 "Invalid" ;
VAL_ 52 HU_DATC_AcSet 0 "AC Off" 1 "AC ON" 2 "reserved" 3 "Invalid" ;
VAL_ 52 HU_DATC_FrontDefog 0 "Defog Off" 1 "Defog On" 2 "reserved" 3 "Invalid" ;
VAL_ 52 DATC_ADSOnOffSet 0 "Function Off" 1 "Function On" 2 "reserved" 3 "Invalid" ;
VAL_ 52 HU_DATC_MainBlowerUpDn 0 "Reserved" 1 "Up" 2 "Down" 3 "Invalid" ;
VAL_ 52 HU_DATC_AirCleaningSet 0 "Air Cleaning System Off" 1 "Air Cleaning System On" 2 "Air Cleaning System Not Support" 3 "Invalid" ;
VAL_ 54 HU_DATC_DrTempSetC 0 "Blank" 1 "LO" 2 "PHY=HEX*0.5 + 14" 3 "PHY=HEX*0.5 + 14" 4 "PHY=HEX*0.5 + 14" 5 "PHY=HEX*0.5 + 14" 6 "PHY=HEX*0.5 + 14" 7 "PHY=HEX*0.5 + 14" 8 "PHY=HEX*0.5 + 14" 9 "PHY=HEX*0.5 + 14" 10 "PHY=HEX*0.5 + 14" 11 "PHY=HEX*0.5 + 14" 12 "PHY=HEX*0.5 + 14" 13 "PHY=HEX*0.5 + 14" 14 "PHY=HEX*0.5 + 14" 15 "PHY=HEX*0.5 + 14" 16 "PHY=HEX*0.5 + 14" 17 "PHY=HEX*0.5 + 14" 18 "PHY=HEX*0.5 + 14" 19 "PHY=HEX*0.5 + 14" 20 "PHY=HEX*0.5 + 14" 21 "PHY=HEX*0.5 + 14" 22 "PHY=HEX*0.5 + 14" 23 "PHY=HEX*0.5 + 14" 24 "PHY=HEX*0.5 + 14" 25 "PHY=HEX*0.5 + 14" 26 "PHY=HEX*0.5 + 14" 27 "PHY=HEX*0.5 + 14" 28 "PHY=HEX*0.5 + 14" 29 "PHY=HEX*0.5 + 14" 30 "PHY=HEX*0.5 + 14" 31 "PHY=HEX*0.5 + 14" 32 "PHY=HEX*0.5 + 14" 33 "PHY=HEX*0.5 + 14" 34 "PHY=HEX*0.5 + 14" 35 "PHY=HEX*0.5 + 14" 36 "PHY=HEX*0.5 + 14" 37 "0x25~0xFD:Reserved" 253 "0x25~0xFD:Reserved" 254 "HI" 255 "Invalid" ;
VAL_ 54 HU_DATC_DrTempSetF 0 "Blank" 1 "LO" 2 "PHY=HEX*1 + 56" 3 "PHY=HEX*1 + 56" 4 "PHY=HEX*1 + 56" 5 "PHY=HEX*1 + 56" 6 "PHY=HEX*1 + 56" 7 "PHY=HEX*1 + 56" 8 "PHY=HEX*1 + 56" 9 "PHY=HEX*1 + 56" 10 "PHY=HEX*1 + 56" 11 "PHY=HEX*1 + 56" 12 "PHY=HEX*1 + 56" 13 "PHY=HEX*1 + 56" 14 "PHY=HEX*1 + 56" 15 "PHY=HEX*1 + 56" 16 "PHY=HEX*1 + 56" 17 "PHY=HEX*1 + 56" 18 "PHY=HEX*1 + 56" 19 "PHY=HEX*1 + 56" 20 "PHY=HEX*1 + 56" 21 "PHY=HEX*1 + 56" 22 "PHY=HEX*1 + 56" 23 "PHY=HEX*1 + 56" 24 "PHY=HEX*1 + 56" 25 "PHY=HEX*1 + 56" 26 "PHY=HEX*1 + 56" 27 "PHY=HEX*1 + 56" 28 "PHY=HEX*1 + 56" 29 "PHY=HEX*1 + 56" 30 "PHY=HEX*1 + 56" 31 "PHY=HEX*1 + 56" 32 "PHY=HEX*1 + 56" 33 "PHY=HEX*1 + 56" 34 "PHY=HEX*1 + 56" 35 "PHY=HEX*1 + 56" 36 "PHY=HEX*1 + 56" 37 "0x25~0xFD:Reserved" 253 "0x25~0xFD:Reserved" 254 "HI" 255 "Invalid" ;
VAL_ 256 HU_Type 16 "AVN(Tuner DVD KOR)" 17 "AVN(Tuner DVD EUR)" 18 "AVN(Tuner DVD China)" 19 "AVN(Tuner DVD Japan)" 20 "AVN(Tuner DVD EUR)" 21 "AVN(Tuner CDP KOR)" 22 "AVN(Tuner CDP EUR)" 23 "AVN(Tuner CDP China)" 24 "AVN(Tuner CDP Japan)" 25 "AVN(Tuner CDP EUR)" 32 "AVNT (Open)" 33 "AVNT (Not open)" 48 "Economic Audio" 64 "Standard Audio (3.0 below)" 65 "Standard Audio 4.0" 66 "STD Audio-3.0Below,No interwork" 67 "Audio 4.0 Value" 80 "AV(Tuner DVD KOR)" 81 "AV(Tuner DVD EUR)" 82 "AV(Tuner DVD China)" 83 "AV(Tuner DVD Japan)" 84 "AV(Tuner DVD EUR)" 85 "AV(Tuner CDP KOR)" 86 "AV(Tuner CDP EUR)" 87 "AV(Tuner CDP China)" 88 "AV(Tuner CDP Japan)" 89 "AV(Tuner CDP EUR)" 96 "AVN 4.0" 97 "Premium AVN2.0" 98 "EU AVN 2.0" 99 "Super Premium w Navi" 100 "Super Premium w_o Navi" 101 "Premium w Navi" 102 "Premium w_o Navi" 103 "Display Audio w_o Navi" 104 "Integrated AVN 1.0 Mobis" 105 "Gen5 Standard Nav Wide" 112 "Compact AVN & Integrated AVN 1.0 LG" 128 "Premium Navi 5th Gen(w/Navi)" 129 "Premium Navi 5th Gen(w/o Navi)" 130 "Premium Navi 6th Gen(w/Navi)" 131 "Premium Navi 6th Gen(w/o Navi)" 250 "PIO AVN" 251 "China only OEM AV" 252 "China OPIO w/o CLU interface" 253 "China OPIO w/CLU interface" 255 "Invalid" ;
VAL_ 256 HU_DistributeInfo 0 "Default (Korea)" 1 "Korea" 2 "North America" 3 "Canada" 4 "East Europe" 5 "West Europe" 6 "China" 7 "India" 8 "Australia" 9 "Middle East" 10 "Africa" 11 "South America" 12 "Russia" 13 "Reserved" 14 "General" 15 "0x0F~0xFE:Reserved" 254 "0x0F~0xFE:Reserved" 255 "Invalid" ;
VAL_ 256 HU_OptionInfo 32768 "Invalid" ;
VAL_ 256 HU_AdasSupport 0 "Not Support" 1 "ADAS Support(General Map)" 2 "ADAS Support(Precise Map v1)" 3 "ADAS Support(Precise Map v2)" 4 "Reserved" 5 "Reserved" 6 "Reserved" 7 "Invalid" ;
VAL_ 206 META_MapProvider 0 "Unknown" 1 "NAVTEQ" 2 "TeleAtlas" 3 "Zenrin" 4 "HMNS" 5 "Reserved" 6 "Reserved" 7 "Invalid" ;
VAL_ 206 META_MessageType 0 "Reserved" 1 "Position" 2 "Segment" 3 "Stub" 4 "Profile Short" 5 "Profile Long" 6 "Meta Data" 7 "Invalid" ;
VAL_ 206 META_CountryCode 0 "Unknown" 1 "0x1~0x3FE:ISO 3166-1 numeric values" 1022 "0x1~0x3FE:ISO 3166-1 numeric values" 1023 "Invalid" ;
VAL_ 206 META_MinorProtocolSubVer 0 "Minor sub-version value" 1 "Minor sub-version value" 2 "Minor sub-version value" 3 "Minor sub-version value" 4 "Minor sub-version value" 5 "Minor sub-version value" 6 "Minor sub-version value" 7 "Minor sub-version value" ;
VAL_ 206 META_MajorProtocolVersion 0 "Major version value" 1 "Major version value" 2 "Major version value" 3 "Major version value" ;
VAL_ 206 META_CyclicCounter 0 "Cyclic Counter" 1 "Cyclic Counter" 2 "Cyclic Counter" 3 "Cyclic Counter" ;
VAL_ 206 META_HardwareVersion 0 "Unknown" 1 "0x1~0x1FE:Hardware version value" 510 "0x1~0x1FE:Hardware version value" 511 "Invalid" ;
VAL_ 206 META_DrivingSide 0 "Driving Side Left" 1 "Driving Side Right" ;
VAL_ 206 META_RegionCode 0 "Unknown" 1 "0x1~0x7FFE:ISO 3166-2 values" 32766 "0x1~0x7FFE:ISO 3166-2 values" 32767 "Invalid" ;
VAL_ 206 META_MapVersionYear 0 "Year" 1 "Year" 2 "Year" 3 "Year" 4 "Year" 5 "Year" 6 "Year" 7 "Year" 8 "Year" 9 "Year" 10 "Year" 11 "Year" 12 "Year" 13 "Year" 14 "Year" 15 "Year" 16 "Year" 17 "Year" 18 "Year" 19 "Year" 20 "Year" 21 "Year" 22 "Year" 23 "Year" 24 "Year" 25 "Year" 26 "Year" 27 "Year" 28 "Year" 29 "Year" 30 "Year" 31 "Year" 32 "Year" 33 "Year" 34 "Year" 35 "Year" 36 "Year" 37 "Year" 38 "Year" 39 "Year" 40 "Year" 41 "Year" 42 "Year" 43 "Year" 44 "Year" 45 "Year" 46 "Year" 47 "Year" 48 "Year" 49 "Year" 50 "Year" 51 "Year" 52 "Year" 53 "Year" 54 "Year" 55 "Year" 56 "Year" 57 "Year" 58 "Year" 59 "Year" 60 "Year" 61 "Year" 62 "Year" 63 "Invalid" ;
VAL_ 206 META_MapVersionQuarter 0 "Q1" 1 "Q2" 2 "Q3" 3 "Q4" ;
VAL_ 206 META_MinorProtocolVersion 0 "Minor version value" 1 "Minor version value" 2 "Minor version value" 3 "Minor version value" 4 "Minor version value" 5 "Minor version value" 6 "Minor version value" 7 "Minor version value" 8 "Minor version value" 9 "Minor version value" 10 "Minor version value" 11 "Minor version value" 12 "Minor version value" 13 "Minor version value" 14 "Minor version value" 15 "Minor version value" ;
VAL_ 206 META_SpeedUnit 0 "Kilometers per hour" 1 "Mile per hour" ;
VAL_ 205 PROLONG_Value 0 "0x0~0xFFFFFFFE:Profile value at Offset" 2147483647 "0x0~0xFFFFFFFE:Profile value at Offset" 2147483647 "Invalid" ;
VAL_ 205 PROLONG_MessageType 0 "Reserved" 1 "Position" 2 "Segment" 3 "Stub" 4 "Profile Short" 5 "Profile Long" 6 "Meta Data" 7 "Invalid" ;
VAL_ 205 PROLONG_Offset 0 "0x0~0x1FFE:Distance" 8190 "0x0~0x1FFE:Distance" 8191 "Invalid" ;
VAL_ 205 PROLONG_PathIndex 0 "Unknown" 1 "Reserved" 2 "Reserved" 3 "Reserved" 4 "Reserved" 5 "Reserved" 6 "Reserved" 7 "Reserved" 8 "General Path Index" 9 "General Path Index" 10 "General Path Index" 11 "General Path Index" 12 "General Path Index" 13 "General Path Index" 14 "General Path Index" 15 "General Path Index" 16 "General Path Index" 17 "General Path Index" 18 "General Path Index" 19 "General Path Index" 20 "General Path Index" 21 "General Path Index" 22 "General Path Index" 23 "General Path Index" 24 "General Path Index" 25 "General Path Index" 26 "General Path Index" 27 "General Path Index" 28 "General Path Index" 29 "General Path Index" 30 "General Path Index" 31 "General Path Index" 32 "General Path Index" 33 "General Path Index" 34 "General Path Index" 35 "General Path Index" 36 "General Path Index" 37 "General Path Index" 38 "General Path Index" 39 "General Path Index" 40 "General Path Index" 41 "General Path Index" 42 "General Path Index" 43 "General Path Index" 44 "General Path Index" 45 "General Path Index" 46 "General Path Index" 47 "General Path Index" 48 "General Path Index" 49 "General Path Index" 50 "General Path Index" 51 "General Path Index" 52 "General Path Index" 53 "General Path Index" 54 "General Path Index" 55 "General Path Index" 56 "General Path Index" 57 "General Path Index" 58 "General Path Index" 59 "General Path Index" 60 "General Path Index" 61 "General Path Index" 62 "General Path Index" 63 "General Path Index" ;
VAL_ 205 PROLONG_CyclicCounter 0 "Cyclic Counter" 1 "Cyclic Counter" 2 "Cyclic Counter" 3 "Cyclic Counter" ;
VAL_ 205 PROLONG_Update 0 "False" 1 "True" ;
VAL_ 205 PROLONG_Retransmission 0 "False" 1 "True" ;
VAL_ 205 PROLONG_CountrolPoint 0 "False" 1 "True" ;
VAL_ 205 PROLONG_ProfileType 0 "Invalid" 1 "Longitude" 2 "Latitude" 3 "Altitude" 4 "Control Point Longitude(Bezier)" 5 "Control Point Latitude(Bezier)" 6 "Control Point Altitude(Bezier)" 7 "Link Identifier" 8 "Traffic Sign" 9 "Reserved for standard type" 10 "Reserved for standard type" 11 "Reserved for standard type" 12 "Reserved for standard type" 13 "Reserved for standard type" 14 "Reserved for standard type" 15 "Reserved for standard type" 16 "Alert Information Spot" 17 "Reserved for system specific types" 18 "Reserved for system specific types" 19 "Reserved for system specific types" 20 "Reserved for system specific types" 21 "Reserved for system specific types" 22 "Reserved for system specific types" 23 "Reserved for system specific types" 24 "Reserved for system specific types" 25 "Reserved for system specific types" 26 "Reserved for system specific types" 27 "Reserved for system specific types" 28 "Reserved for system specific types" 29 "Reserved for system specific types" 30 "Reserved for system specific types" 31 "Reserved for system specific types" ;
VAL_ 204 PROSHORT_MessageType 0 "Reserved" 1 "Position" 2 "Segment" 3 "Stub" 4 "Profile Short" 5 "Profile Long" 6 "Meta Data" 7 "Invalid" ;
VAL_ 204 PROSHORT_Offset 0 "0x0~0x1FFE:Distance" 8190 "0x0~0x1FFE:Distance" 8191 "Invalid" ;
VAL_ 204 PROSHORT_PathIndex 0 "Unknown" 1 "Reserved" 2 "Reserved" 3 "Reserved" 4 "Reserved" 5 "Reserved" 6 "Reserved" 7 "Reserved" 8 "General Path Index" 9 "General Path Index" 10 "General Path Index" 11 "General Path Index" 12 "General Path Index" 13 "General Path Index" 14 "General Path Index" 15 "General Path Index" 16 "General Path Index" 17 "General Path Index" 18 "General Path Index" 19 "General Path Index" 20 "General Path Index" 21 "General Path Index" 22 "General Path Index" 23 "General Path Index" 24 "General Path Index" 25 "General Path Index" 26 "General Path Index" 27 "General Path Index" 28 "General Path Index" 29 "General Path Index" 30 "General Path Index" 31 "General Path Index" 32 "General Path Index" 33 "General Path Index" 34 "General Path Index" 35 "General Path Index" 36 "General Path Index" 37 "General Path Index" 38 "General Path Index" 39 "General Path Index" 40 "General Path Index" 41 "General Path Index" 42 "General Path Index" 43 "General Path Index" 44 "General Path Index" 45 "General Path Index" 46 "General Path Index" 47 "General Path Index" 48 "General Path Index" 49 "General Path Index" 50 "General Path Index" 51 "General Path Index" 52 "General Path Index" 53 "General Path Index" 54 "General Path Index" 55 "General Path Index" 56 "General Path Index" 57 "General Path Index" 58 "General Path Index" 59 "General Path Index" 60 "General Path Index" 61 "General Path Index" 62 "General Path Index" 63 "General Path Index" ;
VAL_ 204 PROSHORT_CyclicCounter 0 "Cyclic Counter" 1 "Cyclic Counter" 2 "Cyclic Counter" 3 "Cyclic Counter" ;
VAL_ 204 PROSHORT_Accuracy 0 "High Accuracy" 1 "Middle Accuracy" 2 "Low Accuracy" 3 "Unknown" ;
VAL_ 204 PROSHORT_Distance 0 "0x0~0x3FE:Distance" 1022 "0x0~0x3FE:Distance" 1023 "Invalid" ;
VAL_ 204 PROSHORT_Value0 0 "0x0~0x3FE:Profile Vaue at Offset" 1022 "0x0~0x3FE:Profile Vaue at Offset" 1023 "Invalid" ;
VAL_ 204 PROSHORT_Value1 0 "0x0~0x3FE:Profile value at Offset+Distance1" 1022 "0x0~0x3FE:Profile value at Offset+Distance1" 1023 "Invalid" ;
VAL_ 204 PROSHORT_Update 0 "False" 1 "True" ;
VAL_ 204 PROSHORT_Retransmission 0 "False" 1 "True" ;
VAL_ 204 PROSHORT_ControlPoint 0 "False" 1 "True" ;
VAL_ 204 PROSHORT_ProfileType 0 "Invalid" 1 "Curvature" 2 "Route Number types" 3 "Slope(step)" 4 "Slope(Linear)" 5 "Road Accessibility" 6 "Road condition" 7 "Variable Speed Sign Position" 8 "Heading Change" 9 "Reserved for standard type" 10 "Reserved for standard type" 11 "Reserved for standard type" 12 "Reserved for standard type" 13 "Reserved for standard type" 14 "Reserved for standard type" 15 "Reserved for standard type" 16 "Alert Information Section" 17 "Slope Average Speed" 18 "Reserved for system specific types" 19 "Reserved for system specific types" 20 "Reserved for system specific types" 21 "Reserved for system specific types" 22 "Reserved for system specific types" 23 "Reserved for system specific types" 24 "Reserved for system specific types" 25 "Reserved for system specific types" 26 "Reserved for system specific types" 27 "Reserved for system specific types" 28 "Reserved for system specific types" 29 "Reserved for system specific types" 30 "Reserved for system specific types" 31 "Reserved for system specific types" ;
VAL_ 207 PROSHORT_MessageType_01 0 "Reserved" 1 "Position" 2 "Segment" 3 "Stub" 4 "Profile Short" 5 "Profile Long" 6 "Meta Data" 7 "Invalid" ;
VAL_ 207 PROSHORT_Offset_01 0 "0x0~0x1FFE:Distance" 8190 "0x0~0x1FFE:Distance" 8191 "Invalid" ;
VAL_ 207 PROSHORT_PathIndex_01 0 "Unknown" 1 "Reserved" 2 "Reserved" 3 "Reserved" 4 "Reserved" 5 "Reserved" 6 "Reserved" 7 "Reserved" 8 "General Path Index" 9 "General Path Index" 10 "General Path Index" 11 "General Path Index" 12 "General Path Index" 13 "General Path Index" 14 "General Path Index" 15 "General Path Index" 16 "General Path Index" 17 "General Path Index" 18 "General Path Index" 19 "General Path Index" 20 "General Path Index" 21 "General Path Index" 22 "General Path Index" 23 "General Path Index" 24 "General Path Index" 25 "General Path Index" 26 "General Path Index" 27 "General Path Index" 28 "General Path Index" 29 "General Path Index" 30 "General Path Index" 31 "General Path Index" 32 "General Path Index" 33 "General Path Index" 34 "General Path Index" 35 "General Path Index" 36 "General Path Index" 37 "General Path Index" 38 "General Path Index" 39 "General Path Index" 40 "General Path Index" 41 "General Path Index" 42 "General Path Index" 43 "General Path Index" 44 "General Path Index" 45 "General Path Index" 46 "General Path Index" 47 "General Path Index" 48 "General Path Index" 49 "General Path Index" 50 "General Path Index" 51 "General Path Index" 52 "General Path Index" 53 "General Path Index" 54 "General Path Index" 55 "General Path Index" 56 "General Path Index" 57 "General Path Index" 58 "General Path Index" 59 "General Path Index" 60 "General Path Index" 61 "General Path Index" 62 "General Path Index" 63 "General Path Index" ;
VAL_ 207 PROSHORT_CyclicCounter_01 0 "Cyclic Counter" 1 "Cyclic Counter" 2 "Cyclic Counter" 3 "Cyclic Counter" ;
VAL_ 207 PROSHORT_Accuracy_01 0 "High Accuracy" 1 "Middle Accuracy" 2 "Low Accuracy" 3 "Unknown" ;
VAL_ 207 PROSHORT_Distance_01 0 "0x0~0x3FE:Distance" 1022 "0x0~0x3FE:Distance" 1023 "Invalid" ;
VAL_ 207 PROSHORT_Value0_01 0 "0x0~0x3FE:Profile Vaue at Offset" 1022 "0x0~0x3FE:Profile Vaue at Offset" 1023 "Invalid" ;
VAL_ 207 PROSHORT_Value1_01 0 "0x0~0x3FE:Profile value at Offset+Distance1" 1022 "0x0~0x3FE:Profile value at Offset+Distance1" 1023 "Invalid" ;
VAL_ 207 PROSHORT_Update_01 0 "False" 1 "True" ;
VAL_ 207 PROSHORT_Retransmission_01 0 "False" 1 "True" ;
VAL_ 207 PROSHORT_ControlPoint_01 0 "False" 1 "True" ;
VAL_ 207 PROSHORT_ProfileType_01 0 "Invalid" 1 "Curvature" 2 "Route Number types" 3 "Slope(step)" 4 "Slope(Linear)" 5 "Road Accessibility" 6 "Road condition" 7 "Variable Speed Sign Position" 8 "Heading Change" 9 "Reserved for standard type" 10 "Reserved for standard type" 11 "Reserved for standard type" 12 "Reserved for standard type" 13 "Reserved for standard type" 14 "Reserved for standard type" 15 "Reserved for standard type" 16 "Alert Information Section" 17 "Slope Average Speed" 18 "Reserved for system specific types" 19 "Reserved for system specific types" 20 "Reserved for system specific types" 21 "Reserved for system specific types" 22 "Reserved for system specific types" 23 "Reserved for system specific types" 24 "Reserved for system specific types" 25 "Reserved for system specific types" 26 "Reserved for system specific types" 27 "Reserved for system specific types" 28 "Reserved for system specific types" 29 "Reserved for system specific types" 30 "Reserved for system specific types" 31 "Reserved for system specific types" ;
